VERSION "created by canmatrix"

NS_ :

BS_:

BU_: BDC_Body CHC DME1 EME FLA NiVi ZGW Kombi Kombi_Basis Diagnosetool_FA_CAN CDC_ZGW DME2 ELV Gliwa_T1_Host FA_CAN_Dummy

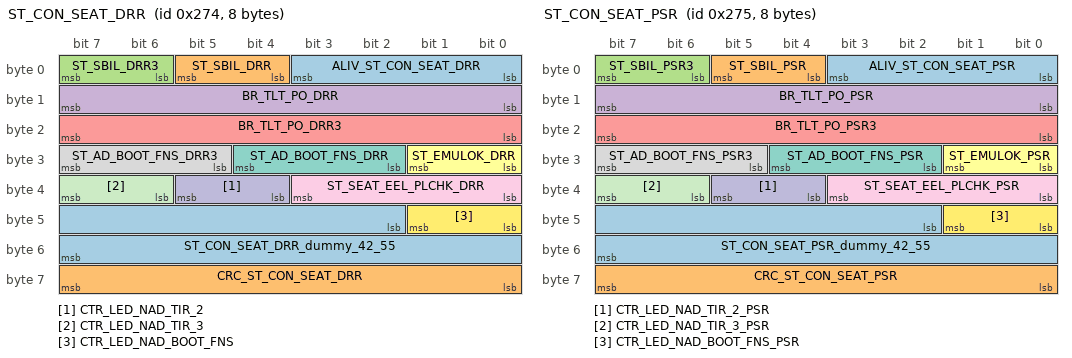
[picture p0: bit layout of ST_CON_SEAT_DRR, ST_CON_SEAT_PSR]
BO_ 628 ST_CON_SEAT_DRR: 8 ZGW
 SG_ ALIV_ST_CON_SEAT_DRR : 0|4@1+ (1,0) [0|14] "This unit fulfills the required AUTOSAR reference to a unit. No real unit is defined." Vector__XXX
 SG_ ST_SBIL_DRR : 4|2@1+ (1,0) [0|3] "" Vector__XXX
 SG_ ST_SBIL_DRR3 : 6|2@1+ (1,0) [0|3] "" Vector__XXX
 SG_ BR_TLT_PO_DRR : 8|8@1+ (1,0) [0|150] "%" Vector__XXX
 SG_ BR_TLT_PO_DRR3 : 16|8@1+ (1,0) [0|150] "%" Vector__XXX
 SG_ ST_EMULOK_DRR : 24|2@1+ (1,0) [0|3] "" Vector__XXX
 SG_ ST_AD_BOOT_FNS_DRR : 26|3@1+ (1,0) [0|7] "" Vector__XXX
 SG_ ST_AD_BOOT_FNS_DRR3 : 29|3@1+ (1,0) [0|7] "" Vector__XXX
 SG_ ST_SEAT_EEL_PLCHK_DRR : 32|4@1+ (1,0) [0|15] "" Vector__XXX
 SG_ CTR_LED_NAD_TIR_2 : 36|2@1+ (1,0) [0|3] "" Vector__XXX
 SG_ CTR_LED_NAD_TIR_3 : 38|2@1+ (1,0) [0|3] "" Vector__XXX
 SG_ CTR_LED_NAD_BOOT_FNS : 40|2@1+ (1,0) [0|3] "" Vector__XXX
 SG_ ST_CON_SEAT_DRR_dummy_42_55 : 42|14@1+ (1,0) [-8192|8191] "" Vector__XXX
 SG_ CRC_ST_CON_SEAT_DRR : 56|8@1+ (1,0) [0|255] "This unit fulfills the required AUTOSAR reference to a unit. No real unit is defined." Vector__XXX

BO_ 629 ST_CON_SEAT_PSR: 8 ZGW
 SG_ ALIV_ST_CON_SEAT_PSR : 0|4@1+ (1,0) [0|14] "This unit fulfills the required AUTOSAR reference to a unit. No real unit is defined." Vector__XXX
 SG_ ST_SBIL_PSR : 4|2@1+ (1,0) [0|3] "" Vector__XXX
 SG_ ST_SBIL_PSR3 : 6|2@1+ (1,0) [0|3] "" Vector__XXX
 SG_ BR_TLT_PO_PSR : 8|8@1+ (1,0) [0|150] "%" Vector__XXX
 SG_ BR_TLT_PO_PSR3 : 16|8@1+ (1,0) [0|150] "%" Vector__XXX
 SG_ ST_EMULOK_PSR : 24|2@1+ (1,0) [0|3] "" Vector__XXX
 SG_ ST_AD_BOOT_FNS_PSR : 26|3@1+ (1,0) [0|7] "" Vector__XXX
 SG_ ST_AD_BOOT_FNS_PSR3 : 29|3@1+ (1,0) [0|7] "" Vector__XXX
 SG_ ST_SEAT_EEL_PLCHK_PSR : 32|4@1+ (1,0) [0|15] "" Vector__XXX
 SG_ CTR_LED_NAD_TIR_2_PSR : 36|2@1+ (1,0) [0|3] "" Vector__XXX
 SG_ CTR_LED_NAD_TIR_3_PSR : 38|2@1+ (1,0) [0|3] "" Vector__XXX
 SG_ CTR_LED_NAD_BOOT_FNS_PSR : 40|2@1+ (1,0) [0|3] "" Vector__XXX
 SG_ ST_CON_SEAT_PSR_dummy_42_55 : 42|14@1+ (1,0) [-8192|8191] "" Vector__XXX
 SG_ CRC_ST_CON_SEAT_PSR : 56|8@1+ (1,0) [0|255] "This unit fulfills the required AUTOSAR reference to a unit. No real unit is defined." Vector__XXX

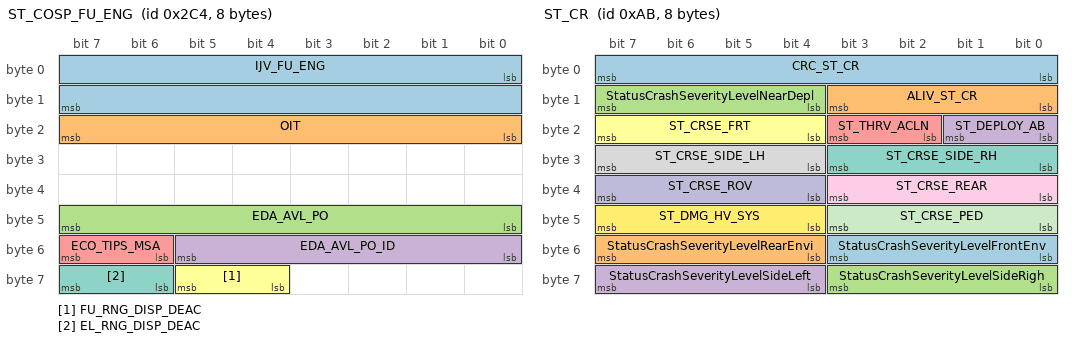
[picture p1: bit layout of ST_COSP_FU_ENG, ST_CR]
BO_ 708 ST_COSP_FU_ENG: 8 DME1
 SG_ IJV_FU_ENG : 0|16@1+ (1,0) [0|65534] "µl" CDC_ZGW,Kombi,Kombi_Basis,ZGW
 SG_ OIT : 16|8@1+ (0.5,0) [0|50] "%" ZGW,Kombi,Kombi_Basis
 SG_ EDA_AVL_PO : 40|8@1+ (1,-100) [-200|0] "%" Kombi,Kombi_Basis
 SG_ EDA_AVL_PO_ID : 48|6@1+ (1,0) [0|63] "" Kombi,Kombi_Basis
 SG_ ECO_TIPS_MSA : 54|2@1+ (1,0) [0|3] "" Kombi,Kombi_Basis
 SG_ FU_RNG_DISP_DEAC : 60|2@1+ (1,0) [0|3] "" Kombi
 SG_ EL_RNG_DISP_DEAC : 62|2@1+ (1,0) [0|3] "" Kombi

BO_ 171 ST_CR: 8 ZGW
 SG_ CRC_ST_CR : 0|8@1+ (1,0) [0|255] "This unit fulfills the required AUTOSAR reference to a unit. No real unit is defined." Vector__XXX
 SG_ ALIV_ST_CR : 8|4@1+ (1,0) [0|14] "This unit fulfills the required AUTOSAR reference to a unit. No real unit is defined." Vector__XXX
 SG_ StatusCrashSeverityLevelNearDepl : 12|4@1+ (1,0) [0|15] "" Vector__XXX
 SG_ ST_DEPLOY_AB : 16|2@1+ (1,0) [0|3] "" Vector__XXX
 SG_ ST_THRV_ACLN : 18|2@1+ (1,0) [0|3] "" Vector__XXX
 SG_ ST_CRSE_FRT : 20|4@1+ (1,0) [0|15] "" Vector__XXX
 SG_ ST_CRSE_SIDE_RH : 24|4@1+ (1,0) [0|15] "" Vector__XXX
 SG_ ST_CRSE_SIDE_LH : 28|4@1+ (1,0) [0|15] "" Vector__XXX
 SG_ ST_CRSE_REAR : 32|4@1+ (1,0) [0|15] "" Vector__XXX
 SG_ ST_CRSE_ROV : 36|4@1+ (1,0) [0|15] "" Vector__XXX
 SG_ ST_CRSE_PED : 40|4@1+ (1,0) [0|15] "" Vector__XXX
 SG_ ST_DMG_HV_SYS : 44|4@1+ (1,0) [0|15] "" Vector__XXX
 SG_ StatusCrashSeverityLevelFrontEnv : 48|4@1+ (1,0) [0|15] "" Vector__XXX
 SG_ StatusCrashSeverityLevelRearEnvi : 52|4@1+ (1,0) [0|15] "" Vector__XXX
 SG_ StatusCrashSeverityLevelSideRigh : 56|4@1+ (1,0) [0|15] "" Vector__XXX
 SG_ StatusCrashSeverityLevelSideLeft : 60|4@1+ (1,0) [0|15] "" Vector__XXX

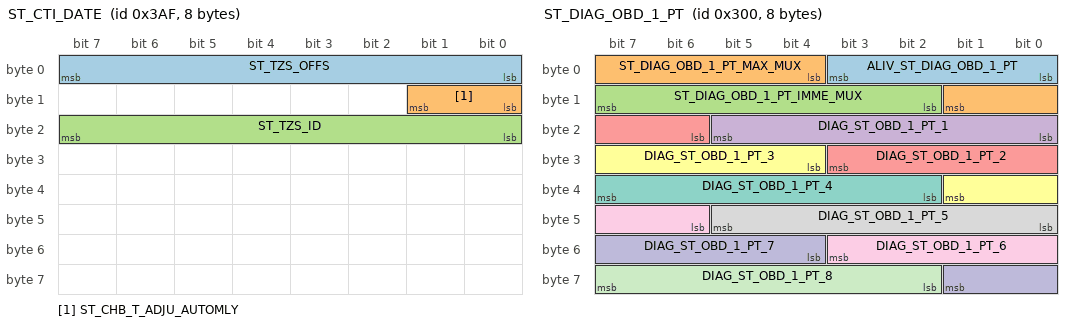
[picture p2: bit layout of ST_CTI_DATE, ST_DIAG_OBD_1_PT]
BO_ 943 ST_CTI_DATE: 8 Kombi
 SG_ ST_TZS_OFFS : 0|8@1+ (0.25,-20) [-25.00|-9.25] "h" ZGW
 SG_ ST_CHB_T_ADJU_AUTOMLY : 8|2@1+ (1,0) [0|3] "" ZGW
 SG_ ST_TZS_ID : 16|8@1+ (1,0) [0|251] "This unit fulfills the required AUTOSAR reference to a unit. No real unit is defined." ZGW

BO_ 768 ST_DIAG_OBD_1_PT: 8 ZGW
 SG_ ALIV_ST_DIAG_OBD_1_PT : 0|4@1+ (1,0) [0|14] "This unit fulfills the required AUTOSAR reference to a unit. No real unit is defined." Vector__XXX
 SG_ ST_DIAG_OBD_1_PT_MAX_MUX : 4|6@1+ (1,0) [4|60] "This unit fulfills the required AUTOSAR reference to a unit. No real unit is defined." Vector__XXX
 SG_ ST_DIAG_OBD_1_PT_IMME_MUX : 10|6@1+ (1,0) [0|60] "This unit fulfills the required AUTOSAR reference to a unit. No real unit is defined." Vector__XXX
 SG_ DIAG_ST_OBD_1_PT_1 : 16|6@1+ (1,0) [0|63] "This unit fulfills the required AUTOSAR reference to a unit. No real unit is defined." Vector__XXX
 SG_ DIAG_ST_OBD_1_PT_2 : 22|6@1+ (1,0) [0|63] "This unit fulfills the required AUTOSAR reference to a unit. No real unit is defined." Vector__XXX
 SG_ DIAG_ST_OBD_1_PT_3 : 28|6@1+ (1,0) [0|63] "This unit fulfills the required AUTOSAR reference to a unit. No real unit is defined." Vector__XXX
 SG_ DIAG_ST_OBD_1_PT_4 : 34|6@1+ (1,0) [0|63] "This unit fulfills the required AUTOSAR reference to a unit. No real unit is defined." Vector__XXX
 SG_ DIAG_ST_OBD_1_PT_5 : 40|6@1+ (1,0) [0|63] "This unit fulfills the required AUTOSAR reference to a unit. No real unit is defined." Vector__XXX
 SG_ DIAG_ST_OBD_1_PT_6 : 46|6@1+ (1,0) [0|63] "This unit fulfills the required AUTOSAR reference to a unit. No real unit is defined." Vector__XXX
 SG_ DIAG_ST_OBD_1_PT_7 : 52|6@1+ (1,0) [0|63] "This unit fulfills the required AUTOSAR reference to a unit. No real unit is defined." Vector__XXX
 SG_ DIAG_ST_OBD_1_PT_8 : 58|6@1+ (1,0) [0|63] "This unit fulfills the required AUTOSAR reference to a unit. No real unit is defined." Vector__XXX

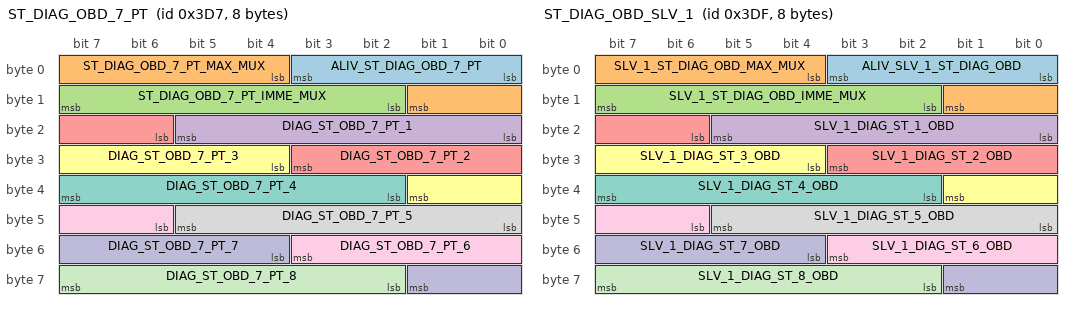
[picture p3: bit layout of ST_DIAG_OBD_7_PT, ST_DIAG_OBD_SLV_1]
BO_ 983 ST_DIAG_OBD_7_PT: 8 BDC_Body
 SG_ ALIV_ST_DIAG_OBD_7_PT : 0|4@1+ (1,0) [0|14] "This unit fulfills the required AUTOSAR reference to a unit. No real unit is defined." Vector__XXX
 SG_ ST_DIAG_OBD_7_PT_MAX_MUX : 4|6@1+ (1,0) [4|60] "This unit fulfills the required AUTOSAR reference to a unit. No real unit is defined." Vector__XXX
 SG_ ST_DIAG_OBD_7_PT_IMME_MUX : 10|6@1+ (1,0) [0|60] "This unit fulfills the required AUTOSAR reference to a unit. No real unit is defined." Vector__XXX
 SG_ DIAG_ST_OBD_7_PT_1 : 16|6@1+ (1,0) [0|63] "This unit fulfills the required AUTOSAR reference to a unit. No real unit is defined." Vector__XXX
 SG_ DIAG_ST_OBD_7_PT_2 : 22|6@1+ (1,0) [0|63] "This unit fulfills the required AUTOSAR reference to a unit. No real unit is defined." Vector__XXX
 SG_ DIAG_ST_OBD_7_PT_3 : 28|6@1+ (1,0) [0|63] "This unit fulfills the required AUTOSAR reference to a unit. No real unit is defined." Vector__XXX
 SG_ DIAG_ST_OBD_7_PT_4 : 34|6@1+ (1,0) [0|63] "This unit fulfills the required AUTOSAR reference to a unit. No real unit is defined." Vector__XXX
 SG_ DIAG_ST_OBD_7_PT_5 : 40|6@1+ (1,0) [0|63] "This unit fulfills the required AUTOSAR reference to a unit. No real unit is defined." Vector__XXX
 SG_ DIAG_ST_OBD_7_PT_6 : 46|6@1+ (1,0) [0|63] "This unit fulfills the required AUTOSAR reference to a unit. No real unit is defined." Vector__XXX
 SG_ DIAG_ST_OBD_7_PT_7 : 52|6@1+ (1,0) [0|63] "This unit fulfills the required AUTOSAR reference to a unit. No real unit is defined." Vector__XXX
 SG_ DIAG_ST_OBD_7_PT_8 : 58|6@1+ (1,0) [0|63] "This unit fulfills the required AUTOSAR reference to a unit. No real unit is defined." Vector__XXX

BO_ 991 ST_DIAG_OBD_SLV_1: 8 ZGW
 SG_ ALIV_SLV_1_ST_DIAG_OBD : 0|4@1+ (1,0) [0|14] "This unit fulfills the required AUTOSAR reference to a unit. No real unit is defined." Vector__XXX
 SG_ SLV_1_ST_DIAG_OBD_MAX_MUX : 4|6@1+ (1,0) [4|60] "This unit fulfills the required AUTOSAR reference to a unit. No real unit is defined." Vector__XXX
 SG_ SLV_1_ST_DIAG_OBD_IMME_MUX : 10|6@1+ (1,0) [4|60] "This unit fulfills the required AUTOSAR reference to a unit. No real unit is defined." Vector__XXX
 SG_ SLV_1_DIAG_ST_1_OBD : 16|6@1+ (1,0) [0|63] "This unit fulfills the required AUTOSAR reference to a unit. No real unit is defined." Vector__XXX
 SG_ SLV_1_DIAG_ST_2_OBD : 22|6@1+ (1,0) [0|63] "This unit fulfills the required AUTOSAR reference to a unit. No real unit is defined." Vector__XXX
 SG_ SLV_1_DIAG_ST_3_OBD : 28|6@1+ (1,0) [0|63] "This unit fulfills the required AUTOSAR reference to a unit. No real unit is defined." Vector__XXX
 SG_ SLV_1_DIAG_ST_4_OBD : 34|6@1+ (1,0) [0|63] "This unit fulfills the required AUTOSAR reference to a unit. No real unit is defined." Vector__XXX
 SG_ SLV_1_DIAG_ST_5_OBD : 40|6@1+ (1,0) [0|63] "This unit fulfills the required AUTOSAR reference to a unit. No real unit is defined." Vector__XXX
 SG_ SLV_1_DIAG_ST_6_OBD : 46|6@1+ (1,0) [0|63] "This unit fulfills the required AUTOSAR reference to a unit. No real unit is defined." Vector__XXX
 SG_ SLV_1_DIAG_ST_7_OBD : 52|6@1+ (1,0) [0|63] "This unit fulfills the required AUTOSAR reference to a unit. No real unit is defined." Vector__XXX
 SG_ SLV_1_DIAG_ST_8_OBD : 58|6@1+ (1,0) [0|63] "This unit fulfills the required AUTOSAR reference to a unit. No real unit is defined." Vector__XXX

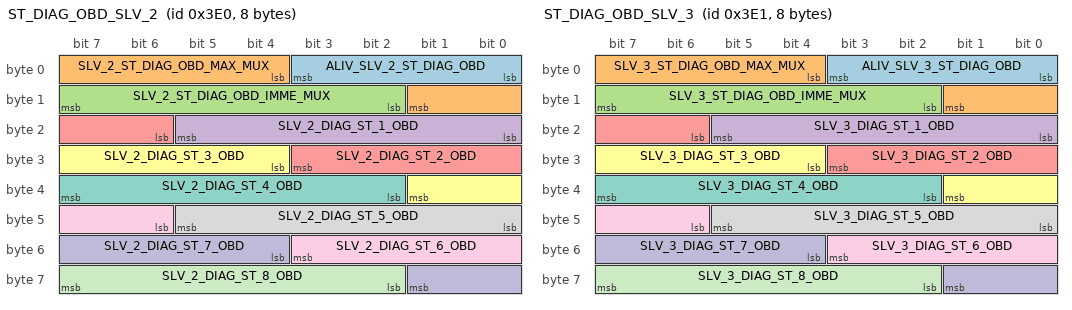
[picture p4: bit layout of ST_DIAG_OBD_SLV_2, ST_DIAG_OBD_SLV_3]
BO_ 992 ST_DIAG_OBD_SLV_2: 8 ZGW
 SG_ ALIV_SLV_2_ST_DIAG_OBD : 0|4@1+ (1,0) [0|14] "This unit fulfills the required AUTOSAR reference to a unit. No real unit is defined." Vector__XXX
 SG_ SLV_2_ST_DIAG_OBD_MAX_MUX : 4|6@1+ (1,0) [4|60] "This unit fulfills the required AUTOSAR reference to a unit. No real unit is defined." Vector__XXX
 SG_ SLV_2_ST_DIAG_OBD_IMME_MUX : 10|6@1+ (1,0) [4|60] "This unit fulfills the required AUTOSAR reference to a unit. No real unit is defined." Vector__XXX
 SG_ SLV_2_DIAG_ST_1_OBD : 16|6@1+ (1,0) [0|63] "This unit fulfills the required AUTOSAR reference to a unit. No real unit is defined." Vector__XXX
 SG_ SLV_2_DIAG_ST_2_OBD : 22|6@1+ (1,0) [0|63] "This unit fulfills the required AUTOSAR reference to a unit. No real unit is defined." Vector__XXX
 SG_ SLV_2_DIAG_ST_3_OBD : 28|6@1+ (1,0) [0|63] "This unit fulfills the required AUTOSAR reference to a unit. No real unit is defined." Vector__XXX
 SG_ SLV_2_DIAG_ST_4_OBD : 34|6@1+ (1,0) [0|63] "This unit fulfills the required AUTOSAR reference to a unit. No real unit is defined." Vector__XXX
 SG_ SLV_2_DIAG_ST_5_OBD : 40|6@1+ (1,0) [0|63] "This unit fulfills the required AUTOSAR reference to a unit. No real unit is defined." Vector__XXX
 SG_ SLV_2_DIAG_ST_6_OBD : 46|6@1+ (1,0) [0|63] "This unit fulfills the required AUTOSAR reference to a unit. No real unit is defined." Vector__XXX
 SG_ SLV_2_DIAG_ST_7_OBD : 52|6@1+ (1,0) [0|63] "This unit fulfills the required AUTOSAR reference to a unit. No real unit is defined." Vector__XXX
 SG_ SLV_2_DIAG_ST_8_OBD : 58|6@1+ (1,0) [0|63] "This unit fulfills the required AUTOSAR reference to a unit. No real unit is defined." Vector__XXX

BO_ 993 ST_DIAG_OBD_SLV_3: 8 ZGW
 SG_ ALIV_SLV_3_ST_DIAG_OBD : 0|4@1+ (1,0) [0|14] "This unit fulfills the required AUTOSAR reference to a unit. No real unit is defined." EME
 SG_ SLV_3_ST_DIAG_OBD_MAX_MUX : 4|6@1+ (1,0) [4|60] "This unit fulfills the required AUTOSAR reference to a unit. No real unit is defined." EME
 SG_ SLV_3_ST_DIAG_OBD_IMME_MUX : 10|6@1+ (1,0) [4|60] "This unit fulfills the required AUTOSAR reference to a unit. No real unit is defined." EME
 SG_ SLV_3_DIAG_ST_1_OBD : 16|6@1+ (1,0) [0|63] "This unit fulfills the required AUTOSAR reference to a unit. No real unit is defined." EME
 SG_ SLV_3_DIAG_ST_2_OBD : 22|6@1+ (1,0) [0|63] "This unit fulfills the required AUTOSAR reference to a unit. No real unit is defined." EME
 SG_ SLV_3_DIAG_ST_3_OBD : 28|6@1+ (1,0) [0|63] "This unit fulfills the required AUTOSAR reference to a unit. No real unit is defined." EME
 SG_ SLV_3_DIAG_ST_4_OBD : 34|6@1+ (1,0) [0|63] "This unit fulfills the required AUTOSAR reference to a unit. No real unit is defined." EME
 SG_ SLV_3_DIAG_ST_5_OBD : 40|6@1+ (1,0) [0|63] "This unit fulfills the required AUTOSAR reference to a unit. No real unit is defined." EME
 SG_ SLV_3_DIAG_ST_6_OBD : 46|6@1+ (1,0) [0|63] "This unit fulfills the required AUTOSAR reference to a unit. No real unit is defined." EME
 SG_ SLV_3_DIAG_ST_7_OBD : 52|6@1+ (1,0) [0|63] "This unit fulfills the required AUTOSAR reference to a unit. No real unit is defined." EME
 SG_ SLV_3_DIAG_ST_8_OBD : 58|6@1+ (1,0) [0|63] "This unit fulfills the required AUTOSAR reference to a unit. No real unit is defined." EME

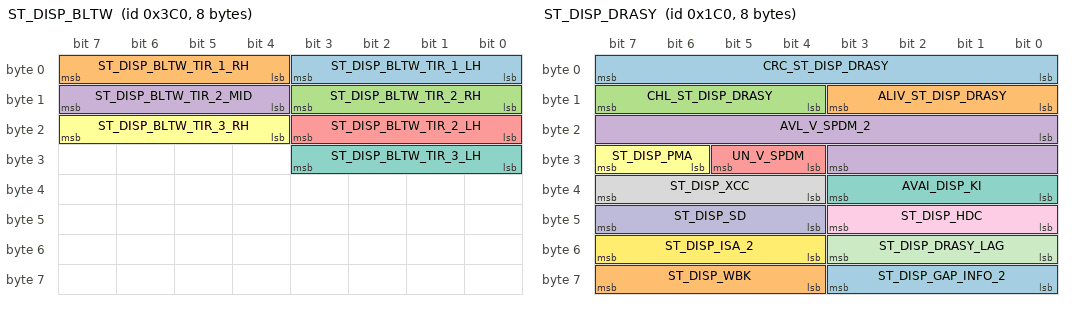
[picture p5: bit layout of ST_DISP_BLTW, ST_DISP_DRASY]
BO_ 960 ST_DISP_BLTW: 8 ZGW
 SG_ ST_DISP_BLTW_TIR_1_LH : 0|4@1+ (1,0) [0|15] "" Kombi
 SG_ ST_DISP_BLTW_TIR_1_RH : 4|4@1+ (1,0) [0|15] "" Kombi
 SG_ ST_DISP_BLTW_TIR_2_RH : 8|4@1+ (1,0) [0|15] "" Kombi
 SG_ ST_DISP_BLTW_TIR_2_MID : 12|4@1+ (1,0) [0|15] "" Kombi
 SG_ ST_DISP_BLTW_TIR_2_LH : 16|4@1+ (1,0) [0|15] "" Kombi
 SG_ ST_DISP_BLTW_TIR_3_RH : 20|4@1+ (1,0) [0|15] "" Kombi
 SG_ ST_DISP_BLTW_TIR_3_LH : 24|4@1+ (1,0) [0|15] "" Kombi

BO_ 448 ST_DISP_DRASY: 8 Kombi
 SG_ CRC_ST_DISP_DRASY : 0|8@1+ (1,0) [0|255] "This unit fulfills the required AUTOSAR reference to a unit. No real unit is defined." Vector__XXX
 SG_ ALIV_ST_DISP_DRASY : 8|4@1+ (1,0) [0|14] "This unit fulfills the required AUTOSAR reference to a unit. No real unit is defined." Vector__XXX
 SG_ CHL_ST_DISP_DRASY : 12|4@1+ (1,0) [0|14] "This unit fulfills the required AUTOSAR reference to a unit. No real unit is defined." Vector__XXX
 SG_ AVL_V_SPDM_2 : 16|12@1+ (0.1,0) [0|40.92] "km/h" Vector__XXX
 SG_ UN_V_SPDM : 28|2@1+ (1,0) [0|3] "" Vector__XXX
 SG_ ST_DISP_PMA : 30|2@1+ (1,0) [0|3] "" Vector__XXX
 SG_ AVAI_DISP_KI : 32|4@1+ (1,0) [0|15] "" Vector__XXX
 SG_ ST_DISP_XCC : 36|4@1+ (1,0) [0|15] "" Vector__XXX
 SG_ ST_DISP_HDC : 40|4@1+ (1,0) [0|15] "" Vector__XXX
 SG_ ST_DISP_SD : 44|4@1+ (1,0) [0|15] "" Vector__XXX
 SG_ ST_DISP_DRASY_LAG : 48|4@1+ (1,0) [0|15] "" Vector__XXX
 SG_ ST_DISP_ISA_2 : 52|4@1+ (1,0) [0|15] "" Vector__XXX
 SG_ ST_DISP_GAP_INFO_2 : 56|4@1+ (1,0) [0|15] "" Vector__XXX
 SG_ ST_DISP_WBK : 60|4@1+ (1,0) [0|15] "" Vector__XXX

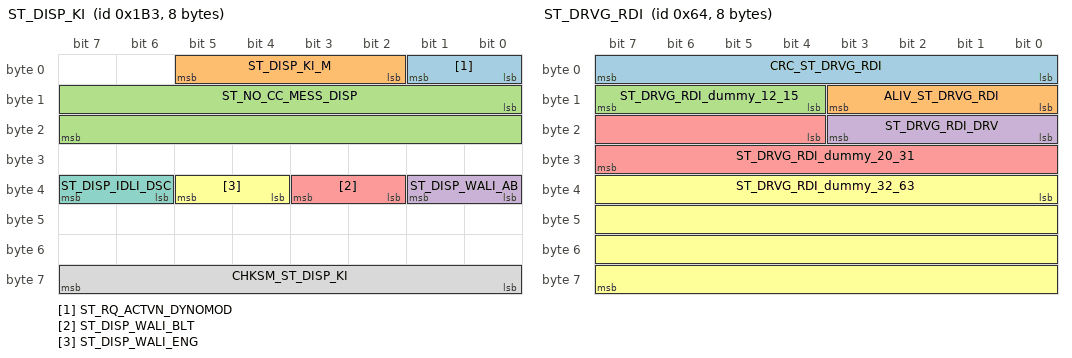
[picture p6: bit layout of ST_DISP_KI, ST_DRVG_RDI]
BO_ 435 ST_DISP_KI: 8 Kombi
 SG_ ST_RQ_ACTVN_DYNOMOD : 0|2@1+ (1,0) [0|3] "" Vector__XXX
 SG_ ST_DISP_KI_M : 2|4@1+ (1,0) [0|15] "" Vector__XXX
 SG_ ST_NO_CC_MESS_DISP : 8|16@1+ (1,0) [0|65534] "This unit fulfills the required AUTOSAR reference to a unit. No real unit is defined." Vector__XXX
 SG_ ST_DISP_WALI_AB : 32|2@1+ (1,0) [0|3] "" Vector__XXX
 SG_ ST_DISP_WALI_BLT : 34|2@1+ (1,0) [0|3] "" Vector__XXX
 SG_ ST_DISP_WALI_ENG : 36|2@1+ (1,0) [0|3] "" Vector__XXX
 SG_ ST_DISP_IDLI_DSC : 38|2@1+ (1,0) [0|3] "" Vector__XXX
 SG_ CHKSM_ST_DISP_KI : 56|8@1+ (1,0) [0|255] "" Vector__XXX

BO_ 100 ST_DRVG_RDI: 8 DME1
 SG_ CRC_ST_DRVG_RDI : 0|8@1+ (1,0) [0|255] "This unit fulfills the required AUTOSAR reference to a unit. No real unit is defined." Vector__XXX
 SG_ ALIV_ST_DRVG_RDI : 8|4@1+ (1,0) [0|14] "This unit fulfills the required AUTOSAR reference to a unit. No real unit is defined." Vector__XXX
 SG_ ST_DRVG_RDI_dummy_12_15 : 12|4@1+ (1,0) [-8|7] "" Vector__XXX
 SG_ ST_DRVG_RDI_DRV : 16|4@1+ (1,0) [0|15] "" Vector__XXX
 SG_ ST_DRVG_RDI_dummy_20_31 : 20|12@1+ (1,0) [-2048|2047] "" Vector__XXX
 SG_ ST_DRVG_RDI_dummy_32_63 : 32|32@1+ (1,0) [-2147483648|2147483647] "" Vector__XXX

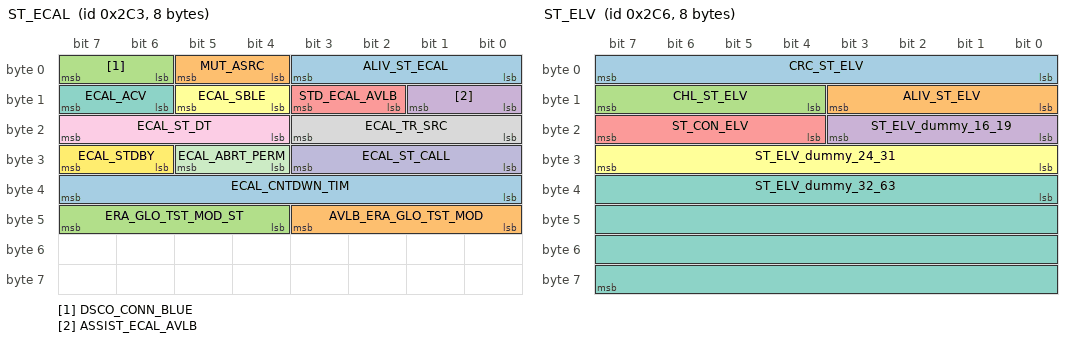
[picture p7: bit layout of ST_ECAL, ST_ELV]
BO_ 707 ST_ECAL: 8 ZGW
 SG_ ALIV_ST_ECAL : 0|4@1+ (1,0) [0|14] "This unit fulfills the required AUTOSAR reference to a unit. No real unit is defined." Kombi,Kombi_Basis
 SG_ MUT_ASRC : 4|2@1+ (1,0) [0|3] "" Kombi
 SG_ DSCO_CONN_BLUE : 6|2@1+ (1,0) [0|3] "" Kombi
 SG_ ASSIST_ECAL_AVLB : 8|2@1+ (1,0) [0|3] "" Kombi
 SG_ STD_ECAL_AVLB : 10|2@1+ (1,0) [0|3] "" Kombi
 SG_ ECAL_SBLE : 12|2@1+ (1,0) [0|3] "" Kombi
 SG_ ECAL_ACV : 14|2@1+ (1,0) [0|3] "" Kombi,BDC_Body
 SG_ ECAL_TR_SRC : 16|4@1+ (1,0) [0|15] "" Kombi
 SG_ ECAL_ST_DT : 20|4@1+ (1,0) [0|15] "" Kombi
 SG_ ECAL_ST_CALL : 24|4@1+ (1,0) [0|15] "" Kombi
 SG_ ECAL_ABRT_PERM : 28|2@1+ (1,0) [0|3] "" Kombi
 SG_ ECAL_STDBY : 30|2@1+ (1,0) [0|3] "" Kombi,BDC_Body
 SG_ ECAL_CNTDWN_TIM : 32|8@1+ (1,0) [0|254] "s" Kombi
 SG_ AVLB_ERA_GLO_TST_MOD : 40|4@1+ (1,0) [0|15] "" Kombi
 SG_ ERA_GLO_TST_MOD_ST : 44|4@1+ (1,0) [0|15] "" Kombi

BO_ 710 ST_ELV: 8 ELV
 SG_ CRC_ST_ELV : 0|8@1+ (1,0) [0|255] "This unit fulfills the required AUTOSAR reference to a unit. No real unit is defined." Vector__XXX
 SG_ ALIV_ST_ELV : 8|4@1+ (1,0) [0|14] "This unit fulfills the required AUTOSAR reference to a unit. No real unit is defined." Vector__XXX
 SG_ CHL_ST_ELV : 12|4@1+ (1,0) [0|14] "This unit fulfills the required AUTOSAR reference to a unit. No real unit is defined." Vector__XXX
 SG_ ST_ELV_dummy_16_19 : 16|4@1+ (1,0) [-8|7] "" Vector__XXX
 SG_ ST_CON_ELV : 20|4@1+ (1,0) [0|15] "" Vector__XXX
 SG_ ST_ELV_dummy_24_31 : 24|8@1+ (1,0) [-128|127] "" Vector__XXX
 SG_ ST_ELV_dummy_32_63 : 32|32@1+ (1,0) [-2147483648|2147483647] "" Vector__XXX

BO_ 442 ST_ENERG_GEN: 8 ZGW
 SG_ ST_LDREL_GEN : 56|4@1+ (1,0) [0|15] "" ELV

BO_ 912 ST_FN_HOSP: 4 Vector__XXX
 SG_ ST_HOSP_FN : 0|4@1+ (1,0) [0|15] "" Kombi

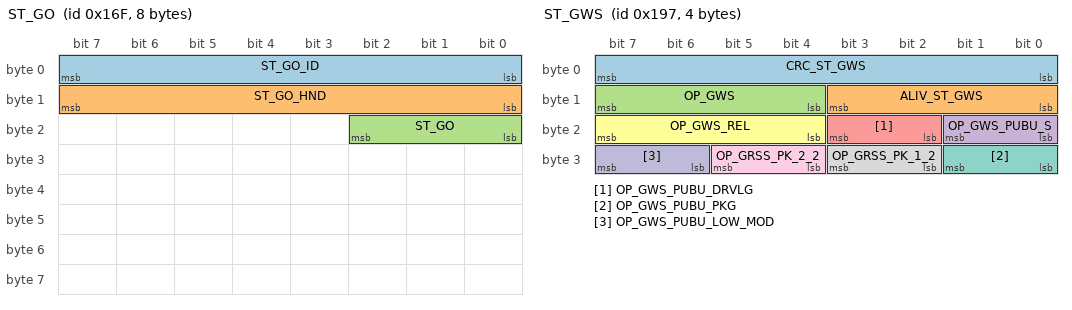
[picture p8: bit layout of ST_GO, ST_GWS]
BO_ 367 ST_GO: 8 ZGW
 SG_ ST_GO_ID : 0|8@1+ (1,0) [0|252] "This unit fulfills the required AUTOSAR reference to a unit. No real unit is defined." Kombi,Kombi_Basis
 SG_ ST_GO_HND : 8|8@1+ (1,0) [0|252] "This unit fulfills the required AUTOSAR reference to a unit. No real unit is defined." Kombi,Kombi_Basis
 SG_ ST_GO : 16|3@1+ (1,0) [0|7] "" Kombi,Kombi_Basis

BO_ 407 ST_GWS: 4 DME1
 SG_ CRC_ST_GWS : 0|8@1+ (1,0) [0|255] "This unit fulfills the required AUTOSAR reference to a unit. No real unit is defined." Vector__XXX
 SG_ ALIV_ST_GWS : 8|4@1+ (1,0) [0|14] "This unit fulfills the required AUTOSAR reference to a unit. No real unit is defined." Vector__XXX
 SG_ OP_GWS : 12|4@1+ (1,0) [0|15] "" Vector__XXX
 SG_ OP_GWS_PUBU_S : 16|2@1+ (1,0) [0|3] "" Vector__XXX
 SG_ OP_GWS_PUBU_DRVLG : 18|2@1+ (1,0) [0|3] "" Vector__XXX
 SG_ OP_GWS_REL : 20|4@1+ (1,0) [0|15] "" Vector__XXX
 SG_ OP_GWS_PUBU_PKG : 24|2@1+ (1,0) [0|3] "" Vector__XXX
 SG_ OP_GRSS_PK_1_2 : 26|2@1+ (1,0) [0|3] "" Vector__XXX
 SG_ OP_GRSS_PK_2_2 : 28|2@1+ (1,0) [0|3] "" Vector__XXX
 SG_ OP_GWS_PUBU_LOW_MOD : 30|2@1+ (1,0) [0|3] "" Vector__XXX

BO_ 446 ST_GZA_LH: 2 BDC_Body
 SG_ ALIV_ST_GZA_LH : 0|4@1+ (1,0) [0|15] "" NiVi
 SG_ ST_GZA_LH : 4|2@1+ (1,0) [0|3] "" NiVi

BO_ 471 ST_GZA_RH: 2 BDC_Body
 SG_ ALIV_ST_GZA_RH : 0|4@1+ (1,0) [0|15] "" NiVi
 SG_ ST_GZA_RH : 4|2@1+ (1,0) [0|3] "" NiVi

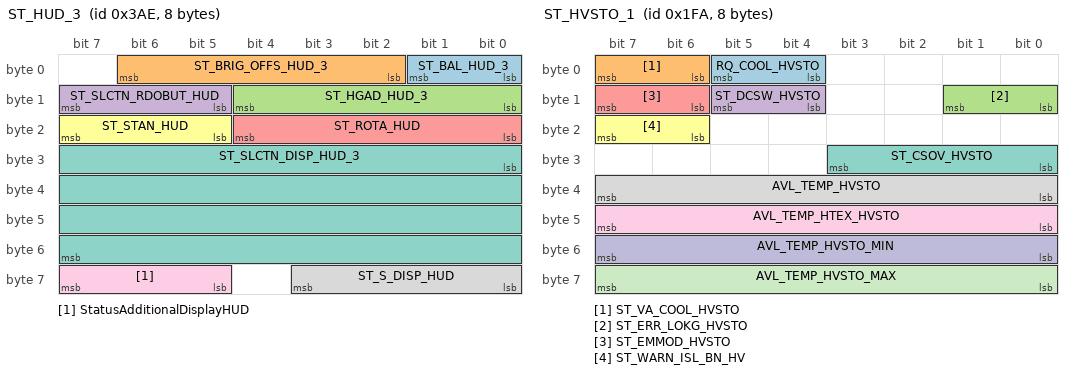
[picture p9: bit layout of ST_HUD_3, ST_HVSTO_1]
BO_ 942 ST_HUD_3: 8 Kombi
 SG_ ST_BAL_HUD_3 : 0|2@1+ (1,0) [0|3] "" ZGW
 SG_ ST_BRIG_OFFS_HUD_3 : 2|5@1+ (1,0) [0|31] "" ZGW
 SG_ ST_HGAD_HUD_3 : 8|5@1+ (1,0) [0|31] "" ZGW
 SG_ ST_SLCTN_RDOBUT_HUD : 13|3@1+ (1,0) [0|7] "" ZGW
 SG_ ST_ROTA_HUD : 16|5@1+ (1,0) [0|31] "" ZGW
 SG_ ST_STAN_HUD : 21|3@1+ (1,0) [0|7] "" ZGW
 SG_ ST_SLCTN_DISP_HUD_3 : 24|32@1+ (1,0) [0|4294967295] "" ZGW
 SG_ ST_S_DISP_HUD : 56|4@1+ (1,0) [0|15] "" ZGW
 SG_ StatusAdditionalDisplayHUD : 61|3@1+ (1,0) [0|7] "" ZGW

BO_ 832 ST_HVBT_WU: 2 EME
 SG_ ST_HVBT_PROTE_WU : 0|2@1+ (1,0) [0|3] "" ZGW
 SG_ StatusHVBatteryPassengerSafety : 2|2@1+ (1,0) [0|3] "" ZGW,BDC_Body

BO_ 506 ST_HVSTO_1: 8 EME
 SG_ RQ_COOL_HVSTO : 4|2@1+ (1,0) [0|3] "" ZGW
 SG_ ST_VA_COOL_HVSTO : 6|2@1+ (1,0) [0|3] "" ZGW
 SG_ ST_ERR_LOKG_HVSTO : 8|2@1+ (1,0) [0|3] "" CDC_ZGW
 SG_ ST_DCSW_HVSTO : 12|2@1+ (1,0) [0|3] "" CDC_ZGW
 SG_ ST_EMMOD_HVSTO : 14|2@1+ (1,0) [0|3] "" CDC_ZGW
 SG_ ST_WARN_ISL_BN_HV : 22|2@1+ (1,0) [0|3] "" CDC_ZGW
 SG_ ST_CSOV_HVSTO : 24|4@1+ (1,0) [0|15] "" ZGW
 SG_ AVL_TEMP_HVSTO : 32|8@1+ (1,-50) [-50|204] "°C" CDC_ZGW,ZGW
 SG_ AVL_TEMP_HTEX_HVSTO : 40|8@1+ (1,-50) [-50|204] "°C" ZGW
 SG_ AVL_TEMP_HVSTO_MIN : 48|8@1+ (1,-50) [-50|202] "°C" CDC_ZGW,ZGW
 SG_ AVL_TEMP_HVSTO_MAX : 56|8@1+ (1,-50) [-50|202] "°C" CDC_ZGW,ZGW

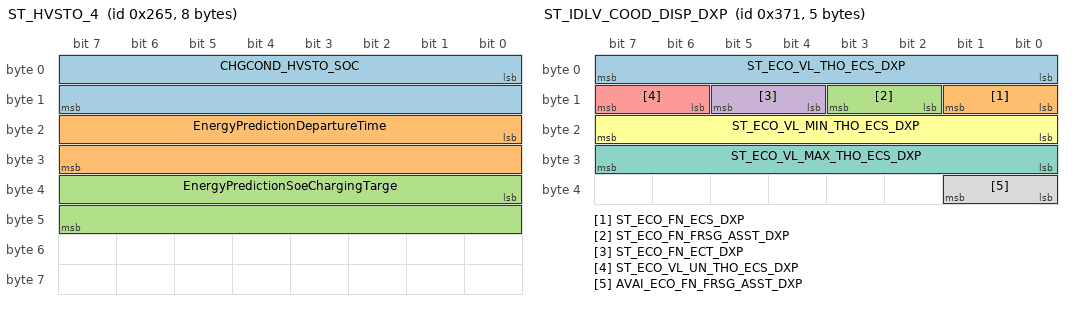
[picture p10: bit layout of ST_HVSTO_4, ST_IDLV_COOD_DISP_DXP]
BO_ 613 ST_HVSTO_4: 8 EME
 SG_ CHGCOND_HVSTO_SOC : 0|16@1+ (0.0016,0) [0.0000|0.1600] "%" CDC_ZGW,ZGW
 SG_ EnergyPredictionDepartureTime : 16|16@1+ (0.01,-50) [-50.50|-44.00] "kWh" Kombi
 SG_ EnergyPredictionSoeChargingTarge : 32|16@1+ (0.01,-50) [-50.50|-44.00] "kWh" Kombi

BO_ 795 ST_IDLV_COOD_DBE_DXP: 6 ZGW
 SG_ DISP_ST_DSC_2 : 16|4@1+ (1,0) [0|15] "" Kombi,Kombi_Basis

BO_ 444 ST_IDLV_COOD_DBE_DXP_B: 6 ZGW
 SG_ DISP_ST_DSC_2 : 16|4@1+ (1,0) [0|15] "" Kombi

BO_ 881 ST_IDLV_COOD_DISP_DXP: 5 Kombi
 SG_ ST_ECO_VL_THO_ECS_DXP : 0|8@1+ (1,0) [0|250] "This unit fulfills the required AUTOSAR reference to a unit. No real unit is defined." ZGW
 SG_ ST_ECO_FN_ECS_DXP : 8|2@1+ (1,0) [0|3] "" ZGW
 SG_ ST_ECO_FN_FRSG_ASST_DXP : 10|2@1+ (1,0) [0|3] "" ZGW
 SG_ ST_ECO_FN_ECT_DXP : 12|2@1+ (1,0) [0|3] "" ZGW
 SG_ ST_ECO_VL_UN_THO_ECS_DXP : 14|2@1+ (1,0) [0|3] "" ZGW
 SG_ ST_ECO_VL_MIN_THO_ECS_DXP : 16|8@1+ (1,0) [0|250] "This unit fulfills the required AUTOSAR reference to a unit. No real unit is defined." ZGW
 SG_ ST_ECO_VL_MAX_THO_ECS_DXP : 24|8@1+ (1,0) [0|250] "This unit fulfills the required AUTOSAR reference to a unit. No real unit is defined." ZGW
 SG_ AVAI_ECO_FN_FRSG_ASST_DXP : 32|2@1+ (1,0) [0|3] "" ZGW

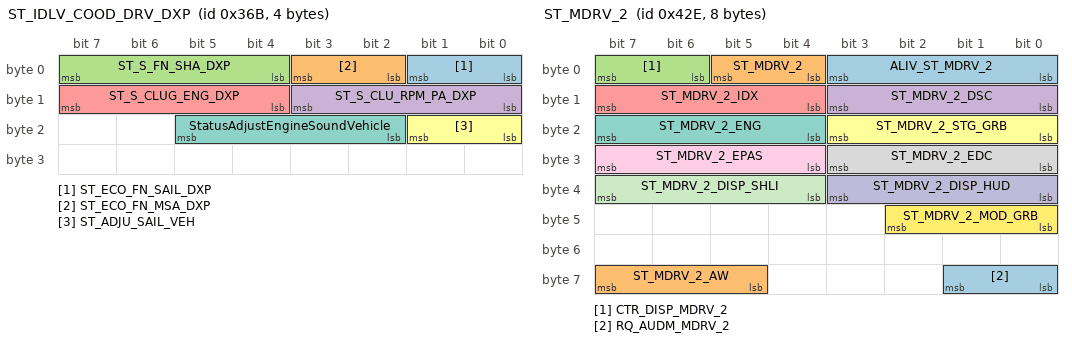
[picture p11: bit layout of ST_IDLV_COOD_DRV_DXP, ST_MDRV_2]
BO_ 875 ST_IDLV_COOD_DRV_DXP: 4 DME1
 SG_ ST_ECO_FN_SAIL_DXP : 0|2@1+ (1,0) [0|3] "" ZGW
 SG_ ST_ECO_FN_MSA_DXP : 2|2@1+ (1,0) [0|3] "" ZGW
 SG_ ST_S_FN_SHA_DXP : 4|4@1+ (1,0) [0|15] "" ZGW
 SG_ ST_S_CLU_RPM_PA_DXP : 8|4@1+ (1,0) [0|15] "" ZGW
 SG_ ST_S_CLUG_ENG_DXP : 12|4@1+ (1,0) [0|15] "" ZGW
 SG_ ST_ADJU_SAIL_VEH : 16|2@1+ (1,0) [0|3] "" ZGW
 SG_ StatusAdjustEngineSoundVehicle : 18|4@1+ (1,0) [0|15] "" ZGW

BO_ 572 ST_IDT_CHGNG_CA: 8 EME
 SG_ ST_SWO_IDT_CHGNG_CA : 0|4@1+ (1,0) [0|15] "" BDC_Body
 SG_ ST_POSI_IDT_CHGNG_CA : 4|4@1+ (1,0) [0|15] "" BDC_Body

BO_ 656 ST_KEY_SRCH: 8 ZGW
 SG_ ST_KEY_SRCH_INO : 0|4@1+ (1,0) [0|15] "" ELV
 SG_ ID_FN_RSLT_KEY_SRCH : 8|8@1+ (1,0) [0|255] "" ELV

BO_ 874 ST_MAB_ASST: 2 BDC_Body
 SG_ DISP_MAB_ASST : 0|2@1+ (1,0) [0|3] "" ZGW,Kombi,Kombi_Basis,FLA
 SG_ RQ_OP_MAB_ASST : 2|2@1+ (1,0) [0|3] "" ZGW,FLA

BO_ 1070 ST_MDRV_2: 8 DME1
 SG_ ALIV_ST_MDRV_2 : 0|4@1+ (1,0) [0|15] "" Kombi,Kombi_Basis
 SG_ ST_MDRV_2 : 4|2@1+ (1,0) [0|3] "" ZGW,Kombi,Kombi_Basis
 SG_ CTR_DISP_MDRV_2 : 6|2@1+ (1,0) [0|3] "" ZGW
 SG_ ST_MDRV_2_DSC : 8|4@1+ (1,0) [0|15] "" ZGW,Kombi,Kombi_Basis
 SG_ ST_MDRV_2_IDX : 12|4@1+ (1,0) [0|15] "" ZGW,Kombi,Kombi_Basis
 SG_ ST_MDRV_2_STG_GRB : 16|4@1+ (1,0) [0|15] "" ZGW,Kombi,Kombi_Basis
 SG_ ST_MDRV_2_ENG : 20|4@1+ (1,0) [0|15] "" ZGW
 SG_ ST_MDRV_2_EDC : 24|4@1+ (1,0) [0|15] "" ZGW
 SG_ ST_MDRV_2_EPAS : 28|4@1+ (1,0) [0|15] "" ZGW
 SG_ ST_MDRV_2_DISP_HUD : 32|4@1+ (1,0) [0|15] "" ZGW,Kombi,Kombi_Basis
 SG_ ST_MDRV_2_DISP_SHLI : 36|4@1+ (1,0) [0|15] "" ZGW,Kombi,Kombi_Basis
 SG_ ST_MDRV_2_MOD_GRB : 40|3@1+ (1,0) [0|7] "" ZGW,Kombi,Kombi_Basis
 SG_ RQ_AUDM_MDRV_2 : 56|2@1+ (1,0) [0|3] "" ZGW
 SG_ ST_MDRV_2_AW : 61|3@1+ (1,0) [0|7] "" ZGW

BO_ 1029 ST_MDRV_3: 8 DME1
 SG_ ST_MDRV_3_IDX : 0|4@1+ (1,0) [0|15] "" ZGW
 SG_ ST_MDRV_3_DRVGMOD : 4|4@1+ (1,0) [0|15] "" ZGW
 SG_ ST_MDRV_3 : 8|2@1+ (1,0) [0|3] "" ZGW,Kombi
 SG_ ST_MDRV_3_DISP_KI_HUD : 10|6@1+ (1,0) [0|63] "" ZGW,Kombi
 SG_ ST_MDRV_3_SOU : 16|2@1+ (1,0) [0|3] "" ZGW
 SG_ ST_MDRV_3_MSA : 18|2@1+ (1,0) [0|3] "" ZGW
 SG_ ST_MDRV_3_ASR : 20|2@1+ (1,0) [0|3] "" ZGW
 SG_ ST_MDRV_3_MUT : 22|2@1+ (1,0) [0|3] "" ZGW
 SG_ ST_MDRV_3_SAR : 24|4@1+ (1,0) [0|15] "" BDC_Body
 SG_ ST_MDRV_3_AMB : 28|4@1+ (1,0) [0|15] "" BDC_Body
 SG_ ST_MDRV_3_HAZW : 32|2@1+ (1,0) [0|3] "" BDC_Body
 SG_ ST_MDRV_3_RECW : 34|2@1+ (1,0) [0|3] "" ZGW
 SG_ ST_MDRV_3_CF_FAS : 36|4@1+ (1,0) [0|15] "" Vector__XXX
 SG_ ST_MDRV_3_BRPD : 40|4@1+ (1,0) [0|15] "" ZGW
 SG_ StatusMDrive3MControlPlusDrift : 44|4@1+ (1,0) [0|15] "" ZGW,Kombi
 SG_ StatusMDrive3DriftSupportLevel : 48|4@1+ (1,0) [0|15] "" ZGW
 SG_ StatusMDrive3MControlPlusTractio : 52|4@1+ (1,0) [0|15] "" ZGW
 SG_ StatusMDrive3MControlPlusBrakeBa : 56|4@1+ (1,0) [0|15] "" ZGW

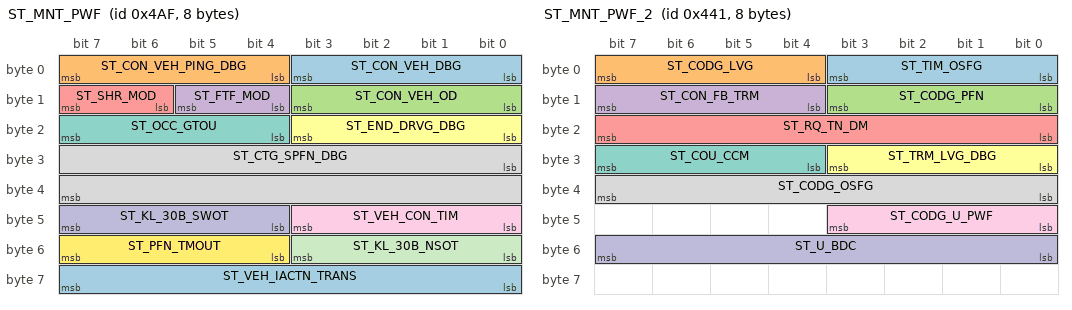
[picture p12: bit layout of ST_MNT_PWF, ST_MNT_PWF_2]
BO_ 1199 ST_MNT_PWF: 8 ZGW
 SG_ ST_CON_VEH_DBG : 0|4@1+ (1,0) [0|15] "" Diagnosetool_FA_CAN
 SG_ ST_CON_VEH_PING_DBG : 4|4@1+ (1,0) [0|15] "" Diagnosetool_FA_CAN
 SG_ ST_CON_VEH_OD : 8|4@1+ (1,0) [0|15] "" Diagnosetool_FA_CAN
 SG_ ST_FTF_MOD : 12|2@1+ (1,0) [0|3] "" Diagnosetool_FA_CAN
 SG_ ST_SHR_MOD : 14|2@1+ (1,0) [0|3] "" Diagnosetool_FA_CAN
 SG_ ST_END_DRVG_DBG : 16|4@1+ (1,0) [0|15] "" Diagnosetool_FA_CAN
 SG_ ST_OCC_GTOU : 20|4@1+ (1,0) [0|15] "" Diagnosetool_FA_CAN
 SG_ ST_CTG_SPFN_DBG : 24|16@1+ (1,0) [0|65535] "" Diagnosetool_FA_CAN
 SG_ ST_VEH_CON_TIM : 40|4@1+ (1,0) [0|15] "" Diagnosetool_FA_CAN
 SG_ ST_KL_30B_SWOT : 44|4@1+ (1,0) [0|15] "" Diagnosetool_FA_CAN
 SG_ ST_KL_30B_NSOT : 48|4@1+ (1,0) [0|15] "" Diagnosetool_FA_CAN
 SG_ ST_PFN_TMOUT : 52|4@1+ (1,0) [0|15] "" Diagnosetool_FA_CAN
 SG_ ST_VEH_IACTN_TRANS : 56|8@1+ (1,0) [0|255] "" Diagnosetool_FA_CAN

BO_ 1089 ST_MNT_PWF_2: 8 ZGW
 SG_ ST_TIM_OSFG : 0|4@1+ (1,0) [0|15] "" Diagnosetool_FA_CAN
 SG_ ST_CODG_LVG : 4|4@1+ (1,0) [0|15] "" Diagnosetool_FA_CAN
 SG_ ST_CODG_PFN : 8|4@1+ (1,0) [0|15] "" Diagnosetool_FA_CAN
 SG_ ST_CON_FB_TRM : 12|4@1+ (1,0) [0|15] "" Diagnosetool_FA_CAN
 SG_ ST_RQ_TN_DM : 16|8@1+ (1,0) [0|255] "" Diagnosetool_FA_CAN
 SG_ ST_TRM_LVG_DBG : 24|4@1+ (1,0) [0|15] "" Diagnosetool_FA_CAN
 SG_ ST_COU_CCM : 28|4@1+ (1,0) [0|15] "" Diagnosetool_FA_CAN
 SG_ ST_CODG_OSFG : 32|8@1+ (1,0) [0|252] "s" Diagnosetool_FA_CAN
 SG_ ST_CODG_U_PWF : 40|4@1+ (0.1,9.3) [10.25|10.36] "V" Diagnosetool_FA_CAN
 SG_ ST_U_BDC : 48|8@1+ (0.1,0) [0|2.52] "V" Diagnosetool_FA_CAN

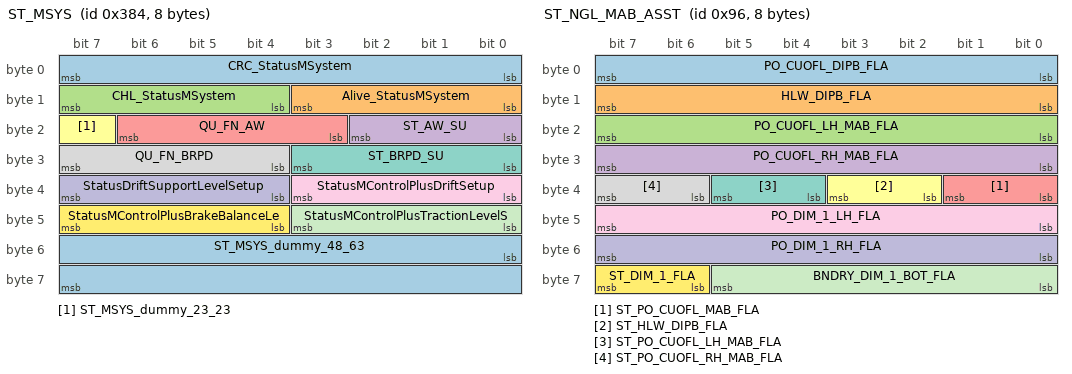
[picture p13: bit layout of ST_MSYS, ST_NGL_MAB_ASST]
BO_ 900 ST_MSYS: 8 ZGW
 SG_ CRC_StatusMSystem : 0|8@1+ (1,0) [0|255] "This unit fulfills the required AUTOSAR reference to a unit. No real unit is defined." Vector__XXX
 SG_ Alive_StatusMSystem : 8|4@1+ (1,0) [0|14] "This unit fulfills the required AUTOSAR reference to a unit. No real unit is defined." Vector__XXX
 SG_ CHL_StatusMSystem : 12|4@1+ (1,0) [0|14] "This unit fulfills the required AUTOSAR reference to a unit. No real unit is defined." Vector__XXX
 SG_ ST_AW_SU : 16|3@1+ (1,0) [0|7] "" Vector__XXX
 SG_ QU_FN_AW : 19|4@1+ (1,0) [0|15] "" Vector__XXX
 SG_ ST_MSYS_dummy_23_23 : 23|1@1+ (1,0) [-1|0] "" Vector__XXX
 SG_ ST_BRPD_SU : 24|4@1+ (1,0) [0|15] "" Vector__XXX
 SG_ QU_FN_BRPD : 28|4@1+ (1,0) [0|15] "" Vector__XXX
 SG_ StatusMControlPlusDriftSetup : 32|4@1+ (1,0) [0|15] "" Vector__XXX
 SG_ StatusDriftSupportLevelSetup : 36|4@1+ (1,0) [0|15] "" Vector__XXX
 SG_ StatusMControlPlusTractionLevelS : 40|4@1+ (1,0) [0|15] "" Vector__XXX
 SG_ StatusMControlPlusBrakeBalanceLe : 44|4@1+ (1,0) [0|15] "" Vector__XXX
 SG_ ST_MSYS_dummy_48_63 : 48|16@1+ (1,0) [-32768|32767] "" Vector__XXX

BO_ 150 ST_NGL_MAB_ASST: 8 BDC_Body
 SG_ PO_CUOFL_DIPB_FLA : 0|8@1+ (0.05,-5) [-5.25|-4.75] "°" ZGW,FLA
 SG_ HLW_DIPB_FLA : 8|8@1+ (1,0) [0|200] "m" ZGW,FLA
 SG_ PO_CUOFL_LH_MAB_FLA : 16|8@1+ (0.1,-10.4) [-11.44|-8.9] "°" ZGW,FLA
 SG_ PO_CUOFL_RH_MAB_FLA : 24|8@1+ (0.1,-15) [-16.5|-13.96] "°" ZGW,FLA
 SG_ ST_PO_CUOFL_MAB_FLA : 32|2@1+ (1,0) [0|3] "" ZGW,FLA
 SG_ ST_HLW_DIPB_FLA : 34|2@1+ (1,0) [0|3] "" ZGW,FLA
 SG_ ST_PO_CUOFL_LH_MAB_FLA : 36|2@1+ (1,0) [0|3] "" ZGW,FLA
 SG_ ST_PO_CUOFL_RH_MAB_FLA : 38|2@1+ (1,0) [0|3] "" ZGW,FLA
 SG_ PO_DIM_1_LH_FLA : 40|8@1+ (0.1,-10) [-11|-8.5] "°" ZGW
 SG_ PO_DIM_1_RH_FLA : 48|8@1+ (0.1,-15) [-16.5|-14] "°" ZGW
 SG_ BNDRY_DIM_1_BOT_FLA : 56|6@1+ (0.2,-6) [-7.2|-4.8] "°" ZGW
 SG_ ST_DIM_1_FLA : 62|2@1+ (1,0) [0|3] "" ZGW

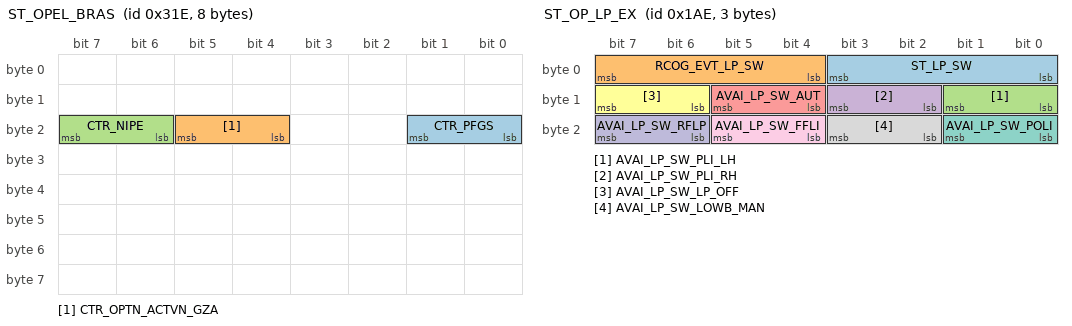
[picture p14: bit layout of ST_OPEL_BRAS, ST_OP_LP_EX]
BO_ 798 ST_OPEL_BRAS: 8 ZGW
 SG_ CTR_PFGS : 16|2@1+ (1,0) [0|3] "" NiVi
 SG_ CTR_OPTN_ACTVN_GZA : 20|2@1+ (1,0) [0|3] "" NiVi
 SG_ CTR_NIPE : 22|2@1+ (1,0) [0|3] "" NiVi

BO_ 430 ST_OP_LP_EX: 3 ZGW
 SG_ ST_LP_SW : 0|4@1+ (1,0) [0|15] "" Kombi,Kombi_Basis,NiVi
 SG_ RCOG_EVT_LP_SW : 4|4@1+ (1,0) [0|15] "" Kombi,Kombi_Basis
 SG_ AVAI_LP_SW_PLI_LH : 8|2@1+ (1,0) [0|3] "" Kombi,Kombi_Basis
 SG_ AVAI_LP_SW_PLI_RH : 10|2@1+ (1,0) [0|3] "" Kombi,Kombi_Basis
 SG_ AVAI_LP_SW_AUT : 12|2@1+ (1,0) [0|3] "" Kombi,Kombi_Basis
 SG_ AVAI_LP_SW_LP_OFF : 14|2@1+ (1,0) [0|3] "" Kombi,Kombi_Basis
 SG_ AVAI_LP_SW_POLI : 16|2@1+ (1,0) [0|3] "" Kombi,Kombi_Basis
 SG_ AVAI_LP_SW_LOWB_MAN : 18|2@1+ (1,0) [0|3] "" Kombi,Kombi_Basis
 SG_ AVAI_LP_SW_FFLI : 20|2@1+ (1,0) [0|3] "" Kombi,Kombi_Basis
 SG_ AVAI_LP_SW_RFLP : 22|2@1+ (1,0) [0|3] "" Kombi,Kombi_Basis

BO_TX_BU_ 943 : Kombi,Kombi_Basis;
BO_TX_BU_ 448 : Kombi,Kombi_Basis;
BO_TX_BU_ 435 : Kombi,Kombi_Basis;
BO_TX_BU_ 942 : Kombi,Kombi_Basis;
BO_TX_BU_ 881 : Kombi,Kombi_Basis;
CM_ BO_ 710  "Dieses Frame beinhaltet Status-Informationen vom ELV Zustand (ELV ent-/verriegelt), ELV-Betriebsparametern und Fehlerinformationen.
==========
This frame contains status information on the ELV state (ELV unlocked/locked), ELV operating parameters and error information.";

BA_DEF_ BO_ "FrameTriggeringName" STRING;
BA_DEF_ BO_ "GenMsgCycleTime" INT 0 65535;
BA_DEF_ BO_ "GenMsgDelayTime" INT 0 65535;
BA_DEF_ BO_ "GenMsgSendType" ENUM  "cyclicX","spontanX","cyclicIfActiveX","spontanWithDelay","cyclicAndSpontanX","cyclicAndSpontanWithDelay","spontanWithRepitition","cyclicIfActiveAndSpontanWD","cyclicIfActiveFast","cyclicWithRepeatOnDemand","none";
BA_DEF_ BO_ "GenMsgStartValue" STRING;
BA_DEF_ BO_ "PduName" STRING;
BA_DEF_ BO_ "SystemMessageLongSymbol" STRING;
BA_DEF_ SG_ "CompuMethodName" STRING;
BA_DEF_ SG_ "GenSigStartValue" FLOAT 0 100000000000;
BA_DEF_ SG_ "ISignalName" STRING;
BA_DEF_ SG_ "LongName" STRING;
BA_DEF_ SG_ "SysSignalName" STRING;
BA_DEF_ SG_ "SystemSignalLongSymbol" STRING;
BA_ "FrameTriggeringName" BO_ 628 "frTrig_CAN_963411935_628_963405169_963411732_963424759_FA_CAN";
BA_ "GenMsgCycleTime" BO_ 628 1000;
BA_ "GenMsgDelayTime" BO_ 628 100;
BA_ "GenMsgSendType" BO_ 628 4;
BA_ "GenMsgStartValue" BO_ 628 "0000000000008000";
BA_ "PduName" BO_ 628 "ST_CON_SEAT_DRR";
BA_ "FrameTriggeringName" BO_ 629 "frTrig_CAN_963412003_629_963391166_963411732_963424759_FA_CAN";
BA_ "GenMsgCycleTime" BO_ 629 1000;
BA_ "GenMsgDelayTime" BO_ 629 100;
BA_ "GenMsgSendType" BO_ 629 4;
BA_ "GenMsgStartValue" BO_ 629 "0000000000008000";
BA_ "PduName" BO_ 629 "ST_CON_SEAT_PSR";
BA_ "FrameTriggeringName" BO_ 708 "frTrig_CAN_963411796_708_963389289_963411732_963424759_FA_CAN";
BA_ "GenMsgCycleTime" BO_ 708 100;
BA_ "GenMsgSendType" BO_ 708 0;
BA_ "GenMsgStartValue" BO_ 708 "0000000000640000";
BA_ "PduName" BO_ 708 "ST_COSP_FU_ENG";
BA_ "FrameTriggeringName" BO_ 171 "frTrig_CAN_963411809_171_963400566_963411732_963424759_FA_CAN";
BA_ "GenMsgCycleTime" BO_ 171 200;
BA_ "GenMsgDelayTime" BO_ 171 5;
BA_ "GenMsgSendType" BO_ 171 4;
BA_ "GenMsgStartValue" BO_ 171 "0000000000000000";
BA_ "PduName" BO_ 171 "ST_CR";
BA_ "FrameTriggeringName" BO_ 943 "frTrig_CAN_963412086_943_963396697_963411732_963424759_FA_CAN";
BA_ "GenMsgCycleTime" BO_ 943 1000;
BA_ "GenMsgDelayTime" BO_ 943 200;
BA_ "GenMsgSendType" BO_ 943 4;
BA_ "GenMsgStartValue" BO_ 943 "ec00000000000000";
BA_ "PduName" BO_ 943 "ST_CTI_DATE";
BA_ "FrameTriggeringName" BO_ 768 "frTrig_CAN_963411921_768_963396555_963411732_963424759_FA_CAN";
BA_ "GenMsgCycleTime" BO_ 768 960;
BA_ "GenMsgDelayTime" BO_ 768 160;
BA_ "GenMsgSendType" BO_ 768 4;
BA_ "GenMsgStartValue" BO_ 768 "4000000000000000";
BA_ "PduName" BO_ 768 "ST_DIAG_OBD_1_PT";
BA_ "FrameTriggeringName" BO_ 983 "frTrig_CAN_963411983_983_963399072_963411732_963424759_FA_CAN";
BA_ "GenMsgCycleTime" BO_ 983 960;
BA_ "GenMsgDelayTime" BO_ 983 160;
BA_ "GenMsgSendType" BO_ 983 4;
BA_ "GenMsgStartValue" BO_ 983 "4000000000000000";
BA_ "PduName" BO_ 983 "ST_DIAG_OBD_7_PT";
BA_ "FrameTriggeringName" BO_ 991 "frTrig_CAN_963411976_991_963405628_963411732_963424759_FA_CAN";
BA_ "GenMsgCycleTime" BO_ 991 960;
BA_ "GenMsgDelayTime" BO_ 991 160;
BA_ "GenMsgSendType" BO_ 991 4;
BA_ "GenMsgStartValue" BO_ 991 "4010000000000000";
BA_ "PduName" BO_ 991 "ST_DIAG_OBD_SLV_1";
BA_ "FrameTriggeringName" BO_ 992 "frTrig_CAN_963412046_992_963403424_963411732_963424759_FA_CAN";
BA_ "GenMsgCycleTime" BO_ 992 960;
BA_ "GenMsgDelayTime" BO_ 992 160;
BA_ "GenMsgSendType" BO_ 992 4;
BA_ "GenMsgStartValue" BO_ 992 "4010000000000000";
BA_ "PduName" BO_ 992 "ST_DIAG_OBD_SLV_2";
BA_ "FrameTriggeringName" BO_ 993 "frTrig_CAN_963412096_993_963401217_963411732_963424759_FA_CAN";
BA_ "GenMsgCycleTime" BO_ 993 960;
BA_ "GenMsgDelayTime" BO_ 993 160;
BA_ "GenMsgSendType" BO_ 993 4;
BA_ "GenMsgStartValue" BO_ 993 "4010000000000000";
BA_ "PduName" BO_ 993 "ST_DIAG_OBD_SLV_3";
BA_ "FrameTriggeringName" BO_ 960 "frTrig_CAN_963412076_960_963405365_963411732_963424759_FA_CAN";
BA_ "GenMsgCycleTime" BO_ 960 1000;
BA_ "GenMsgDelayTime" BO_ 960 200;
BA_ "GenMsgSendType" BO_ 960 4;
BA_ "GenMsgStartValue" BO_ 960 "0000000000000000";
BA_ "PduName" BO_ 960 "ST_DISP_BLTW";
BA_ "FrameTriggeringName" BO_ 448 "frTrig_CAN_963412070_448_963400832_963411732_963424759_FA_CAN";
BA_ "GenMsgCycleTime" BO_ 448 200;
BA_ "GenMsgDelayTime" BO_ 448 40;
BA_ "GenMsgSendType" BO_ 448 4;
BA_ "GenMsgStartValue" BO_ 448 "0000000000000000";
BA_ "PduName" BO_ 448 "ST_DISP_DRASY";
BA_ "FrameTriggeringName" BO_ 435 "frTrig_CAN_963412104_435_963393932_963411732_963424759_FA_CAN";
BA_ "GenMsgCycleTime" BO_ 435 100;
BA_ "GenMsgSendType" BO_ 435 0;
BA_ "GenMsgStartValue" BO_ 435 "0000000000000000";
BA_ "PduName" BO_ 435 "ST_DISP_KI";
BA_ "FrameTriggeringName" BO_ 100 "frTrig_CAN_963412055_100_963405844_963411732_963424759_FA_CAN";
BA_ "GenMsgCycleTime" BO_ 100 1000;
BA_ "GenMsgDelayTime" BO_ 100 100;
BA_ "GenMsgSendType" BO_ 100 4;
BA_ "GenMsgStartValue" BO_ 100 "0080008000000080";
BA_ "PduName" BO_ 100 "ST_DRVG_RDI";
BA_ "FrameTriggeringName" BO_ 707 "frTrig_CAN_963411999_707_963389293_963411732_963424759_FA_CAN";
BA_ "GenMsgCycleTime" BO_ 707 5000;
BA_ "GenMsgDelayTime" BO_ 707 100;
BA_ "GenMsgSendType" BO_ 707 4;
BA_ "GenMsgStartValue" BO_ 707 "0000000000000000";
BA_ "PduName" BO_ 707 "ST_ECAL";
BA_ "FrameTriggeringName" BO_ 710 "frTrig_CAN_963411943_710_963405811_963411732_963424759_FA_CAN";
BA_ "GenMsgCycleTime" BO_ 710 100;
BA_ "GenMsgSendType" BO_ 710 0;
BA_ "GenMsgStartValue" BO_ 710 "0000088000000080";
BA_ "PduName" BO_ 710 "ST_ELV";
BA_ "FrameTriggeringName" BO_ 442 "frTrig_CAN_963411897_442_963388957_963411732_963424759_FA_CAN";
BA_ "GenMsgCycleTime" BO_ 442 1000;
BA_ "GenMsgDelayTime" BO_ 442 50;
BA_ "GenMsgSendType" BO_ 442 4;
BA_ "GenMsgStartValue" BO_ 442 "0000000000000000";
BA_ "PduName" BO_ 442 "ST_ENERG_GEN";
BA_ "FrameTriggeringName" BO_ 912 "frTrig_CAN_963411946_912_963389486_963411732_963424759_FA_CAN";
BA_ "GenMsgSendType" BO_ 912 1;
BA_ "GenMsgStartValue" BO_ 912 "00000000";
BA_ "PduName" BO_ 912 "ST_FN_HOSP";
BA_ "FrameTriggeringName" BO_ 367 "frTrig_CAN_963411790_367_963388822_963411732_963424759_FA_CAN";
BA_ "GenMsgDelayTime" BO_ 367 20;
BA_ "GenMsgSendType" BO_ 367 1;
BA_ "GenMsgStartValue" BO_ 367 "0000000000000000";
BA_ "PduName" BO_ 367 "ST_GO";
BA_ "FrameTriggeringName" BO_ 407 "frTrig_CAN_963412098_407_963405120_963411732_963424759_FA_CAN";
BA_ "GenMsgCycleTime" BO_ 407 30;
BA_ "GenMsgSendType" BO_ 407 0;
BA_ "GenMsgStartValue" BO_ 407 "00000000";
BA_ "PduName" BO_ 407 "ST_GWS";
BA_ "FrameTriggeringName" BO_ 446 "frTrig_CAN_963411794_446_963403196_963411732_963424759_FA_CAN";
BA_ "GenMsgCycleTime" BO_ 446 2000;
BA_ "GenMsgDelayTime" BO_ 446 10;
BA_ "GenMsgSendType" BO_ 446 4;
BA_ "GenMsgStartValue" BO_ 446 "0000";
BA_ "PduName" BO_ 446 "ST_GZA_LH";
BA_ "FrameTriggeringName" BO_ 471 "frTrig_CAN_963411950_471_963391942_963411732_963424759_FA_CAN";
BA_ "GenMsgCycleTime" BO_ 471 2000;
BA_ "GenMsgDelayTime" BO_ 471 10;
BA_ "GenMsgSendType" BO_ 471 4;
BA_ "GenMsgStartValue" BO_ 471 "0000";
BA_ "PduName" BO_ 471 "ST_GZA_RH";
BA_ "FrameTriggeringName" BO_ 942 "frTrig_CAN_963411859_942_963396510_963411732_963424759_FA_CAN";
BA_ "GenMsgCycleTime" BO_ 942 2000;
BA_ "GenMsgDelayTime" BO_ 942 200;
BA_ "GenMsgSendType" BO_ 942 4;
BA_ "GenMsgStartValue" BO_ 942 "0000000000000000";
BA_ "PduName" BO_ 942 "ST_HUD_3";
BA_ "FrameTriggeringName" BO_ 832 "frTrig_CAN_963411875_832_963400645_963411732_963424759_FA_CAN";
BA_ "GenMsgCycleTime" BO_ 832 5000;
BA_ "GenMsgDelayTime" BO_ 832 200;
BA_ "GenMsgSendType" BO_ 832 4;
BA_ "GenMsgStartValue" BO_ 832 "0000";
BA_ "PduName" BO_ 832 "ST_HVBT_WU";
BA_ "FrameTriggeringName" BO_ 506 "frTrig_CAN_963411747_506_963405595_963411732_963424759_FA_CAN";
BA_ "GenMsgCycleTime" BO_ 506 1000;
BA_ "GenMsgDelayTime" BO_ 506 50;
BA_ "GenMsgSendType" BO_ 506 4;
BA_ "GenMsgStartValue" BO_ 506 "0000000032323232";
BA_ "PduName" BO_ 506 "ST_HVSTO_1";
BA_ "FrameTriggeringName" BO_ 613 "frTrig_CAN_963411932_613_963396360_963411732_963424759_FA_CAN";
BA_ "GenMsgCycleTime" BO_ 613 100;
BA_ "GenMsgSendType" BO_ 613 0;
BA_ "GenMsgStartValue" BO_ 613 "0000ceffceff0000";
BA_ "PduName" BO_ 613 "ST_HVSTO_4";
BA_ "FrameTriggeringName" BO_ 795 "frTrig_CAN_963411911_795_963391776_963411732_963424759_FA_CAN";
BA_ "GenMsgCycleTime" BO_ 795 1000;
BA_ "GenMsgDelayTime" BO_ 795 40;
BA_ "GenMsgSendType" BO_ 795 4;
BA_ "GenMsgStartValue" BO_ 795 "000000000000";
BA_ "PduName" BO_ 795 "ST_IDLV_COOD_DBE_DXP";
BA_ "FrameTriggeringName" BO_ 444 "frTrig_CAN_963411839_444_963403218_963411732_963424759_FA_CAN";
BA_ "GenMsgCycleTime" BO_ 444 1000;
BA_ "GenMsgDelayTime" BO_ 444 40;
BA_ "GenMsgSendType" BO_ 444 4;
BA_ "GenMsgStartValue" BO_ 444 "000000000000";
BA_ "PduName" BO_ 444 "ST_IDLV_COOD_DBE_DXP";
BA_ "FrameTriggeringName" BO_ 881 "frTrig_CAN_963411814_881_963391627_963411732_963424759_FA_CAN";
BA_ "GenMsgCycleTime" BO_ 881 1000;
BA_ "GenMsgDelayTime" BO_ 881 200;
BA_ "GenMsgSendType" BO_ 881 4;
BA_ "GenMsgStartValue" BO_ 881 "0000000000";
BA_ "PduName" BO_ 881 "ST_IDLV_COOD_DISP_DXP";
BA_ "FrameTriggeringName" BO_ 875 "frTrig_CAN_963411752_875_963396473_963411732_963424759_FA_CAN";
BA_ "GenMsgCycleTime" BO_ 875 1000;
BA_ "GenMsgDelayTime" BO_ 875 200;
BA_ "GenMsgSendType" BO_ 875 4;
BA_ "GenMsgStartValue" BO_ 875 "00000000";
BA_ "PduName" BO_ 875 "ST_IDLV_COOD_DRV_DXP";
BA_ "FrameTriggeringName" BO_ 572 "frTrig_CAN_963411750_572_963394161_963411732_963424759_FA_CAN";
BA_ "GenMsgDelayTime" BO_ 572 50;
BA_ "GenMsgSendType" BO_ 572 1;
BA_ "GenMsgStartValue" BO_ 572 "0000000000000000";
BA_ "PduName" BO_ 572 "ST_IDT_CHGNG_CA";
BA_ "FrameTriggeringName" BO_ 656 "frTrig_CAN_963411947_656_963393623_963411732_963424759_FA_CAN";
BA_ "GenMsgDelayTime" BO_ 656 100;
BA_ "GenMsgSendType" BO_ 656 1;
BA_ "GenMsgStartValue" BO_ 656 "0000000000000000";
BA_ "PduName" BO_ 656 "ST_KEY_SRCH";
BA_ "FrameTriggeringName" BO_ 874 "frTrig_CAN_963411996_874_963393740_963411732_963424759_FA_CAN";
BA_ "GenMsgCycleTime" BO_ 874 5000;
BA_ "GenMsgDelayTime" BO_ 874 50;
BA_ "GenMsgSendType" BO_ 874 4;
BA_ "GenMsgStartValue" BO_ 874 "0000";
BA_ "PduName" BO_ 874 "ST_MAB_ASST";
BA_ "FrameTriggeringName" BO_ 1070 "frTrig_CAN_963412135_1070_963398526_963411732_963424759_FA_CAN";
BA_ "GenMsgCycleTime" BO_ 1070 10000;
BA_ "GenMsgDelayTime" BO_ 1070 200;
BA_ "GenMsgSendType" BO_ 1070 4;
BA_ "GenMsgStartValue" BO_ 1070 "0000000000000000";
BA_ "PduName" BO_ 1070 "ST_MDRV_2";
BA_ "FrameTriggeringName" BO_ 1029 "frTrig_CAN_963412160_1029_963393686_963411732_963424759_FA_CAN";
BA_ "GenMsgCycleTime" BO_ 1029 10000;
BA_ "GenMsgDelayTime" BO_ 1029 200;
BA_ "GenMsgSendType" BO_ 1029 4;
BA_ "GenMsgStartValue" BO_ 1029 "0000000000000000";
BA_ "PduName" BO_ 1029 "ST_MDRV_3";
BA_ "FrameTriggeringName" BO_ 1199 "frTrig_CAN_963412008_1199_963405140_963411732_963424759_FA_CAN";
BA_ "GenMsgCycleTime" BO_ 1199 10000;
BA_ "GenMsgDelayTime" BO_ 1199 100;
BA_ "GenMsgSendType" BO_ 1199 4;
BA_ "GenMsgStartValue" BO_ 1199 "0000000000000000";
BA_ "PduName" BO_ 1199 "ST_MNT_PWF";
BA_ "FrameTriggeringName" BO_ 1089 "frTrig_CAN_963412094_1089_963398226_963411732_963424759_FA_CAN";
BA_ "GenMsgCycleTime" BO_ 1089 10000;
BA_ "GenMsgDelayTime" BO_ 1089 100;
BA_ "GenMsgSendType" BO_ 1089 4;
BA_ "GenMsgStartValue" BO_ 1089 "00000000000a0000";
BA_ "PduName" BO_ 1089 "ST_MNT_PWF_2";
BA_ "FrameTriggeringName" BO_ 900 "frTrig_CAN_963411812_900_963393940_963411732_963424759_FA_CAN";
BA_ "GenMsgCycleTime" BO_ 900 2000;
BA_ "GenMsgDelayTime" BO_ 900 40;
BA_ "GenMsgSendType" BO_ 900 4;
BA_ "GenMsgStartValue" BO_ 900 "0000800000000080";
BA_ "PduName" BO_ 900 "ST_MSYS";
BA_ "FrameTriggeringName" BO_ 150 "frTrig_CAN_963411811_150_963389430_963411732_963424759_FA_CAN";
BA_ "GenMsgCycleTime" BO_ 150 30;
BA_ "GenMsgSendType" BO_ 150 0;
BA_ "GenMsgStartValue" BO_ 150 "fb00f6f100f6f13a";
BA_ "PduName" BO_ 150 "ST_NGL_MAB_ASST";
BA_ "FrameTriggeringName" BO_ 798 "frTrig_CAN_963411977_798_963396648_963411732_963424759_FA_CAN";
BA_ "GenMsgCycleTime" BO_ 798 1000;
BA_ "GenMsgDelayTime" BO_ 798 160;
BA_ "GenMsgSendType" BO_ 798 4;
BA_ "GenMsgStartValue" BO_ 798 "0000000000000000";
BA_ "PduName" BO_ 798 "ST_OPEL_BRAS";
BA_ "FrameTriggeringName" BO_ 430 "frTrig_CAN_963412171_430_963400768_963411732_963424759_FA_CAN";
BA_ "GenMsgCycleTime" BO_ 430 100;
BA_ "GenMsgDelayTime" BO_ 430 10;
BA_ "GenMsgSendType" BO_ 430 4;
BA_ "GenMsgStartValue" BO_ 430 "000000";
BA_ "PduName" BO_ 430 "ST_OP_LP_EX";
BA_ "CompuMethodName" SG_ 628 ALIV_ST_CON_SEAT_DRR "ALIV_4_BIT_Unsigned_Integer";
BA_ "ISignalName" SG_ 628 ALIV_ST_CON_SEAT_DRR "ALIV_ST_CON_SEAT_DRR";
BA_ "LongName" SG_ 628 ALIV_ST_CON_SEAT_DRR "Alive_Status_Zustand_Sitz_FAH";
BA_ "SysSignalName" SG_ 628 ALIV_ST_CON_SEAT_DRR "ALIV_ST_CON_SEAT_DRR";
BA_ "CompuMethodName" SG_ 628 ST_SBIL_DRR "ST_SBIL";
BA_ "ISignalName" SG_ 628 ST_SBIL_DRR "ST_SBIL_DRR";
BA_ "LongName" SG_ 628 ST_SBIL_DRR "Status_Sitzlehnenverriegelung_FAH";
BA_ "SysSignalName" SG_ 628 ST_SBIL_DRR "ST_SBIL_DRR";
BA_ "CompuMethodName" SG_ 628 ST_SBIL_DRR3 "ST_SBIL";
BA_ "ISignalName" SG_ 628 ST_SBIL_DRR3 "ST_SBIL_DRR3";
BA_ "LongName" SG_ 628 ST_SBIL_DRR3 "Status_Sitzlehnenverriegelung_FAH3";
BA_ "SysSignalName" SG_ 628 ST_SBIL_DRR3 "ST_SBIL_DRR3";
BA_ "CompuMethodName" SG_ 628 BR_TLT_PO_DRR "BR_TLT_POSI";
BA_ "ISignalName" SG_ 628 BR_TLT_PO_DRR "BR_TLT_PO_DRR";
BA_ "LongName" SG_ 628 BR_TLT_PO_DRR "Lehne_Neigung_Position_FAH";
BA_ "SysSignalName" SG_ 628 BR_TLT_PO_DRR "BR_TLT_PO_DRR";
BA_ "CompuMethodName" SG_ 628 BR_TLT_PO_DRR3 "BR_TLT_POSI";
BA_ "ISignalName" SG_ 628 BR_TLT_PO_DRR3 "BR_TLT_PO_DRR3";
BA_ "LongName" SG_ 628 BR_TLT_PO_DRR3 "Lehne_Neigung_Position_FAH3";
BA_ "SysSignalName" SG_ 628 BR_TLT_PO_DRR3 "BR_TLT_PO_DRR3";
BA_ "CompuMethodName" SG_ 628 ST_EMULOK_DRR "ST_EMULOK";
BA_ "ISignalName" SG_ 628 ST_EMULOK_DRR "ST_EMULOK_DRR";
BA_ "LongName" SG_ 628 ST_EMULOK_DRR "Status_Notentriegelung_FAH";
BA_ "SysSignalName" SG_ 628 ST_EMULOK_DRR "ST_EMULOK_DRR";
BA_ "CompuMethodName" SG_ 628 ST_AD_BOOT_FNS_DRR "ST_AD_BOOT_FNS";
BA_ "ISignalName" SG_ 628 ST_AD_BOOT_FNS_DRR "ST_AD_BOOT_FNS_DRR";
BA_ "LongName" SG_ 628 ST_AD_BOOT_FNS_DRR "Status_Verstellung_Gepäckraum_Funktionen_FAH";
BA_ "SysSignalName" SG_ 628 ST_AD_BOOT_FNS_DRR "ST_AD_BOOT_FNS_DRR";
BA_ "CompuMethodName" SG_ 628 ST_AD_BOOT_FNS_DRR3 "ST_AD_BOOT_FNS";
BA_ "ISignalName" SG_ 628 ST_AD_BOOT_FNS_DRR3 "ST_AD_BOOT_FNS_DRR3";
BA_ "LongName" SG_ 628 ST_AD_BOOT_FNS_DRR3 "Status_Verstellung_Gepäckraum_Funktionen_FAH3";
BA_ "SysSignalName" SG_ 628 ST_AD_BOOT_FNS_DRR3 "ST_AD_BOOT_FNS_DRR3";
BA_ "CompuMethodName" SG_ 628 ST_SEAT_EEL_PLCHK_DRR "ST_SEAT_EEL_PLCHK_PSR";
BA_ "ISignalName" SG_ 628 ST_SEAT_EEL_PLCHK_DRR "ST_SEAT_EEL_PLCHK_DRR";
BA_ "LongName" SG_ 628 ST_SEAT_EEL_PLCHK_DRR "Status_Sitz_EasyEntry-Verriegelung_Plausibilitätsprüfung_FAH";
BA_ "SysSignalName" SG_ 628 ST_SEAT_EEL_PLCHK_DRR "ST_SEAT_EEL_PLCHK_DRR";
BA_ "CompuMethodName" SG_ 628 CTR_LED_NAD_TIR_2 "CTR_LED_NAD_TIR_2";
BA_ "ISignalName" SG_ 628 CTR_LED_NAD_TIR_2 "CTR_LED_NAD_TIR_2";
BA_ "LongName" SG_ 628 CTR_LED_NAD_TIR_2 "Control_LED_Nonavailibility_Adjustment_Tier_2";
BA_ "SysSignalName" SG_ 628 CTR_LED_NAD_TIR_2 "CTR_LED_NAD_TIR_2";
BA_ "CompuMethodName" SG_ 628 CTR_LED_NAD_TIR_3 "CTR_LED_NAD_TIR_2";
BA_ "ISignalName" SG_ 628 CTR_LED_NAD_TIR_3 "CTR_LED_NAD_TIR_3";
BA_ "LongName" SG_ 628 CTR_LED_NAD_TIR_3 "Steuerung_LED_Nichtverfuegbarkeit_Verstellung_SR_3";
BA_ "SysSignalName" SG_ 628 CTR_LED_NAD_TIR_3 "CTR_LED_NAD_TIR_3";
BA_ "CompuMethodName" SG_ 628 CTR_LED_NAD_BOOT_FNS "CTR_LED_NAD_TIR_2";
BA_ "ISignalName" SG_ 628 CTR_LED_NAD_BOOT_FNS "CTR_LED_NAD_BOOT_FNS";
BA_ "LongName" SG_ 628 CTR_LED_NAD_BOOT_FNS "Steuerung_LED_Nichtverfuegbarkeit_Gepaeckraum_Funktionen";
BA_ "SysSignalName" SG_ 628 CTR_LED_NAD_BOOT_FNS "CTR_LED_NAD_BOOT_FNS";
BA_ "ISignalName" SG_ 628 ST_CON_SEAT_DRR_dummy_42_55 "ST_CON_SEAT_DRR_dummy_42_55";
BA_ "LongName" SG_ 628 ST_CON_SEAT_DRR_dummy_42_55 "ST_CON_SEAT_DRR_dummy_42_55";
BA_ "SysSignalName" SG_ 628 ST_CON_SEAT_DRR_dummy_42_55 "ST_CON_SEAT_DRR_dummy_42_55";
BA_ "CompuMethodName" SG_ 628 CRC_ST_CON_SEAT_DRR "CRC8";
BA_ "ISignalName" SG_ 628 CRC_ST_CON_SEAT_DRR "CRC_ST_CON_SEAT_DRR";
BA_ "LongName" SG_ 628 CRC_ST_CON_SEAT_DRR "CRC_Status_Zustand_Sitz_FAH";
BA_ "SysSignalName" SG_ 628 CRC_ST_CON_SEAT_DRR "CRC_ST_CON_SEAT_DRR";
BA_ "CompuMethodName" SG_ 629 ALIV_ST_CON_SEAT_PSR "ALIV_4_BIT_Unsigned_Integer";
BA_ "ISignalName" SG_ 629 ALIV_ST_CON_SEAT_PSR "ALIV_ST_CON_SEAT_PSR";
BA_ "LongName" SG_ 629 ALIV_ST_CON_SEAT_PSR "Alive_Status_Zustand_Sitz_BFH";
BA_ "SysSignalName" SG_ 629 ALIV_ST_CON_SEAT_PSR "ALIV_ST_CON_SEAT_PSR";
BA_ "CompuMethodName" SG_ 629 ST_SBIL_PSR "ST_SBIL";
BA_ "ISignalName" SG_ 629 ST_SBIL_PSR "ST_SBIL_PSR";
BA_ "LongName" SG_ 629 ST_SBIL_PSR "Status_Sitzlehnenverriegelung_BFH";
BA_ "SysSignalName" SG_ 629 ST_SBIL_PSR "ST_SBIL_PSR";
BA_ "CompuMethodName" SG_ 629 ST_SBIL_PSR3 "ST_SBIL";
BA_ "ISignalName" SG_ 629 ST_SBIL_PSR3 "ST_SBIL_PSR3";
BA_ "LongName" SG_ 629 ST_SBIL_PSR3 "Status_Sitzlehnenverriegelung_BFH3";
BA_ "SysSignalName" SG_ 629 ST_SBIL_PSR3 "ST_SBIL_PSR3";
BA_ "CompuMethodName" SG_ 629 BR_TLT_PO_PSR "BR_TLT_POSI";
BA_ "ISignalName" SG_ 629 BR_TLT_PO_PSR "BR_TLT_PO_PSR";
BA_ "LongName" SG_ 629 BR_TLT_PO_PSR "Lehne_Neigung_Position_BFH";
BA_ "SysSignalName" SG_ 629 BR_TLT_PO_PSR "BR_TLT_PO_PSR";
BA_ "CompuMethodName" SG_ 629 BR_TLT_PO_PSR3 "BR_TLT_POSI";
BA_ "ISignalName" SG_ 629 BR_TLT_PO_PSR3 "BR_TLT_PO_PSR3";
BA_ "LongName" SG_ 629 BR_TLT_PO_PSR3 "Lehne_Neigung_Position_BFH3";
BA_ "SysSignalName" SG_ 629 BR_TLT_PO_PSR3 "BR_TLT_PO_PSR3";
BA_ "CompuMethodName" SG_ 629 ST_EMULOK_PSR "ST_EMULOK";
BA_ "ISignalName" SG_ 629 ST_EMULOK_PSR "ST_EMULOK_PSR";
BA_ "LongName" SG_ 629 ST_EMULOK_PSR "Status_Notentriegelung_BFH";
BA_ "SysSignalName" SG_ 629 ST_EMULOK_PSR "ST_EMULOK_PSR";
BA_ "CompuMethodName" SG_ 629 ST_AD_BOOT_FNS_PSR "ST_AD_BOOT_FNS";
BA_ "ISignalName" SG_ 629 ST_AD_BOOT_FNS_PSR "ST_AD_BOOT_FNS_PSR";
BA_ "LongName" SG_ 629 ST_AD_BOOT_FNS_PSR "Status_Verstellung_Gepäckraum_Funktionen_BFH";
BA_ "SysSignalName" SG_ 629 ST_AD_BOOT_FNS_PSR "ST_AD_BOOT_FNS_PSR";
BA_ "CompuMethodName" SG_ 629 ST_AD_BOOT_FNS_PSR3 "ST_AD_BOOT_FNS";
BA_ "ISignalName" SG_ 629 ST_AD_BOOT_FNS_PSR3 "ST_AD_BOOT_FNS_PSR3";
BA_ "LongName" SG_ 629 ST_AD_BOOT_FNS_PSR3 "Status_Verstellung_Gepäckraum_Funktionen_BFH3";
BA_ "SysSignalName" SG_ 629 ST_AD_BOOT_FNS_PSR3 "ST_AD_BOOT_FNS_PSR3";
BA_ "CompuMethodName" SG_ 629 ST_SEAT_EEL_PLCHK_PSR "ST_SEAT_EEL_PLCHK_PSR";
BA_ "ISignalName" SG_ 629 ST_SEAT_EEL_PLCHK_PSR "ST_SEAT_EEL_PLCHK_PSR";
BA_ "LongName" SG_ 629 ST_SEAT_EEL_PLCHK_PSR "Status_Sitz_EasyEntry-Verriegelung_Plausibilitätsprüfung_BFH";
BA_ "SysSignalName" SG_ 629 ST_SEAT_EEL_PLCHK_PSR "ST_SEAT_EEL_PLCHK_PSR";
BA_ "CompuMethodName" SG_ 629 CTR_LED_NAD_TIR_2_PSR "CTR_LED_NAD_TIR_2_PSR";
BA_ "ISignalName" SG_ 629 CTR_LED_NAD_TIR_2_PSR "CTR_LED_NAD_TIR_2_PSR";
BA_ "LongName" SG_ 629 CTR_LED_NAD_TIR_2_PSR "Steuerung_LED_Nichtverfuegbarkeit_Verstellung_SR_2_BFH";
BA_ "SysSignalName" SG_ 629 CTR_LED_NAD_TIR_2_PSR "CTR_LED_NAD_TIR_2_PSR";
BA_ "CompuMethodName" SG_ 629 CTR_LED_NAD_TIR_3_PSR "CTR_LED_NAD_TIR_3_PSR";
BA_ "ISignalName" SG_ 629 CTR_LED_NAD_TIR_3_PSR "CTR_LED_NAD_TIR_3_PSR";
BA_ "LongName" SG_ 629 CTR_LED_NAD_TIR_3_PSR "Steuerung_LED_Nichtverfuegbarkeit_Verstellung_SR_3_BFH";
BA_ "SysSignalName" SG_ 629 CTR_LED_NAD_TIR_3_PSR "CTR_LED_NAD_TIR_3_PSR";
BA_ "CompuMethodName" SG_ 629 CTR_LED_NAD_BOOT_FNS_PSR "CTR_LED_NAD_BOOT_FNS_PSR";
BA_ "ISignalName" SG_ 629 CTR_LED_NAD_BOOT_FNS_PSR "CTR_LED_NAD_BOOT_FNS_PSR";
BA_ "LongName" SG_ 629 CTR_LED_NAD_BOOT_FNS_PSR "Steuerung_LED_Nichtverfuegbarkeit_Gepaeckraum_Funktionen_BFH";
BA_ "SysSignalName" SG_ 629 CTR_LED_NAD_BOOT_FNS_PSR "CTR_LED_NAD_BOOT_FNS_PSR";
BA_ "ISignalName" SG_ 629 ST_CON_SEAT_PSR_dummy_42_55 "ST_CON_SEAT_PSR_dummy_42_55";
BA_ "LongName" SG_ 629 ST_CON_SEAT_PSR_dummy_42_55 "ST_CON_SEAT_PSR_dummy_42_55";
BA_ "SysSignalName" SG_ 629 ST_CON_SEAT_PSR_dummy_42_55 "ST_CON_SEAT_PSR_dummy_42_55";
BA_ "CompuMethodName" SG_ 629 CRC_ST_CON_SEAT_PSR "CRC8";
BA_ "ISignalName" SG_ 629 CRC_ST_CON_SEAT_PSR "CRC_ST_CON_SEAT_PSR";
BA_ "LongName" SG_ 629 CRC_ST_CON_SEAT_PSR "CRC_Status_Zustand_Sitz_BFH";
BA_ "SysSignalName" SG_ 629 CRC_ST_CON_SEAT_PSR "CRC_ST_CON_SEAT_PSR";
BA_ "CompuMethodName" SG_ 708 IJV_FU_ENG "IJV_FU_ENG";
BA_ "ISignalName" SG_ 708 IJV_FU_ENG "IJV_FU_ENG";
BA_ "LongName" SG_ 708 IJV_FU_ENG "Einspritzmenge_Kraftstoff_Motor";
BA_ "SysSignalName" SG_ 708 IJV_FU_ENG "IJV_FU_ENG";
BA_ "CompuMethodName" SG_ 708 OIT "OIT";
BA_ "ISignalName" SG_ 708 OIT "OIT";
BA_ "LongName" SG_ 708 OIT "Öltemperatur";
BA_ "SysSignalName" SG_ 708 OIT "OIT";
BA_ "CompuMethodName" SG_ 708 EDA_AVL_PO "EDA_PO";
BA_ "GenSigStartValue" SG_ 708 EDA_AVL_PO 100;
BA_ "ISignalName" SG_ 708 EDA_AVL_PO "EDA_AVL_PO";
BA_ "LongName" SG_ 708 EDA_AVL_PO "EDA_Ist_Position";
BA_ "SysSignalName" SG_ 708 EDA_AVL_PO "EDA_AVL_PO";
BA_ "CompuMethodName" SG_ 708 EDA_AVL_PO_ID "EDA_AVL_PO_ID";
BA_ "ISignalName" SG_ 708 EDA_AVL_PO_ID "EDA_AVL_PO_ID";
BA_ "LongName" SG_ 708 EDA_AVL_PO_ID "EDA_Ist_Position_ID";
BA_ "SysSignalName" SG_ 708 EDA_AVL_PO_ID "EDA_AVL_PO_ID";
BA_ "CompuMethodName" SG_ 708 ECO_TIPS_MSA "ECO_TIPS_MSA";
BA_ "ISignalName" SG_ 708 ECO_TIPS_MSA "ECO_TIPS_MSA";
BA_ "LongName" SG_ 708 ECO_TIPS_MSA "ECO_Tipps_MSA";
BA_ "SysSignalName" SG_ 708 ECO_TIPS_MSA "ECO_TIPS_MSA";
BA_ "CompuMethodName" SG_ 708 FU_RNG_DISP_DEAC "FU_RNG_DISP_DEAC";
BA_ "ISignalName" SG_ 708 FU_RNG_DISP_DEAC "FU_RNG_DISP_DEAC";
BA_ "LongName" SG_ 708 FU_RNG_DISP_DEAC "Kraftstoff_Reichweite_Anzeige_Deaktivierung";
BA_ "SysSignalName" SG_ 708 FU_RNG_DISP_DEAC "FU_RNG_DISP_DEAC";
BA_ "CompuMethodName" SG_ 708 EL_RNG_DISP_DEAC "EL_RNG_DISP_DEAC";
BA_ "ISignalName" SG_ 708 EL_RNG_DISP_DEAC "EL_RNG_DISP_DEAC";
BA_ "LongName" SG_ 708 EL_RNG_DISP_DEAC "Elektrisch_Reichweite_Anzeige_Deaktivierung";
BA_ "SysSignalName" SG_ 708 EL_RNG_DISP_DEAC "EL_RNG_DISP_DEAC";
BA_ "CompuMethodName" SG_ 171 CRC_ST_CR "CRC8";
BA_ "ISignalName" SG_ 171 CRC_ST_CR "CRC_ST_CR";
BA_ "LongName" SG_ 171 CRC_ST_CR "CRC_Status_Crash";
BA_ "SysSignalName" SG_ 171 CRC_ST_CR "CRC_ST_CR";
BA_ "CompuMethodName" SG_ 171 ALIV_ST_CR "ALIV_4_BIT_UInt";
BA_ "ISignalName" SG_ 171 ALIV_ST_CR "ALIV_ST_CR";
BA_ "LongName" SG_ 171 ALIV_ST_CR "Alive_Status_Crash";
BA_ "SysSignalName" SG_ 171 ALIV_ST_CR "ALIV_ST_CR";
BA_ "CompuMethodName" SG_ 171 StatusCrashSeverityLevelNearDepl "StatusCrashSeverityLevelNearDeploy";
BA_ "ISignalName" SG_ 171 StatusCrashSeverityLevelNearDepl "StatusCrashSeverityLevelNearDeploy";
BA_ "LongName" SG_ 171 StatusCrashSeverityLevelNearDepl "StatusCrashSeverityLevelNearDeploy";
BA_ "SysSignalName" SG_ 171 StatusCrashSeverityLevelNearDepl "StatusCrashSeverityLevelNearDeploy";
BA_ "SystemSignalLongSymbol" SG_ 171 StatusCrashSeverityLevelNearDepl "StatusCrashSeverityLevelNearDeploy";
BA_ "CompuMethodName" SG_ 171 ST_DEPLOY_AB "ST_DEPLOY_AB";
BA_ "ISignalName" SG_ 171 ST_DEPLOY_AB "ST_DEPLOY_AB";
BA_ "LongName" SG_ 171 ST_DEPLOY_AB "Status_Auslösen_Airbag";
BA_ "SysSignalName" SG_ 171 ST_DEPLOY_AB "ST_DEPLOY_AB";
BA_ "CompuMethodName" SG_ 171 ST_THRV_ACLN "ST_THRV_ACLN";
BA_ "ISignalName" SG_ 171 ST_THRV_ACLN "ST_THRV_ACLN";
BA_ "LongName" SG_ 171 ST_THRV_ACLN "Status_Schwellwert_Beschleunigung";
BA_ "SysSignalName" SG_ 171 ST_THRV_ACLN "ST_THRV_ACLN";
BA_ "CompuMethodName" SG_ 171 ST_CRSE_FRT "ST_CRSE_1";
BA_ "ISignalName" SG_ 171 ST_CRSE_FRT "ST_CRSE_FRT";
BA_ "LongName" SG_ 171 ST_CRSE_FRT "Status_Crashschwere_Front";
BA_ "SysSignalName" SG_ 171 ST_CRSE_FRT "ST_CRSE_FRT";
BA_ "CompuMethodName" SG_ 171 ST_CRSE_SIDE_RH "ST_CRSE_1";
BA_ "ISignalName" SG_ 171 ST_CRSE_SIDE_RH "ST_CRSE_SIDE_RH";
BA_ "LongName" SG_ 171 ST_CRSE_SIDE_RH "Status_Crashschwere_Seite_Rechts";
BA_ "SysSignalName" SG_ 171 ST_CRSE_SIDE_RH "ST_CRSE_SIDE_RH";
BA_ "CompuMethodName" SG_ 171 ST_CRSE_SIDE_LH "ST_CRSE_1";
BA_ "ISignalName" SG_ 171 ST_CRSE_SIDE_LH "ST_CRSE_SIDE_LH";
BA_ "LongName" SG_ 171 ST_CRSE_SIDE_LH "Status_Crashschwere_Seite_Links";
BA_ "SysSignalName" SG_ 171 ST_CRSE_SIDE_LH "ST_CRSE_SIDE_LH";
BA_ "CompuMethodName" SG_ 171 ST_CRSE_REAR "ST_CRSE_1";
BA_ "ISignalName" SG_ 171 ST_CRSE_REAR "ST_CRSE_REAR";
BA_ "LongName" SG_ 171 ST_CRSE_REAR "Status_Crashschwere_Heck";
BA_ "SysSignalName" SG_ 171 ST_CRSE_REAR "ST_CRSE_REAR";
BA_ "CompuMethodName" SG_ 171 ST_CRSE_ROV "ST_CRSE_1";
BA_ "ISignalName" SG_ 171 ST_CRSE_ROV "ST_CRSE_ROV";
BA_ "LongName" SG_ 171 ST_CRSE_ROV "Status_Crashschwere_Roll-Over";
BA_ "SysSignalName" SG_ 171 ST_CRSE_ROV "ST_CRSE_ROV";
BA_ "CompuMethodName" SG_ 171 ST_CRSE_PED "ST_CRSE_1";
BA_ "ISignalName" SG_ 171 ST_CRSE_PED "ST_CRSE_PED";
BA_ "LongName" SG_ 171 ST_CRSE_PED "Status_Crashschwere_Fußgänger";
BA_ "SysSignalName" SG_ 171 ST_CRSE_PED "ST_CRSE_PED";
BA_ "CompuMethodName" SG_ 171 ST_DMG_HV_SYS "ST_DMG_HV_SYS";
BA_ "ISignalName" SG_ 171 ST_DMG_HV_SYS "ST_DMG_HV_SYS";
BA_ "LongName" SG_ 171 ST_DMG_HV_SYS "Status_Schaden_Hochspannung_System";
BA_ "SysSignalName" SG_ 171 ST_DMG_HV_SYS "ST_DMG_HV_SYS";
BA_ "CompuMethodName" SG_ 171 StatusCrashSeverityLevelFrontEnv "StatusCrashSeverityLevelFrontEnvironmentallnformation";
BA_ "ISignalName" SG_ 171 StatusCrashSeverityLevelFrontEnv "StatusCrashSeverityLevelFrontEnvironmentallnformation";
BA_ "LongName" SG_ 171 StatusCrashSeverityLevelFrontEnv "StatusCrashSeverityLevelFrontEnvironmentallnformation";
BA_ "SysSignalName" SG_ 171 StatusCrashSeverityLevelFrontEnv "StatusCrashSeverityLevelFrontEnvironmentallnformation";
BA_ "SystemSignalLongSymbol" SG_ 171 StatusCrashSeverityLevelFrontEnv "StatusCrashSeverityLevelFrontEnvironmentallnformation";
BA_ "CompuMethodName" SG_ 171 StatusCrashSeverityLevelRearEnvi "StatusCrashSeverityLevelRearEnvironmentallnformation";
BA_ "ISignalName" SG_ 171 StatusCrashSeverityLevelRearEnvi "StatusCrashSeverityLevelRearEnvironmentallnformation";
BA_ "LongName" SG_ 171 StatusCrashSeverityLevelRearEnvi "StatusCrashSeverityLevelRearEnvironmentallnformation";
BA_ "SysSignalName" SG_ 171 StatusCrashSeverityLevelRearEnvi "StatusCrashSeverityLevelRearEnvironmentallnformation";
BA_ "SystemSignalLongSymbol" SG_ 171 StatusCrashSeverityLevelRearEnvi "StatusCrashSeverityLevelRearEnvironmentallnformation";
BA_ "CompuMethodName" SG_ 171 StatusCrashSeverityLevelSideRigh "StatusCrashSeverityLevelSideRightHandEnvironmentalInformation";
BA_ "ISignalName" SG_ 171 StatusCrashSeverityLevelSideRigh "StatusCrashSeverityLevelSideRightHandEnvironmentalInformation";
BA_ "LongName" SG_ 171 StatusCrashSeverityLevelSideRigh "StatusCrashSeverityLevelSideRightHandEnvironmentalInformation";
BA_ "SysSignalName" SG_ 171 StatusCrashSeverityLevelSideRigh "StatusCrashSeverityLevelSideRightHandEnvironmentalInformation";
BA_ "SystemSignalLongSymbol" SG_ 171 StatusCrashSeverityLevelSideRigh "StatusCrashSeverityLevelSideRightHandEnvironmentalInformation";
BA_ "CompuMethodName" SG_ 171 StatusCrashSeverityLevelSideLeft "StatusCrashSeverityLevelSideLeftHandEnvironmentallnformation";
BA_ "ISignalName" SG_ 171 StatusCrashSeverityLevelSideLeft "StatusCrashSeverityLevelSideLeftHandEnvironmentallnformation";
BA_ "LongName" SG_ 171 StatusCrashSeverityLevelSideLeft "StatusCrashSeverityLevelSideLeftHandEnvironmentallnformation";
BA_ "SysSignalName" SG_ 171 StatusCrashSeverityLevelSideLeft "StatusCrashSeverityLevelSideLeftHandEnvironmentallnformation";
BA_ "SystemSignalLongSymbol" SG_ 171 StatusCrashSeverityLevelSideLeft "StatusCrashSeverityLevelSideLeftHandEnvironmentallnformation";
BA_ "CompuMethodName" SG_ 943 ST_TZS_OFFS "TZS_OFFS";
BA_ "GenSigStartValue" SG_ 943 ST_TZS_OFFS -20;
BA_ "ISignalName" SG_ 943 ST_TZS_OFFS "ST_TZS_OFFS";
BA_ "LongName" SG_ 943 ST_TZS_OFFS "Status_Zeitzonen_Offset";
BA_ "SysSignalName" SG_ 943 ST_TZS_OFFS "ST_TZS_OFFS";
BA_ "CompuMethodName" SG_ 943 ST_CHB_T_ADJU_AUTOMLY "CHB_T_ADJU_AUTOMLY";
BA_ "ISignalName" SG_ 943 ST_CHB_T_ADJU_AUTOMLY "ST_CHB_T_ADJU_AUTOMLY";
BA_ "LongName" SG_ 943 ST_CHB_T_ADJU_AUTOMLY "Status_Checkbox_Zeit_Einstellung_Automatisch";
BA_ "SysSignalName" SG_ 943 ST_CHB_T_ADJU_AUTOMLY "ST_CHB_T_ADJU_AUTOMLY";
BA_ "CompuMethodName" SG_ 943 ST_TZS_ID "CTI_TZS_ID";
BA_ "ISignalName" SG_ 943 ST_TZS_ID "ST_TZS_ID";
BA_ "LongName" SG_ 943 ST_TZS_ID "Status_Zeitzonen_ID";
BA_ "SysSignalName" SG_ 943 ST_TZS_ID "ST_TZS_ID";
BA_ "CompuMethodName" SG_ 768 ALIV_ST_DIAG_OBD_1_PT "ALIV_4_BIT_Unsigned_Integer";
BA_ "ISignalName" SG_ 768 ALIV_ST_DIAG_OBD_1_PT "ALIV_ST_DIAG_OBD_1_PT";
BA_ "LongName" SG_ 768 ALIV_ST_DIAG_OBD_1_PT "Alive_Status_Diagnose_OBD_1_Antriebsstrang";
BA_ "SysSignalName" SG_ 768 ALIV_ST_DIAG_OBD_1_PT "ALIV_ST_DIAG_OBD_1_PT";
BA_ "CompuMethodName" SG_ 768 ST_DIAG_OBD_1_PT_MAX_MUX "ST_DIAG_OBD_MUX_MAX";
BA_ "GenSigStartValue" SG_ 768 ST_DIAG_OBD_1_PT_MAX_MUX 4;
BA_ "ISignalName" SG_ 768 ST_DIAG_OBD_1_PT_MAX_MUX "ST_DIAG_OBD_1_PT_MAX_MUX";
BA_ "LongName" SG_ 768 ST_DIAG_OBD_1_PT_MAX_MUX "Status_Diagnose_OBD_1_Antriebsstrang_Maximal_Multiplexer";
BA_ "SysSignalName" SG_ 768 ST_DIAG_OBD_1_PT_MAX_MUX "ST_DIAG_OBD_1_PT_MAX_MUX";
BA_ "CompuMethodName" SG_ 768 ST_DIAG_OBD_1_PT_IMME_MUX "ST_DIAG_OBD_X_PT_IMME_MUX";
BA_ "ISignalName" SG_ 768 ST_DIAG_OBD_1_PT_IMME_MUX "ST_DIAG_OBD_1_PT_IMME_MUX";
BA_ "LongName" SG_ 768 ST_DIAG_OBD_1_PT_IMME_MUX "Status_Diagnose_OBD_1_Antriebsstrang_Aktuell_Multiplexer";
BA_ "SysSignalName" SG_ 768 ST_DIAG_OBD_1_PT_IMME_MUX "ST_DIAG_OBD_1_PT_IMME_MUX";
BA_ "CompuMethodName" SG_ 768 DIAG_ST_OBD_1_PT_1 "DIAG_ST_OBD";
BA_ "ISignalName" SG_ 768 DIAG_ST_OBD_1_PT_1 "DIAG_ST_OBD_1_PT_1";
BA_ "LongName" SG_ 768 DIAG_ST_OBD_1_PT_1 "Diagnose_Status_OBD_1_Antriebsstrang_1";
BA_ "SysSignalName" SG_ 768 DIAG_ST_OBD_1_PT_1 "DIAG_ST_OBD_1_PT_1";
BA_ "CompuMethodName" SG_ 768 DIAG_ST_OBD_1_PT_2 "DIAG_ST_OBD";
BA_ "ISignalName" SG_ 768 DIAG_ST_OBD_1_PT_2 "DIAG_ST_OBD_1_PT_2";
BA_ "LongName" SG_ 768 DIAG_ST_OBD_1_PT_2 "Diagnose_Status_OBD_1_Antriebsstrang_2";
BA_ "SysSignalName" SG_ 768 DIAG_ST_OBD_1_PT_2 "DIAG_ST_OBD_1_PT_2";
BA_ "CompuMethodName" SG_ 768 DIAG_ST_OBD_1_PT_3 "DIAG_ST_OBD";
BA_ "ISignalName" SG_ 768 DIAG_ST_OBD_1_PT_3 "DIAG_ST_OBD_1_PT_3";
BA_ "LongName" SG_ 768 DIAG_ST_OBD_1_PT_3 "Diagnose_Status_OBD_1_Antriebsstrang_3";
BA_ "SysSignalName" SG_ 768 DIAG_ST_OBD_1_PT_3 "DIAG_ST_OBD_1_PT_3";
BA_ "CompuMethodName" SG_ 768 DIAG_ST_OBD_1_PT_4 "DIAG_ST_OBD";
BA_ "ISignalName" SG_ 768 DIAG_ST_OBD_1_PT_4 "DIAG_ST_OBD_1_PT_4";
BA_ "LongName" SG_ 768 DIAG_ST_OBD_1_PT_4 "Diagnose_Status_OBD_1_Antriebsstrang_4";
BA_ "SysSignalName" SG_ 768 DIAG_ST_OBD_1_PT_4 "DIAG_ST_OBD_1_PT_4";
BA_ "CompuMethodName" SG_ 768 DIAG_ST_OBD_1_PT_5 "DIAG_ST_OBD";
BA_ "ISignalName" SG_ 768 DIAG_ST_OBD_1_PT_5 "DIAG_ST_OBD_1_PT_5";
BA_ "LongName" SG_ 768 DIAG_ST_OBD_1_PT_5 "Diagnose_Status_OBD_1_Antriebsstrang_5";
BA_ "SysSignalName" SG_ 768 DIAG_ST_OBD_1_PT_5 "DIAG_ST_OBD_1_PT_5";
BA_ "CompuMethodName" SG_ 768 DIAG_ST_OBD_1_PT_6 "DIAG_ST_OBD";
BA_ "ISignalName" SG_ 768 DIAG_ST_OBD_1_PT_6 "DIAG_ST_OBD_1_PT_6";
BA_ "LongName" SG_ 768 DIAG_ST_OBD_1_PT_6 "Diagnose_Status_OBD_1_Antriebsstrang_6";
BA_ "SysSignalName" SG_ 768 DIAG_ST_OBD_1_PT_6 "DIAG_ST_OBD_1_PT_6";
BA_ "CompuMethodName" SG_ 768 DIAG_ST_OBD_1_PT_7 "DIAG_ST_OBD";
BA_ "ISignalName" SG_ 768 DIAG_ST_OBD_1_PT_7 "DIAG_ST_OBD_1_PT_7";
BA_ "LongName" SG_ 768 DIAG_ST_OBD_1_PT_7 "Diagnose_Status_OBD_1_Antriebsstrang_7";
BA_ "SysSignalName" SG_ 768 DIAG_ST_OBD_1_PT_7 "DIAG_ST_OBD_1_PT_7";
BA_ "CompuMethodName" SG_ 768 DIAG_ST_OBD_1_PT_8 "DIAG_ST_OBD";
BA_ "ISignalName" SG_ 768 DIAG_ST_OBD_1_PT_8 "DIAG_ST_OBD_1_PT_8";
BA_ "LongName" SG_ 768 DIAG_ST_OBD_1_PT_8 "Diagnose_Status_OBD_1_Antriebsstrang_8";
BA_ "SysSignalName" SG_ 768 DIAG_ST_OBD_1_PT_8 "DIAG_ST_OBD_1_PT_8";
BA_ "CompuMethodName" SG_ 983 ALIV_ST_DIAG_OBD_7_PT "ALIV_4_BIT_Unsigned_Integer";
BA_ "ISignalName" SG_ 983 ALIV_ST_DIAG_OBD_7_PT "ALIV_ST_DIAG_OBD_7_PT";
BA_ "LongName" SG_ 983 ALIV_ST_DIAG_OBD_7_PT "Alive_Status_Diagnose_OBD_7_Antriebsstrang";
BA_ "SysSignalName" SG_ 983 ALIV_ST_DIAG_OBD_7_PT "ALIV_ST_DIAG_OBD_7_PT";
BA_ "CompuMethodName" SG_ 983 ST_DIAG_OBD_7_PT_MAX_MUX "ST_DIAG_OBD_MUX_MAX";
BA_ "GenSigStartValue" SG_ 983 ST_DIAG_OBD_7_PT_MAX_MUX 4;
BA_ "ISignalName" SG_ 983 ST_DIAG_OBD_7_PT_MAX_MUX "ST_DIAG_OBD_7_PT_MAX_MUX";
BA_ "LongName" SG_ 983 ST_DIAG_OBD_7_PT_MAX_MUX "Status_Diagnose_OBD_7_Antriebsstrang_Maximal_Multiplexer";
BA_ "SysSignalName" SG_ 983 ST_DIAG_OBD_7_PT_MAX_MUX "ST_DIAG_OBD_7_PT_MAX_MUX";
BA_ "CompuMethodName" SG_ 983 ST_DIAG_OBD_7_PT_IMME_MUX "ST_DIAG_OBD_X_PT_IMME_MUX";
BA_ "ISignalName" SG_ 983 ST_DIAG_OBD_7_PT_IMME_MUX "ST_DIAG_OBD_7_PT_IMME_MUX";
BA_ "LongName" SG_ 983 ST_DIAG_OBD_7_PT_IMME_MUX "Status_Diagnose_OBD_7_Antriebsstrang_Aktuell_Multiplexer";
BA_ "SysSignalName" SG_ 983 ST_DIAG_OBD_7_PT_IMME_MUX "ST_DIAG_OBD_7_PT_IMME_MUX";
BA_ "CompuMethodName" SG_ 983 DIAG_ST_OBD_7_PT_1 "DIAG_ST_OBD";
BA_ "ISignalName" SG_ 983 DIAG_ST_OBD_7_PT_1 "DIAG_ST_OBD_7_PT_1";
BA_ "LongName" SG_ 983 DIAG_ST_OBD_7_PT_1 "Diagnose_Status_OBD_7_Antriebsstrang_1";
BA_ "SysSignalName" SG_ 983 DIAG_ST_OBD_7_PT_1 "DIAG_ST_OBD_7_PT_1";
BA_ "CompuMethodName" SG_ 983 DIAG_ST_OBD_7_PT_2 "DIAG_ST_OBD";
BA_ "ISignalName" SG_ 983 DIAG_ST_OBD_7_PT_2 "DIAG_ST_OBD_7_PT_2";
BA_ "LongName" SG_ 983 DIAG_ST_OBD_7_PT_2 "Diagnose_Status_OBD_7_Antriebsstrang_2";
BA_ "SysSignalName" SG_ 983 DIAG_ST_OBD_7_PT_2 "DIAG_ST_OBD_7_PT_2";
BA_ "CompuMethodName" SG_ 983 DIAG_ST_OBD_7_PT_3 "DIAG_ST_OBD";
BA_ "ISignalName" SG_ 983 DIAG_ST_OBD_7_PT_3 "DIAG_ST_OBD_7_PT_3";
BA_ "LongName" SG_ 983 DIAG_ST_OBD_7_PT_3 "Diagnose_Status_OBD_7_Antriebsstrang_3";
BA_ "SysSignalName" SG_ 983 DIAG_ST_OBD_7_PT_3 "DIAG_ST_OBD_7_PT_3";
BA_ "CompuMethodName" SG_ 983 DIAG_ST_OBD_7_PT_4 "DIAG_ST_OBD";
BA_ "ISignalName" SG_ 983 DIAG_ST_OBD_7_PT_4 "DIAG_ST_OBD_7_PT_4";
BA_ "LongName" SG_ 983 DIAG_ST_OBD_7_PT_4 "Diagnose_Status_OBD_7_Antriebsstrang_4";
BA_ "SysSignalName" SG_ 983 DIAG_ST_OBD_7_PT_4 "DIAG_ST_OBD_7_PT_4";
BA_ "CompuMethodName" SG_ 983 DIAG_ST_OBD_7_PT_5 "DIAG_ST_OBD";
BA_ "ISignalName" SG_ 983 DIAG_ST_OBD_7_PT_5 "DIAG_ST_OBD_7_PT_5";
BA_ "LongName" SG_ 983 DIAG_ST_OBD_7_PT_5 "Diagnose_Status_OBD_7_Antriebsstrang_5";
BA_ "SysSignalName" SG_ 983 DIAG_ST_OBD_7_PT_5 "DIAG_ST_OBD_7_PT_5";
BA_ "CompuMethodName" SG_ 983 DIAG_ST_OBD_7_PT_6 "DIAG_ST_OBD";
BA_ "ISignalName" SG_ 983 DIAG_ST_OBD_7_PT_6 "DIAG_ST_OBD_7_PT_6";
BA_ "LongName" SG_ 983 DIAG_ST_OBD_7_PT_6 "Diagnose_Status_OBD_7_Antriebsstrang_6";
BA_ "SysSignalName" SG_ 983 DIAG_ST_OBD_7_PT_6 "DIAG_ST_OBD_7_PT_6";
BA_ "CompuMethodName" SG_ 983 DIAG_ST_OBD_7_PT_7 "DIAG_ST_OBD";
BA_ "ISignalName" SG_ 983 DIAG_ST_OBD_7_PT_7 "DIAG_ST_OBD_7_PT_7";
BA_ "LongName" SG_ 983 DIAG_ST_OBD_7_PT_7 "Diagnose_Status_OBD_7_Antriebsstrang_7";
BA_ "SysSignalName" SG_ 983 DIAG_ST_OBD_7_PT_7 "DIAG_ST_OBD_7_PT_7";
BA_ "CompuMethodName" SG_ 983 DIAG_ST_OBD_7_PT_8 "DIAG_ST_OBD";
BA_ "ISignalName" SG_ 983 DIAG_ST_OBD_7_PT_8 "DIAG_ST_OBD_7_PT_8";
BA_ "LongName" SG_ 983 DIAG_ST_OBD_7_PT_8 "Diagnose_Status_OBD_7_Antriebsstrang_8";
BA_ "SysSignalName" SG_ 983 DIAG_ST_OBD_7_PT_8 "DIAG_ST_OBD_7_PT_8";
BA_ "CompuMethodName" SG_ 991 ALIV_SLV_1_ST_DIAG_OBD "ALIV_4_BIT_Unsigned_Integer";
BA_ "ISignalName" SG_ 991 ALIV_SLV_1_ST_DIAG_OBD "ALIV_SLV_1_ST_DIAG_OBD";
BA_ "LongName" SG_ 991 ALIV_SLV_1_ST_DIAG_OBD "Alive_Slave_1_Status_Diagnose_OBD";
BA_ "SysSignalName" SG_ 991 ALIV_SLV_1_ST_DIAG_OBD "ALIV_SLV_1_ST_DIAG_OBD";
BA_ "CompuMethodName" SG_ 991 SLV_1_ST_DIAG_OBD_MAX_MUX "ST_DIAG_OBD_MUX_MAX";
BA_ "GenSigStartValue" SG_ 991 SLV_1_ST_DIAG_OBD_MAX_MUX 4;
BA_ "ISignalName" SG_ 991 SLV_1_ST_DIAG_OBD_MAX_MUX "SLV_1_ST_DIAG_OBD_MAX_MUX";
BA_ "LongName" SG_ 991 SLV_1_ST_DIAG_OBD_MAX_MUX "Slave_1_Status_Diagnose_OBD_Maximal_Multiplexer";
BA_ "SysSignalName" SG_ 991 SLV_1_ST_DIAG_OBD_MAX_MUX "SLV_1_ST_DIAG_OBD_MAX_MUX";
BA_ "CompuMethodName" SG_ 991 SLV_1_ST_DIAG_OBD_IMME_MUX "ST_DIAG_OBD_MUX_IMME";
BA_ "GenSigStartValue" SG_ 991 SLV_1_ST_DIAG_OBD_IMME_MUX 4;
BA_ "ISignalName" SG_ 991 SLV_1_ST_DIAG_OBD_IMME_MUX "SLV_1_ST_DIAG_OBD_IMME_MUX";
BA_ "LongName" SG_ 991 SLV_1_ST_DIAG_OBD_IMME_MUX "Slave_1_Status_Diagnose_OBD_Aktuell_Multiplexer";
BA_ "SysSignalName" SG_ 991 SLV_1_ST_DIAG_OBD_IMME_MUX "SLV_1_ST_DIAG_OBD_IMME_MUX";
BA_ "CompuMethodName" SG_ 991 SLV_1_DIAG_ST_1_OBD "DIAG_ST_OBD";
BA_ "ISignalName" SG_ 991 SLV_1_DIAG_ST_1_OBD "SLV_1_DIAG_ST_1_OBD";
BA_ "LongName" SG_ 991 SLV_1_DIAG_ST_1_OBD "Slave_1_Diagnose_Status_1_OBD";
BA_ "SysSignalName" SG_ 991 SLV_1_DIAG_ST_1_OBD "SLV_1_DIAG_ST_1_OBD";
BA_ "CompuMethodName" SG_ 991 SLV_1_DIAG_ST_2_OBD "DIAG_ST_OBD";
BA_ "ISignalName" SG_ 991 SLV_1_DIAG_ST_2_OBD "SLV_1_DIAG_ST_2_OBD";
BA_ "LongName" SG_ 991 SLV_1_DIAG_ST_2_OBD "Slave_1_Diagnose_Status_2_OBD";
BA_ "SysSignalName" SG_ 991 SLV_1_DIAG_ST_2_OBD "SLV_1_DIAG_ST_2_OBD";
BA_ "CompuMethodName" SG_ 991 SLV_1_DIAG_ST_3_OBD "DIAG_ST_OBD";
BA_ "ISignalName" SG_ 991 SLV_1_DIAG_ST_3_OBD "SLV_1_DIAG_ST_3_OBD";
BA_ "LongName" SG_ 991 SLV_1_DIAG_ST_3_OBD "Slave_1_Diagnose_Status_3_OBD";
BA_ "SysSignalName" SG_ 991 SLV_1_DIAG_ST_3_OBD "SLV_1_DIAG_ST_3_OBD";
BA_ "CompuMethodName" SG_ 991 SLV_1_DIAG_ST_4_OBD "DIAG_ST_OBD";
BA_ "ISignalName" SG_ 991 SLV_1_DIAG_ST_4_OBD "SLV_1_DIAG_ST_4_OBD";
BA_ "LongName" SG_ 991 SLV_1_DIAG_ST_4_OBD "Slave_1_Diagnose_Status_4_OBD";
BA_ "SysSignalName" SG_ 991 SLV_1_DIAG_ST_4_OBD "SLV_1_DIAG_ST_4_OBD";
BA_ "CompuMethodName" SG_ 991 SLV_1_DIAG_ST_5_OBD "DIAG_ST_OBD";
BA_ "ISignalName" SG_ 991 SLV_1_DIAG_ST_5_OBD "SLV_1_DIAG_ST_5_OBD";
BA_ "LongName" SG_ 991 SLV_1_DIAG_ST_5_OBD "Slave_1_Diagnose_Status_5_OBD";
BA_ "SysSignalName" SG_ 991 SLV_1_DIAG_ST_5_OBD "SLV_1_DIAG_ST_5_OBD";
BA_ "CompuMethodName" SG_ 991 SLV_1_DIAG_ST_6_OBD "DIAG_ST_OBD";
BA_ "ISignalName" SG_ 991 SLV_1_DIAG_ST_6_OBD "SLV_1_DIAG_ST_6_OBD";
BA_ "LongName" SG_ 991 SLV_1_DIAG_ST_6_OBD "Slave_1_Diagnose_Status_6_OBD";
BA_ "SysSignalName" SG_ 991 SLV_1_DIAG_ST_6_OBD "SLV_1_DIAG_ST_6_OBD";
BA_ "CompuMethodName" SG_ 991 SLV_1_DIAG_ST_7_OBD "DIAG_ST_OBD";
BA_ "ISignalName" SG_ 991 SLV_1_DIAG_ST_7_OBD "SLV_1_DIAG_ST_7_OBD";
BA_ "LongName" SG_ 991 SLV_1_DIAG_ST_7_OBD "Slave_1_Diagnose_Status_7_OBD";
BA_ "SysSignalName" SG_ 991 SLV_1_DIAG_ST_7_OBD "SLV_1_DIAG_ST_7_OBD";
BA_ "CompuMethodName" SG_ 991 SLV_1_DIAG_ST_8_OBD "DIAG_ST_OBD";
BA_ "ISignalName" SG_ 991 SLV_1_DIAG_ST_8_OBD "SLV_1_DIAG_ST_8_OBD";
BA_ "LongName" SG_ 991 SLV_1_DIAG_ST_8_OBD "Slave_1_Diagnose_Status_8_OBD";
BA_ "SysSignalName" SG_ 991 SLV_1_DIAG_ST_8_OBD "SLV_1_DIAG_ST_8_OBD";
BA_ "CompuMethodName" SG_ 992 ALIV_SLV_2_ST_DIAG_OBD "ALIV_4_BIT_Unsigned_Integer";
BA_ "ISignalName" SG_ 992 ALIV_SLV_2_ST_DIAG_OBD "ALIV_SLV_2_ST_DIAG_OBD";
BA_ "LongName" SG_ 992 ALIV_SLV_2_ST_DIAG_OBD "Alive_Slave_2_Status_Diagnose_OBD";
BA_ "SysSignalName" SG_ 992 ALIV_SLV_2_ST_DIAG_OBD "ALIV_SLV_2_ST_DIAG_OBD";
BA_ "CompuMethodName" SG_ 992 SLV_2_ST_DIAG_OBD_MAX_MUX "ST_DIAG_OBD_MUX_MAX";
BA_ "GenSigStartValue" SG_ 992 SLV_2_ST_DIAG_OBD_MAX_MUX 4;
BA_ "ISignalName" SG_ 992 SLV_2_ST_DIAG_OBD_MAX_MUX "SLV_2_ST_DIAG_OBD_MAX_MUX";
BA_ "LongName" SG_ 992 SLV_2_ST_DIAG_OBD_MAX_MUX "Slave_2_Status_Diagnose_OBD_Maximal_Multiplexer";
BA_ "SysSignalName" SG_ 992 SLV_2_ST_DIAG_OBD_MAX_MUX "SLV_2_ST_DIAG_OBD_MAX_MUX";
BA_ "CompuMethodName" SG_ 992 SLV_2_ST_DIAG_OBD_IMME_MUX "ST_DIAG_OBD_MUX_IMME";
BA_ "GenSigStartValue" SG_ 992 SLV_2_ST_DIAG_OBD_IMME_MUX 4;
BA_ "ISignalName" SG_ 992 SLV_2_ST_DIAG_OBD_IMME_MUX "SLV_2_ST_DIAG_OBD_IMME_MUX";
BA_ "LongName" SG_ 992 SLV_2_ST_DIAG_OBD_IMME_MUX "Slave_2_Status_Diagnose_OBD_Aktuell_Multiplexer";
BA_ "SysSignalName" SG_ 992 SLV_2_ST_DIAG_OBD_IMME_MUX "SLV_2_ST_DIAG_OBD_IMME_MUX";
BA_ "CompuMethodName" SG_ 992 SLV_2_DIAG_ST_1_OBD "DIAG_ST_OBD";
BA_ "ISignalName" SG_ 992 SLV_2_DIAG_ST_1_OBD "SLV_2_DIAG_ST_1_OBD";
BA_ "LongName" SG_ 992 SLV_2_DIAG_ST_1_OBD "Slave_2_Diagnose_Status_1_OBD";
BA_ "SysSignalName" SG_ 992 SLV_2_DIAG_ST_1_OBD "SLV_2_DIAG_ST_1_OBD";
BA_ "CompuMethodName" SG_ 992 SLV_2_DIAG_ST_2_OBD "DIAG_ST_OBD";
BA_ "ISignalName" SG_ 992 SLV_2_DIAG_ST_2_OBD "SLV_2_DIAG_ST_2_OBD";
BA_ "LongName" SG_ 992 SLV_2_DIAG_ST_2_OBD "Slave_2_Diagnose_Status_2_OBD";
BA_ "SysSignalName" SG_ 992 SLV_2_DIAG_ST_2_OBD "SLV_2_DIAG_ST_2_OBD";
BA_ "CompuMethodName" SG_ 992 SLV_2_DIAG_ST_3_OBD "DIAG_ST_OBD";
BA_ "ISignalName" SG_ 992 SLV_2_DIAG_ST_3_OBD "SLV_2_DIAG_ST_3_OBD";
BA_ "LongName" SG_ 992 SLV_2_DIAG_ST_3_OBD "Slave_2_Diagnose_Status_3_OBD";
BA_ "SysSignalName" SG_ 992 SLV_2_DIAG_ST_3_OBD "SLV_2_DIAG_ST_3_OBD";
BA_ "CompuMethodName" SG_ 992 SLV_2_DIAG_ST_4_OBD "DIAG_ST_OBD";
BA_ "ISignalName" SG_ 992 SLV_2_DIAG_ST_4_OBD "SLV_2_DIAG_ST_4_OBD";
BA_ "LongName" SG_ 992 SLV_2_DIAG_ST_4_OBD "Slave_2_Diagnose_Status_4_OBD";
BA_ "SysSignalName" SG_ 992 SLV_2_DIAG_ST_4_OBD "SLV_2_DIAG_ST_4_OBD";
BA_ "CompuMethodName" SG_ 992 SLV_2_DIAG_ST_5_OBD "DIAG_ST_OBD";
BA_ "ISignalName" SG_ 992 SLV_2_DIAG_ST_5_OBD "SLV_2_DIAG_ST_5_OBD";
BA_ "LongName" SG_ 992 SLV_2_DIAG_ST_5_OBD "Slave_2_Diagnose_Status_5_OBD";
BA_ "SysSignalName" SG_ 992 SLV_2_DIAG_ST_5_OBD "SLV_2_DIAG_ST_5_OBD";
BA_ "CompuMethodName" SG_ 992 SLV_2_DIAG_ST_6_OBD "DIAG_ST_OBD";
BA_ "ISignalName" SG_ 992 SLV_2_DIAG_ST_6_OBD "SLV_2_DIAG_ST_6_OBD";
BA_ "LongName" SG_ 992 SLV_2_DIAG_ST_6_OBD "Slave_2_Diagnose_Status_6_OBD";
BA_ "SysSignalName" SG_ 992 SLV_2_DIAG_ST_6_OBD "SLV_2_DIAG_ST_6_OBD";
BA_ "CompuMethodName" SG_ 992 SLV_2_DIAG_ST_7_OBD "DIAG_ST_OBD";
BA_ "ISignalName" SG_ 992 SLV_2_DIAG_ST_7_OBD "SLV_2_DIAG_ST_7_OBD";
BA_ "LongName" SG_ 992 SLV_2_DIAG_ST_7_OBD "Slave_2_Diagnose_Status_7_OBD";
BA_ "SysSignalName" SG_ 992 SLV_2_DIAG_ST_7_OBD "SLV_2_DIAG_ST_7_OBD";
BA_ "CompuMethodName" SG_ 992 SLV_2_DIAG_ST_8_OBD "DIAG_ST_OBD";
BA_ "ISignalName" SG_ 992 SLV_2_DIAG_ST_8_OBD "SLV_2_DIAG_ST_8_OBD";
BA_ "LongName" SG_ 992 SLV_2_DIAG_ST_8_OBD "Slave_2_Diagnose_Status_8_OBD";
BA_ "SysSignalName" SG_ 992 SLV_2_DIAG_ST_8_OBD "SLV_2_DIAG_ST_8_OBD";
BA_ "CompuMethodName" SG_ 993 ALIV_SLV_3_ST_DIAG_OBD "ALIV_4_BIT_Unsigned_Integer";
BA_ "ISignalName" SG_ 993 ALIV_SLV_3_ST_DIAG_OBD "ALIV_SLV_3_ST_DIAG_OBD";
BA_ "LongName" SG_ 993 ALIV_SLV_3_ST_DIAG_OBD "Alive_Slave_3_Status_Diagnose_OBD";
BA_ "SysSignalName" SG_ 993 ALIV_SLV_3_ST_DIAG_OBD "ALIV_SLV_3_ST_DIAG_OBD";
BA_ "CompuMethodName" SG_ 993 SLV_3_ST_DIAG_OBD_MAX_MUX "ST_DIAG_OBD_MUX_MAX";
BA_ "GenSigStartValue" SG_ 993 SLV_3_ST_DIAG_OBD_MAX_MUX 4;
BA_ "ISignalName" SG_ 993 SLV_3_ST_DIAG_OBD_MAX_MUX "SLV_3_ST_DIAG_OBD_MAX_MUX";
BA_ "LongName" SG_ 993 SLV_3_ST_DIAG_OBD_MAX_MUX "Slave_3_Status_Diagnose_OBD_Maximal_Multiplexer";
BA_ "SysSignalName" SG_ 993 SLV_3_ST_DIAG_OBD_MAX_MUX "SLV_3_ST_DIAG_OBD_MAX_MUX";
BA_ "CompuMethodName" SG_ 993 SLV_3_ST_DIAG_OBD_IMME_MUX "ST_DIAG_OBD_MUX_IMME";
BA_ "GenSigStartValue" SG_ 993 SLV_3_ST_DIAG_OBD_IMME_MUX 4;
BA_ "ISignalName" SG_ 993 SLV_3_ST_DIAG_OBD_IMME_MUX "SLV_3_ST_DIAG_OBD_IMME_MUX";
BA_ "LongName" SG_ 993 SLV_3_ST_DIAG_OBD_IMME_MUX "Slave_3_Status_Diagnose_OBD_Aktuell_Multiplexer";
BA_ "SysSignalName" SG_ 993 SLV_3_ST_DIAG_OBD_IMME_MUX "SLV_3_ST_DIAG_OBD_IMME_MUX";
BA_ "CompuMethodName" SG_ 993 SLV_3_DIAG_ST_1_OBD "DIAG_ST_OBD";
BA_ "ISignalName" SG_ 993 SLV_3_DIAG_ST_1_OBD "SLV_3_DIAG_ST_1_OBD";
BA_ "LongName" SG_ 993 SLV_3_DIAG_ST_1_OBD "Slave_3_Diagnose_Status_1_OBD";
BA_ "SysSignalName" SG_ 993 SLV_3_DIAG_ST_1_OBD "SLV_3_DIAG_ST_1_OBD";
BA_ "CompuMethodName" SG_ 993 SLV_3_DIAG_ST_2_OBD "DIAG_ST_OBD";
BA_ "ISignalName" SG_ 993 SLV_3_DIAG_ST_2_OBD "SLV_3_DIAG_ST_2_OBD";
BA_ "LongName" SG_ 993 SLV_3_DIAG_ST_2_OBD "Slave_3_Diagnose_Status_2_OBD";
BA_ "SysSignalName" SG_ 993 SLV_3_DIAG_ST_2_OBD "SLV_3_DIAG_ST_2_OBD";
BA_ "CompuMethodName" SG_ 993 SLV_3_DIAG_ST_3_OBD "DIAG_ST_OBD";
BA_ "ISignalName" SG_ 993 SLV_3_DIAG_ST_3_OBD "SLV_3_DIAG_ST_3_OBD";
BA_ "LongName" SG_ 993 SLV_3_DIAG_ST_3_OBD "Slave_3_Diagnose_Status_3_OBD";
BA_ "SysSignalName" SG_ 993 SLV_3_DIAG_ST_3_OBD "SLV_3_DIAG_ST_3_OBD";
BA_ "CompuMethodName" SG_ 993 SLV_3_DIAG_ST_4_OBD "DIAG_ST_OBD";
BA_ "ISignalName" SG_ 993 SLV_3_DIAG_ST_4_OBD "SLV_3_DIAG_ST_4_OBD";
BA_ "LongName" SG_ 993 SLV_3_DIAG_ST_4_OBD "Slave_3_Diagnose_Status_4_OBD";
BA_ "SysSignalName" SG_ 993 SLV_3_DIAG_ST_4_OBD "SLV_3_DIAG_ST_4_OBD";
BA_ "CompuMethodName" SG_ 993 SLV_3_DIAG_ST_5_OBD "DIAG_ST_OBD";
BA_ "ISignalName" SG_ 993 SLV_3_DIAG_ST_5_OBD "SLV_3_DIAG_ST_5_OBD";
BA_ "LongName" SG_ 993 SLV_3_DIAG_ST_5_OBD "Slave_3_Diagnose_Status_5_OBD";
BA_ "SysSignalName" SG_ 993 SLV_3_DIAG_ST_5_OBD "SLV_3_DIAG_ST_5_OBD";
BA_ "CompuMethodName" SG_ 993 SLV_3_DIAG_ST_6_OBD "DIAG_ST_OBD";
BA_ "ISignalName" SG_ 993 SLV_3_DIAG_ST_6_OBD "SLV_3_DIAG_ST_6_OBD";
BA_ "LongName" SG_ 993 SLV_3_DIAG_ST_6_OBD "Slave_3_Diagnose_Status_6_OBD";
BA_ "SysSignalName" SG_ 993 SLV_3_DIAG_ST_6_OBD "SLV_3_DIAG_ST_6_OBD";
BA_ "CompuMethodName" SG_ 993 SLV_3_DIAG_ST_7_OBD "DIAG_ST_OBD";
BA_ "ISignalName" SG_ 993 SLV_3_DIAG_ST_7_OBD "SLV_3_DIAG_ST_7_OBD";
BA_ "LongName" SG_ 993 SLV_3_DIAG_ST_7_OBD "Slave_3_Diagnose_Status_7_OBD";
BA_ "SysSignalName" SG_ 993 SLV_3_DIAG_ST_7_OBD "SLV_3_DIAG_ST_7_OBD";
BA_ "CompuMethodName" SG_ 993 SLV_3_DIAG_ST_8_OBD "DIAG_ST_OBD";
BA_ "ISignalName" SG_ 993 SLV_3_DIAG_ST_8_OBD "SLV_3_DIAG_ST_8_OBD";
BA_ "LongName" SG_ 993 SLV_3_DIAG_ST_8_OBD "Slave_3_Diagnose_Status_8_OBD";
BA_ "SysSignalName" SG_ 993 SLV_3_DIAG_ST_8_OBD "SLV_3_DIAG_ST_8_OBD";
BA_ "CompuMethodName" SG_ 960 ST_DISP_BLTW_TIR_1_LH "ST_DISP_BLTW_TIR";
BA_ "ISignalName" SG_ 960 ST_DISP_BLTW_TIR_1_LH "ST_DISP_BLTW_TIR_1_LH";
BA_ "LongName" SG_ 960 ST_DISP_BLTW_TIR_1_LH "Status_Anzeige_Gurtwarnung_Sitzreihe_1_Links";
BA_ "SysSignalName" SG_ 960 ST_DISP_BLTW_TIR_1_LH "ST_DISP_BLTW_TIR_1_LH";
BA_ "CompuMethodName" SG_ 960 ST_DISP_BLTW_TIR_1_RH "ST_DISP_BLTW_TIR";
BA_ "ISignalName" SG_ 960 ST_DISP_BLTW_TIR_1_RH "ST_DISP_BLTW_TIR_1_RH";
BA_ "LongName" SG_ 960 ST_DISP_BLTW_TIR_1_RH "Status_Anzeige_Gurtwarnung_Sitzreihe_1_Rechts";
BA_ "SysSignalName" SG_ 960 ST_DISP_BLTW_TIR_1_RH "ST_DISP_BLTW_TIR_1_RH";
BA_ "CompuMethodName" SG_ 960 ST_DISP_BLTW_TIR_2_RH "ST_DISP_BLTW_TIR";
BA_ "ISignalName" SG_ 960 ST_DISP_BLTW_TIR_2_RH "ST_DISP_BLTW_TIR_2_RH";
BA_ "LongName" SG_ 960 ST_DISP_BLTW_TIR_2_RH "Status_Anzeige_Gurtwarnung_Sitzreihe_2_Rechts";
BA_ "SysSignalName" SG_ 960 ST_DISP_BLTW_TIR_2_RH "ST_DISP_BLTW_TIR_2_RH";
BA_ "CompuMethodName" SG_ 960 ST_DISP_BLTW_TIR_2_MID "ST_DISP_BLTW_TIR";
BA_ "ISignalName" SG_ 960 ST_DISP_BLTW_TIR_2_MID "ST_DISP_BLTW_TIR_2_MID";
BA_ "LongName" SG_ 960 ST_DISP_BLTW_TIR_2_MID "Status_Anzeige_Gurtwarnung_Sitzreihe_2_Mitte";
BA_ "SysSignalName" SG_ 960 ST_DISP_BLTW_TIR_2_MID "ST_DISP_BLTW_TIR_2_MID";
BA_ "CompuMethodName" SG_ 960 ST_DISP_BLTW_TIR_2_LH "ST_DISP_BLTW_TIR";
BA_ "ISignalName" SG_ 960 ST_DISP_BLTW_TIR_2_LH "ST_DISP_BLTW_TIR_2_LH";
BA_ "LongName" SG_ 960 ST_DISP_BLTW_TIR_2_LH "Status_Anzeige_Gurtwarnung_Sitzreihe_2_Links";
BA_ "SysSignalName" SG_ 960 ST_DISP_BLTW_TIR_2_LH "ST_DISP_BLTW_TIR_2_LH";
BA_ "CompuMethodName" SG_ 960 ST_DISP_BLTW_TIR_3_RH "ST_DISP_BLTW_TIR";
BA_ "ISignalName" SG_ 960 ST_DISP_BLTW_TIR_3_RH "ST_DISP_BLTW_TIR_3_RH";
BA_ "LongName" SG_ 960 ST_DISP_BLTW_TIR_3_RH "Status_Anzeige_Gurtwarnung_Sitzreihe_3_Rechts";
BA_ "SysSignalName" SG_ 960 ST_DISP_BLTW_TIR_3_RH "ST_DISP_BLTW_TIR_3_RH";
BA_ "CompuMethodName" SG_ 960 ST_DISP_BLTW_TIR_3_LH "ST_DISP_BLTW_TIR";
BA_ "ISignalName" SG_ 960 ST_DISP_BLTW_TIR_3_LH "ST_DISP_BLTW_TIR_3_LH";
BA_ "LongName" SG_ 960 ST_DISP_BLTW_TIR_3_LH "Status_Anzeige_Gurtwarnung_Sitzreihe_3_Links";
BA_ "SysSignalName" SG_ 960 ST_DISP_BLTW_TIR_3_LH "ST_DISP_BLTW_TIR_3_LH";
BA_ "CompuMethodName" SG_ 448 CRC_ST_DISP_DRASY "CRC8";
BA_ "ISignalName" SG_ 448 CRC_ST_DISP_DRASY "CRC_ST_DISP_DRASY";
BA_ "LongName" SG_ 448 CRC_ST_DISP_DRASY "CRC_Status_Anzeige_Fahrerassistenzsystem";
BA_ "SysSignalName" SG_ 448 CRC_ST_DISP_DRASY "CRC_ST_DISP_DRASY";
BA_ "CompuMethodName" SG_ 448 ALIV_ST_DISP_DRASY "ALIV_4_BIT_Unsigned_Integer";
BA_ "ISignalName" SG_ 448 ALIV_ST_DISP_DRASY "ALIV_ST_DISP_DRASY";
BA_ "LongName" SG_ 448 ALIV_ST_DISP_DRASY "Alive_Status_Anzeige_Fahrerassistenzsystem";
BA_ "SysSignalName" SG_ 448 ALIV_ST_DISP_DRASY "ALIV_ST_DISP_DRASY";
BA_ "CompuMethodName" SG_ 448 CHL_ST_DISP_DRASY "CHL_4_UInt";
BA_ "ISignalName" SG_ 448 CHL_ST_DISP_DRASY "CHL_ST_DISP_DRASY";
BA_ "LongName" SG_ 448 CHL_ST_DISP_DRASY "CHL_Status_Anzeige_Fahrerassistenzsystem";
BA_ "SysSignalName" SG_ 448 CHL_ST_DISP_DRASY "CHL_ST_DISP_DRASY";
BA_ "CompuMethodName" SG_ 448 AVL_V_SPDM_2 "AVL_V_SPDM_2";
BA_ "ISignalName" SG_ 448 AVL_V_SPDM_2 "AVL_V_SPDM_2";
BA_ "LongName" SG_ 448 AVL_V_SPDM_2 "Ist_Geschwindigkeit_Tacho_2";
BA_ "SysSignalName" SG_ 448 AVL_V_SPDM_2 "AVL_V_SPDM_2";
BA_ "CompuMethodName" SG_ 448 UN_V_SPDM "UN_V_SPDM";
BA_ "ISignalName" SG_ 448 UN_V_SPDM "UN_V_SPDM";
BA_ "LongName" SG_ 448 UN_V_SPDM "Einheit_Geschwindigkeit_Tacho";
BA_ "SysSignalName" SG_ 448 UN_V_SPDM "UN_V_SPDM";
BA_ "CompuMethodName" SG_ 448 ST_DISP_PMA "ST_DISP_PMA";
BA_ "ISignalName" SG_ 448 ST_DISP_PMA "ST_DISP_PMA";
BA_ "LongName" SG_ 448 ST_DISP_PMA "Status_Anzeige_Parkassistent";
BA_ "SysSignalName" SG_ 448 ST_DISP_PMA "ST_DISP_PMA";
BA_ "CompuMethodName" SG_ 448 AVAI_DISP_KI "AVAI_DISP_KI";
BA_ "ISignalName" SG_ 448 AVAI_DISP_KI "AVAI_DISP_KI";
BA_ "LongName" SG_ 448 AVAI_DISP_KI "Verfügbarkeit_Anzeige_Kombi";
BA_ "SysSignalName" SG_ 448 AVAI_DISP_KI "AVAI_DISP_KI";
BA_ "CompuMethodName" SG_ 448 ST_DISP_XCC "ST_DISP_XCC";
BA_ "ISignalName" SG_ 448 ST_DISP_XCC "ST_DISP_XCC";
BA_ "LongName" SG_ 448 ST_DISP_XCC "Status_Anzeige_XCC";
BA_ "SysSignalName" SG_ 448 ST_DISP_XCC "ST_DISP_XCC";
BA_ "CompuMethodName" SG_ 448 ST_DISP_HDC "ST_DISP_HDC";
BA_ "ISignalName" SG_ 448 ST_DISP_HDC "ST_DISP_HDC";
BA_ "LongName" SG_ 448 ST_DISP_HDC "Status_Anzeige_HDC";
BA_ "SysSignalName" SG_ 448 ST_DISP_HDC "ST_DISP_HDC";
BA_ "CompuMethodName" SG_ 448 ST_DISP_SD "ST_DISP_SD";
BA_ "ISignalName" SG_ 448 ST_DISP_SD "ST_DISP_SD";
BA_ "LongName" SG_ 448 ST_DISP_SD "Status_Anzeige_SLD";
BA_ "SysSignalName" SG_ 448 ST_DISP_SD "ST_DISP_SD";
BA_ "CompuMethodName" SG_ 448 ST_DISP_DRASY_LAG "ST_DISP_DRASY_LAG";
BA_ "ISignalName" SG_ 448 ST_DISP_DRASY_LAG "ST_DISP_DRASY_LAG";
BA_ "LongName" SG_ 448 ST_DISP_DRASY_LAG "Status_Anzeige_Fahrerassistenzsystem_Querführung";
BA_ "SysSignalName" SG_ 448 ST_DISP_DRASY_LAG "ST_DISP_DRASY_LAG";
BA_ "CompuMethodName" SG_ 448 ST_DISP_ISA_2 "ST_DISP_ISA_2";
BA_ "ISignalName" SG_ 448 ST_DISP_ISA_2 "ST_DISP_ISA_2";
BA_ "LongName" SG_ 448 ST_DISP_ISA_2 "Status_Anzeige_ISA_2";
BA_ "SysSignalName" SG_ 448 ST_DISP_ISA_2 "ST_DISP_ISA_2";
BA_ "CompuMethodName" SG_ 448 ST_DISP_GAP_INFO_2 "ST_DISP_GAP_INFO_2";
BA_ "ISignalName" SG_ 448 ST_DISP_GAP_INFO_2 "ST_DISP_GAP_INFO_2";
BA_ "LongName" SG_ 448 ST_DISP_GAP_INFO_2 "Status_Anzeige_Abstand_Information_2";
BA_ "SysSignalName" SG_ 448 ST_DISP_GAP_INFO_2 "ST_DISP_GAP_INFO_2";
BA_ "CompuMethodName" SG_ 448 ST_DISP_WBK "ST_DISP_WBK";
BA_ "ISignalName" SG_ 448 ST_DISP_WBK "ST_DISP_WBK";
BA_ "LongName" SG_ 448 ST_DISP_WBK "Status_Anzeige_Warnbremskoordinator";
BA_ "SysSignalName" SG_ 448 ST_DISP_WBK "ST_DISP_WBK";
BA_ "CompuMethodName" SG_ 435 ST_RQ_ACTVN_DYNOMOD "ST_ACTVN_DYNOMOD";
BA_ "ISignalName" SG_ 435 ST_RQ_ACTVN_DYNOMOD "ST_RQ_ACTVN_DYNOMOD";
BA_ "LongName" SG_ 435 ST_RQ_ACTVN_DYNOMOD "Status_Anforderung_Aktivierung_Rollenmodus";
BA_ "SysSignalName" SG_ 435 ST_RQ_ACTVN_DYNOMOD "ST_RQ_ACTVN_DYNOMOD";
BA_ "CompuMethodName" SG_ 435 ST_DISP_KI_M "ST_DISP_KI_M";
BA_ "ISignalName" SG_ 435 ST_DISP_KI_M "ST_DISP_KI_M";
BA_ "LongName" SG_ 435 ST_DISP_KI_M "Status_Anzeige_Kombi_M";
BA_ "SysSignalName" SG_ 435 ST_DISP_KI_M "ST_DISP_KI_M";
BA_ "CompuMethodName" SG_ 435 ST_NO_CC_MESS_DISP "ST_NO_CC_MESS_DISP";
BA_ "ISignalName" SG_ 435 ST_NO_CC_MESS_DISP "ST_NO_CC_MESS_DISP";
BA_ "LongName" SG_ 435 ST_NO_CC_MESS_DISP "Status_Nummer_Checkcontrol_Meldung_Anzeige";
BA_ "SysSignalName" SG_ 435 ST_NO_CC_MESS_DISP "ST_NO_CC_MESS_DISP";
BA_ "CompuMethodName" SG_ 435 ST_DISP_WALI_AB "ST_ABWL";
BA_ "ISignalName" SG_ 435 ST_DISP_WALI_AB "ST_DISP_WALI_AB";
BA_ "LongName" SG_ 435 ST_DISP_WALI_AB "Status_Anzeige_Warnleuchte_Airbag";
BA_ "SysSignalName" SG_ 435 ST_DISP_WALI_AB "ST_DISP_WALI_AB";
BA_ "CompuMethodName" SG_ 435 ST_DISP_WALI_BLT "ST_WALI_BLT";
BA_ "ISignalName" SG_ 435 ST_DISP_WALI_BLT "ST_DISP_WALI_BLT";
BA_ "LongName" SG_ 435 ST_DISP_WALI_BLT "Status_Anzeige_Warnleuchte_Gurt";
BA_ "SysSignalName" SG_ 435 ST_DISP_WALI_BLT "ST_DISP_WALI_BLT";
BA_ "CompuMethodName" SG_ 435 ST_DISP_WALI_ENG "ENUM_2_noIniVal_noDflVal_3_noQuant_noOffs_typeBitField_noRng_131";
BA_ "ISignalName" SG_ 435 ST_DISP_WALI_ENG "ST_DISP_WALI_ENG";
BA_ "LongName" SG_ 435 ST_DISP_WALI_ENG "Status_Anzeige_Warnleuchte_Motor";
BA_ "SysSignalName" SG_ 435 ST_DISP_WALI_ENG "ST_DISP_WALI_ENG";
BA_ "CompuMethodName" SG_ 435 ST_DISP_IDLI_DSC "ENUM_2_noIniVal_noDflVal_3_noQuant_noOffs_typeBitField_noRng_131";
BA_ "ISignalName" SG_ 435 ST_DISP_IDLI_DSC "ST_DISP_IDLI_DSC";
BA_ "LongName" SG_ 435 ST_DISP_IDLI_DSC "status_display_indicator-light_DSC";
BA_ "SysSignalName" SG_ 435 ST_DISP_IDLI_DSC "ST_DISP_IDLI_DSC";
BA_ "CompuMethodName" SG_ 435 CHKSM_ST_DISP_KI "ENUM_8_noIniVal_noDflVal_noErrVal_noQuant_noOffs_typeDomain_noRng_4";
BA_ "ISignalName" SG_ 435 CHKSM_ST_DISP_KI "CHKSM_ST_DISP_KI";
BA_ "LongName" SG_ 435 CHKSM_ST_DISP_KI "Checksumme_Status_Anzeige_Kombi";
BA_ "SysSignalName" SG_ 435 CHKSM_ST_DISP_KI "CHKSM_ST_DISP_KI";
BA_ "CompuMethodName" SG_ 100 CRC_ST_DRVG_RDI "CRC8";
BA_ "ISignalName" SG_ 100 CRC_ST_DRVG_RDI "CRC_ST_DRVG_RDI";
BA_ "LongName" SG_ 100 CRC_ST_DRVG_RDI "CRC_Status_Fahren_Bereitschaft";
BA_ "SysSignalName" SG_ 100 CRC_ST_DRVG_RDI "CRC_ST_DRVG_RDI";
BA_ "CompuMethodName" SG_ 100 ALIV_ST_DRVG_RDI "ALIV_4_BIT_UInt";
BA_ "ISignalName" SG_ 100 ALIV_ST_DRVG_RDI "ALIV_ST_DRVG_RDI";
BA_ "LongName" SG_ 100 ALIV_ST_DRVG_RDI "Alive_Status_Fahren_Bereitschaft";
BA_ "SysSignalName" SG_ 100 ALIV_ST_DRVG_RDI "ALIV_ST_DRVG_RDI";
BA_ "ISignalName" SG_ 100 ST_DRVG_RDI_dummy_12_15 "ST_DRVG_RDI_dummy_12_15";
BA_ "LongName" SG_ 100 ST_DRVG_RDI_dummy_12_15 "ST_DRVG_RDI_dummy_12_15";
BA_ "SysSignalName" SG_ 100 ST_DRVG_RDI_dummy_12_15 "ST_DRVG_RDI_dummy_12_15";
BA_ "CompuMethodName" SG_ 100 ST_DRVG_RDI_DRV "ST_DRVG_RDI_DRV";
BA_ "ISignalName" SG_ 100 ST_DRVG_RDI_DRV "ST_DRVG_RDI_DRV";
BA_ "LongName" SG_ 100 ST_DRVG_RDI_DRV "Status_Fahren_Bereitschaft_Antrieb";
BA_ "SysSignalName" SG_ 100 ST_DRVG_RDI_DRV "ST_DRVG_RDI_DRV";
BA_ "ISignalName" SG_ 100 ST_DRVG_RDI_dummy_20_31 "ST_DRVG_RDI_dummy_20_31";
BA_ "LongName" SG_ 100 ST_DRVG_RDI_dummy_20_31 "ST_DRVG_RDI_dummy_20_31";
BA_ "SysSignalName" SG_ 100 ST_DRVG_RDI_dummy_20_31 "ST_DRVG_RDI_dummy_20_31";
BA_ "ISignalName" SG_ 100 ST_DRVG_RDI_dummy_32_63 "ST_DRVG_RDI_dummy_32_63";
BA_ "LongName" SG_ 100 ST_DRVG_RDI_dummy_32_63 "ST_DRVG_RDI_dummy_32_63";
BA_ "SysSignalName" SG_ 100 ST_DRVG_RDI_dummy_32_63 "ST_DRVG_RDI_dummy_32_63";
BA_ "CompuMethodName" SG_ 707 ALIV_ST_ECAL "Aliv_4";
BA_ "ISignalName" SG_ 707 ALIV_ST_ECAL "ALIV_ST_ECAL";
BA_ "LongName" SG_ 707 ALIV_ST_ECAL "Alive_Status_Notruf";
BA_ "SysSignalName" SG_ 707 ALIV_ST_ECAL "ALIV_ST_ECAL";
BA_ "CompuMethodName" SG_ 707 MUT_ASRC "MUT_ASRC";
BA_ "ISignalName" SG_ 707 MUT_ASRC "MUT_ASRC";
BA_ "LongName" SG_ 707 MUT_ASRC "mute_audio-sources";
BA_ "SysSignalName" SG_ 707 MUT_ASRC "MUT_ASRC";
BA_ "CompuMethodName" SG_ 707 DSCO_CONN_BLUE "DSCO_CONN_BLUE";
BA_ "ISignalName" SG_ 707 DSCO_CONN_BLUE "DSCO_CONN_BLUE";
BA_ "LongName" SG_ 707 DSCO_CONN_BLUE "Trennung_Verbindung_Bluetooth";
BA_ "SysSignalName" SG_ 707 DSCO_CONN_BLUE "DSCO_CONN_BLUE";
BA_ "CompuMethodName" SG_ 707 ASSIST_ECAL_AVLB "ASSIST_ECAL_AVLB";
BA_ "ISignalName" SG_ 707 ASSIST_ECAL_AVLB "ASSIST_ECAL_AVLB";
BA_ "LongName" SG_ 707 ASSIST_ECAL_AVLB "ASSIST_Notruf_Verfügbar";
BA_ "SysSignalName" SG_ 707 ASSIST_ECAL_AVLB "ASSIST_ECAL_AVLB";
BA_ "CompuMethodName" SG_ 707 STD_ECAL_AVLB "STD_ECAL_AVLB";
BA_ "ISignalName" SG_ 707 STD_ECAL_AVLB "STD_ECAL_AVLB";
BA_ "LongName" SG_ 707 STD_ECAL_AVLB "Standard_Notruf_Verfügbar";
BA_ "SysSignalName" SG_ 707 STD_ECAL_AVLB "STD_ECAL_AVLB";
BA_ "CompuMethodName" SG_ 707 ECAL_SBLE "ECAL_SBLE";
BA_ "ISignalName" SG_ 707 ECAL_SBLE "ECAL_SBLE";
BA_ "LongName" SG_ 707 ECAL_SBLE "Notruf_Auswählbar";
BA_ "SysSignalName" SG_ 707 ECAL_SBLE "ECAL_SBLE";
BA_ "CompuMethodName" SG_ 707 ECAL_ACV "ECAL_ACV";
BA_ "ISignalName" SG_ 707 ECAL_ACV "ECAL_ACV";
BA_ "LongName" SG_ 707 ECAL_ACV "Notruf_Aktiv";
BA_ "SysSignalName" SG_ 707 ECAL_ACV "ECAL_ACV";
BA_ "CompuMethodName" SG_ 707 ECAL_TR_SRC "ECAL_TR_SRC";
BA_ "ISignalName" SG_ 707 ECAL_TR_SRC "ECAL_TR_SRC";
BA_ "LongName" SG_ 707 ECAL_TR_SRC "Notruf_Trigger_Quelle";
BA_ "SysSignalName" SG_ 707 ECAL_TR_SRC "ECAL_TR_SRC";
BA_ "CompuMethodName" SG_ 707 ECAL_ST_DT "ECAL_ST_DT";
BA_ "ISignalName" SG_ 707 ECAL_ST_DT "ECAL_ST_DT";
BA_ "LongName" SG_ 707 ECAL_ST_DT "Notruf_Status_Daten";
BA_ "SysSignalName" SG_ 707 ECAL_ST_DT "ECAL_ST_DT";
BA_ "CompuMethodName" SG_ 707 ECAL_ST_CALL "ECAL_ST_CALL";
BA_ "ISignalName" SG_ 707 ECAL_ST_CALL "ECAL_ST_CALL";
BA_ "LongName" SG_ 707 ECAL_ST_CALL "Notruf_Status_Call";
BA_ "SysSignalName" SG_ 707 ECAL_ST_CALL "ECAL_ST_CALL";
BA_ "CompuMethodName" SG_ 707 ECAL_ABRT_PERM "ECAL_ABRT_PERM";
BA_ "ISignalName" SG_ 707 ECAL_ABRT_PERM "ECAL_ABRT_PERM";
BA_ "LongName" SG_ 707 ECAL_ABRT_PERM "Notruf_Abbruch_Erlaubnis";
BA_ "SysSignalName" SG_ 707 ECAL_ABRT_PERM "ECAL_ABRT_PERM";
BA_ "CompuMethodName" SG_ 707 ECAL_STDBY "ECAL_STDBY";
BA_ "ISignalName" SG_ 707 ECAL_STDBY "ECAL_STDBY";
BA_ "LongName" SG_ 707 ECAL_STDBY "Notruf_Standby";
BA_ "SysSignalName" SG_ 707 ECAL_STDBY "ECAL_STDBY";
BA_ "CompuMethodName" SG_ 707 ECAL_CNTDWN_TIM "ECAL_CNTDWN_TIM";
BA_ "ISignalName" SG_ 707 ECAL_CNTDWN_TIM "ECAL_CNTDWN_TIM";
BA_ "LongName" SG_ 707 ECAL_CNTDWN_TIM "Notruf_Countdown_Timer";
BA_ "SysSignalName" SG_ 707 ECAL_CNTDWN_TIM "ECAL_CNTDWN_TIM";
BA_ "CompuMethodName" SG_ 707 AVLB_ERA_GLO_TST_MOD "AVLB_ERA_GLO_TST_MOD";
BA_ "ISignalName" SG_ 707 AVLB_ERA_GLO_TST_MOD "AVLB_ERA_GLO_TST_MOD";
BA_ "LongName" SG_ 707 AVLB_ERA_GLO_TST_MOD "Verfügbar_ERA_GLONASS_Test_Modus";
BA_ "SysSignalName" SG_ 707 AVLB_ERA_GLO_TST_MOD "AVLB_ERA_GLO_TST_MOD";
BA_ "CompuMethodName" SG_ 707 ERA_GLO_TST_MOD_ST "ERA_GLO_TST_MOD_ST";
BA_ "ISignalName" SG_ 707 ERA_GLO_TST_MOD_ST "ERA_GLO_TST_MOD_ST";
BA_ "LongName" SG_ 707 ERA_GLO_TST_MOD_ST "ERA_GLONASS_Test_Modus_Status";
BA_ "SysSignalName" SG_ 707 ERA_GLO_TST_MOD_ST "ERA_GLO_TST_MOD_ST";
BA_ "CompuMethodName" SG_ 710 CRC_ST_ELV "CRC8";
BA_ "ISignalName" SG_ 710 CRC_ST_ELV "CRC_ST_ELV";
BA_ "LongName" SG_ 710 CRC_ST_ELV "CRC_Status_ELV";
BA_ "SysSignalName" SG_ 710 CRC_ST_ELV "CRC_ST_ELV";
BA_ "CompuMethodName" SG_ 710 ALIV_ST_ELV "ALIV_4_BIT_Unsigned_Integer";
BA_ "ISignalName" SG_ 710 ALIV_ST_ELV "ALIV_ST_ELV";
BA_ "LongName" SG_ 710 ALIV_ST_ELV "Alive_Status_ELV";
BA_ "SysSignalName" SG_ 710 ALIV_ST_ELV "ALIV_ST_ELV";
BA_ "CompuMethodName" SG_ 710 CHL_ST_ELV "CHL_4_UInt";
BA_ "ISignalName" SG_ 710 CHL_ST_ELV "CHL_ST_ELV";
BA_ "LongName" SG_ 710 CHL_ST_ELV "CHL_Status_ELV";
BA_ "SysSignalName" SG_ 710 CHL_ST_ELV "CHL_ST_ELV";
BA_ "ISignalName" SG_ 710 ST_ELV_dummy_16_19 "ST_ELV_dummy_16_19";
BA_ "LongName" SG_ 710 ST_ELV_dummy_16_19 "ST_ELV_dummy_16_19";
BA_ "SysSignalName" SG_ 710 ST_ELV_dummy_16_19 "ST_ELV_dummy_16_19";
BA_ "CompuMethodName" SG_ 710 ST_CON_ELV "ST_CON_ELV";
BA_ "ISignalName" SG_ 710 ST_CON_ELV "ST_CON_ELV";
BA_ "LongName" SG_ 710 ST_CON_ELV "Status_Zustand_ELV";
BA_ "SysSignalName" SG_ 710 ST_CON_ELV "ST_CON_ELV";
BA_ "ISignalName" SG_ 710 ST_ELV_dummy_24_31 "ST_ELV_dummy_24_31";
BA_ "LongName" SG_ 710 ST_ELV_dummy_24_31 "ST_ELV_dummy_24_31";
BA_ "SysSignalName" SG_ 710 ST_ELV_dummy_24_31 "ST_ELV_dummy_24_31";
BA_ "ISignalName" SG_ 710 ST_ELV_dummy_32_63 "ST_ELV_dummy_32_63";
BA_ "LongName" SG_ 710 ST_ELV_dummy_32_63 "ST_ELV_dummy_32_63";
BA_ "SysSignalName" SG_ 710 ST_ELV_dummy_32_63 "ST_ELV_dummy_32_63";
BA_ "CompuMethodName" SG_ 442 ST_LDREL_GEN "ST_LDREL_GEN";
BA_ "ISignalName" SG_ 442 ST_LDREL_GEN "ST_LDREL_GEN";
BA_ "LongName" SG_ 442 ST_LDREL_GEN "Status_Entlastung_Generator";
BA_ "SysSignalName" SG_ 442 ST_LDREL_GEN "ST_LDREL_GEN";
BA_ "CompuMethodName" SG_ 912 ST_HOSP_FN "CTR_HOSP_FN";
BA_ "ISignalName" SG_ 912 ST_HOSP_FN "ST_HOSP_FN";
BA_ "LongName" SG_ 912 ST_HOSP_FN "Status_Hospitality_Funktion";
BA_ "SysSignalName" SG_ 912 ST_HOSP_FN "ST_HOSP_FN";
BA_ "CompuMethodName" SG_ 367 ST_GO_ID "ST_GO_ID";
BA_ "ISignalName" SG_ 367 ST_GO_ID "ST_GO_ID";
BA_ "LongName" SG_ 367 ST_GO_ID "Status_Gong_ID";
BA_ "SysSignalName" SG_ 367 ST_GO_ID "ST_GO_ID";
BA_ "CompuMethodName" SG_ 367 ST_GO_HND "ST_GO_ID";
BA_ "ISignalName" SG_ 367 ST_GO_HND "ST_GO_HND";
BA_ "LongName" SG_ 367 ST_GO_HND "Status_Gong_Handle";
BA_ "SysSignalName" SG_ 367 ST_GO_HND "ST_GO_HND";
BA_ "CompuMethodName" SG_ 367 ST_GO "ST_GO";
BA_ "ISignalName" SG_ 367 ST_GO "ST_GO";
BA_ "LongName" SG_ 367 ST_GO "Status_Gong";
BA_ "SysSignalName" SG_ 367 ST_GO "ST_GO";
BA_ "CompuMethodName" SG_ 407 CRC_ST_GWS "CRC8";
BA_ "ISignalName" SG_ 407 CRC_ST_GWS "CRC_ST_GWS";
BA_ "LongName" SG_ 407 CRC_ST_GWS "CRC_Status_Gangwahlschalter";
BA_ "SysSignalName" SG_ 407 CRC_ST_GWS "CRC_ST_GWS";
BA_ "CompuMethodName" SG_ 407 ALIV_ST_GWS "Aliv_4";
BA_ "ISignalName" SG_ 407 ALIV_ST_GWS "ALIV_ST_GWS";
BA_ "LongName" SG_ 407 ALIV_ST_GWS "Alive_Status_Gangwahlschalter";
BA_ "SysSignalName" SG_ 407 ALIV_ST_GWS "ALIV_ST_GWS";
BA_ "CompuMethodName" SG_ 407 OP_GWS "OP_GWS";
BA_ "ISignalName" SG_ 407 OP_GWS "OP_GWS";
BA_ "LongName" SG_ 407 OP_GWS "Bedienung_Gangwahlschalter";
BA_ "SysSignalName" SG_ 407 OP_GWS "OP_GWS";
BA_ "CompuMethodName" SG_ 407 OP_GWS_PUBU_S "OP_GWS_PUBU_S";
BA_ "ISignalName" SG_ 407 OP_GWS_PUBU_S "OP_GWS_PUBU_S";
BA_ "LongName" SG_ 407 OP_GWS_PUBU_S "Bedienung_Gangwahlschalter_Taster_Sport";
BA_ "SysSignalName" SG_ 407 OP_GWS_PUBU_S "OP_GWS_PUBU_S";
BA_ "CompuMethodName" SG_ 407 OP_GWS_PUBU_DRVLG "OP_PUBU_DRVLG";
BA_ "ISignalName" SG_ 407 OP_GWS_PUBU_DRVLG "OP_GWS_PUBU_DRVLG";
BA_ "LongName" SG_ 407 OP_GWS_PUBU_DRVLG "Bedienung_Gangwahlschalter_Taster_Drive-Logic";
BA_ "SysSignalName" SG_ 407 OP_GWS_PUBU_DRVLG "OP_GWS_PUBU_DRVLG";
BA_ "CompuMethodName" SG_ 407 OP_GWS_REL "OP_GWS_REL";
BA_ "ISignalName" SG_ 407 OP_GWS_REL "OP_GWS_REL";
BA_ "LongName" SG_ 407 OP_GWS_REL "Bedienung_Gangwahlschalter_Relativ";
BA_ "SysSignalName" SG_ 407 OP_GWS_REL "OP_GWS_REL";
BA_ "CompuMethodName" SG_ 407 OP_GWS_PUBU_PKG "PUBU_PKG";
BA_ "ISignalName" SG_ 407 OP_GWS_PUBU_PKG "OP_GWS_PUBU_PKG";
BA_ "LongName" SG_ 407 OP_GWS_PUBU_PKG "Bedienung_Gangwahlschalter_Taster_Parken";
BA_ "SysSignalName" SG_ 407 OP_GWS_PUBU_PKG "OP_GWS_PUBU_PKG";
BA_ "CompuMethodName" SG_ 407 OP_GRSS_PK_1_2 "OP_GRSS_1";
BA_ "ISignalName" SG_ 407 OP_GRSS_PK_1_2 "OP_GRSS_PK_1_2";
BA_ "LongName" SG_ 407 OP_GRSS_PK_1_2 "Bedienung_Getriebewahltaster_P_1_2";
BA_ "SysSignalName" SG_ 407 OP_GRSS_PK_1_2 "OP_GRSS_PK_1_2";
BA_ "CompuMethodName" SG_ 407 OP_GRSS_PK_2_2 "OP_GRSS_2";
BA_ "ISignalName" SG_ 407 OP_GRSS_PK_2_2 "OP_GRSS_PK_2_2";
BA_ "LongName" SG_ 407 OP_GRSS_PK_2_2 "Bedienung_Getriebewahltaster_P_2_2";
BA_ "SysSignalName" SG_ 407 OP_GRSS_PK_2_2 "OP_GRSS_PK_2_2";
BA_ "CompuMethodName" SG_ 407 OP_GWS_PUBU_LOW_MOD "OP_GWS_PUBU_LOW_MOD";
BA_ "ISignalName" SG_ 407 OP_GWS_PUBU_LOW_MOD "OP_GWS_PUBU_LOW_MOD";
BA_ "LongName" SG_ 407 OP_GWS_PUBU_LOW_MOD "Bedienung_Gangwahlschalter_Taster_Low_Modus";
BA_ "SysSignalName" SG_ 407 OP_GWS_PUBU_LOW_MOD "OP_GWS_PUBU_LOW_MOD";
BA_ "CompuMethodName" SG_ 446 ALIV_ST_GZA_LH "Alive_4_Bit_SigEncod";
BA_ "ISignalName" SG_ 446 ALIV_ST_GZA_LH "ALIV_ST_GZA_LH";
BA_ "LongName" SG_ 446 ALIV_ST_GZA_LH "Alive_Status_GZA_Links";
BA_ "SysSignalName" SG_ 446 ALIV_ST_GZA_LH "ALIV_ST_GZA_LH";
BA_ "CompuMethodName" SG_ 446 ST_GZA_LH "ST_GZA";
BA_ "ISignalName" SG_ 446 ST_GZA_LH "ST_GZA_LH";
BA_ "LongName" SG_ 446 ST_GZA_LH "Status_GZA_Links";
BA_ "SysSignalName" SG_ 446 ST_GZA_LH "ST_GZA_LH";
BA_ "CompuMethodName" SG_ 471 ALIV_ST_GZA_RH "Alive_4_Bit_SigEncod";
BA_ "ISignalName" SG_ 471 ALIV_ST_GZA_RH "ALIV_ST_GZA_RH";
BA_ "LongName" SG_ 471 ALIV_ST_GZA_RH "Alive_Status_GZA_Rechts";
BA_ "SysSignalName" SG_ 471 ALIV_ST_GZA_RH "ALIV_ST_GZA_RH";
BA_ "CompuMethodName" SG_ 471 ST_GZA_RH "ST_GZA";
BA_ "ISignalName" SG_ 471 ST_GZA_RH "ST_GZA_RH";
BA_ "LongName" SG_ 471 ST_GZA_RH "Status_GZA_Rechts";
BA_ "SysSignalName" SG_ 471 ST_GZA_RH "ST_GZA_RH";
BA_ "CompuMethodName" SG_ 942 ST_BAL_HUD_3 "ST_BAL_HUD_3";
BA_ "ISignalName" SG_ 942 ST_BAL_HUD_3 "ST_BAL_HUD_3";
BA_ "LongName" SG_ 942 ST_BAL_HUD_3 "Status_Hinterleuchtung_HUD_3";
BA_ "SysSignalName" SG_ 942 ST_BAL_HUD_3 "ST_BAL_HUD_3";
BA_ "CompuMethodName" SG_ 942 ST_BRIG_OFFS_HUD_3 "ST_BRIG_OFFS_HUD_3";
BA_ "ISignalName" SG_ 942 ST_BRIG_OFFS_HUD_3 "ST_BRIG_OFFS_HUD_3";
BA_ "LongName" SG_ 942 ST_BRIG_OFFS_HUD_3 "Status_Helligkeit_Offset_HUD_3";
BA_ "SysSignalName" SG_ 942 ST_BRIG_OFFS_HUD_3 "ST_BRIG_OFFS_HUD_3";
BA_ "CompuMethodName" SG_ 942 ST_HGAD_HUD_3 "HGAD_HUD_3";
BA_ "ISignalName" SG_ 942 ST_HGAD_HUD_3 "ST_HGAD_HUD_3";
BA_ "LongName" SG_ 942 ST_HGAD_HUD_3 "Status_Höhenverstellung_HUD_3";
BA_ "SysSignalName" SG_ 942 ST_HGAD_HUD_3 "ST_HGAD_HUD_3";
BA_ "CompuMethodName" SG_ 942 ST_SLCTN_RDOBUT_HUD "OP_SLCTN_RDOBUT_HUD";
BA_ "ISignalName" SG_ 942 ST_SLCTN_RDOBUT_HUD "ST_SLCTN_RDOBUT_HUD";
BA_ "LongName" SG_ 942 ST_SLCTN_RDOBUT_HUD "Status_Auswahl_Radiotaste_HUD";
BA_ "SysSignalName" SG_ 942 ST_SLCTN_RDOBUT_HUD "ST_SLCTN_RDOBUT_HUD";
BA_ "CompuMethodName" SG_ 942 ST_ROTA_HUD "ST_ROTA_HUD";
BA_ "ISignalName" SG_ 942 ST_ROTA_HUD "ST_ROTA_HUD";
BA_ "LongName" SG_ 942 ST_ROTA_HUD "Status_Rotationsverstellung_HUD";
BA_ "SysSignalName" SG_ 942 ST_ROTA_HUD "ST_ROTA_HUD";
BA_ "CompuMethodName" SG_ 942 ST_STAN_HUD "STAN_HUD";
BA_ "ISignalName" SG_ 942 ST_STAN_HUD "ST_STAN_HUD";
BA_ "LongName" SG_ 942 ST_STAN_HUD "Status_Standanzeige_HUD";
BA_ "SysSignalName" SG_ 942 ST_STAN_HUD "ST_STAN_HUD";
BA_ "CompuMethodName" SG_ 942 ST_SLCTN_DISP_HUD_3 "OP_SLCTN_DISP_HUD_3";
BA_ "ISignalName" SG_ 942 ST_SLCTN_DISP_HUD_3 "ST_SLCTN_DISP_HUD_3";
BA_ "LongName" SG_ 942 ST_SLCTN_DISP_HUD_3 "Status_Auswahl_Anzeige_HUD_3";
BA_ "SysSignalName" SG_ 942 ST_SLCTN_DISP_HUD_3 "ST_SLCTN_DISP_HUD_3";
BA_ "CompuMethodName" SG_ 942 ST_S_DISP_HUD "OP_S_DISP_HUD";
BA_ "ISignalName" SG_ 942 ST_S_DISP_HUD "ST_S_DISP_HUD";
BA_ "LongName" SG_ 942 ST_S_DISP_HUD "Status_Sport_Anzeige_HUD";
BA_ "SysSignalName" SG_ 942 ST_S_DISP_HUD "ST_S_DISP_HUD";
BA_ "CompuMethodName" SG_ 942 StatusAdditionalDisplayHUD "AdditionalDisplayHUD";
BA_ "ISignalName" SG_ 942 StatusAdditionalDisplayHUD "StatusAdditionalDisplayHUD";
BA_ "LongName" SG_ 942 StatusAdditionalDisplayHUD "StatusAdditionalDisplayHUD";
BA_ "SysSignalName" SG_ 942 StatusAdditionalDisplayHUD "StatusAdditionalDisplayHUD";
BA_ "CompuMethodName" SG_ 832 ST_HVBT_PROTE_WU "ST_HVBT_PROTE_WU";
BA_ "ISignalName" SG_ 832 ST_HVBT_PROTE_WU "ST_HVBT_PROTE_WU";
BA_ "LongName" SG_ 832 ST_HVBT_PROTE_WU "Status_Hochvoltbatterie_Schutz_WakeUp";
BA_ "SysSignalName" SG_ 832 ST_HVBT_PROTE_WU "ST_HVBT_PROTE_WU";
BA_ "CompuMethodName" SG_ 832 StatusHVBatteryPassengerSafety "StatusHVBatteryPassengerSafety";
BA_ "ISignalName" SG_ 832 StatusHVBatteryPassengerSafety "StatusHVBatteryPassengerSafety";
BA_ "LongName" SG_ 832 StatusHVBatteryPassengerSafety "StatusHVBatteryPassengerSafety";
BA_ "SysSignalName" SG_ 832 StatusHVBatteryPassengerSafety "StatusHVBatteryPassengerSafety";
BA_ "CompuMethodName" SG_ 506 RQ_COOL_HVSTO "RQ_COOL_HVSTO";
BA_ "ISignalName" SG_ 506 RQ_COOL_HVSTO "RQ_COOL_HVSTO";
BA_ "LongName" SG_ 506 RQ_COOL_HVSTO "Anforderung_Kühlung_Hochvoltspeicher";
BA_ "SysSignalName" SG_ 506 RQ_COOL_HVSTO "RQ_COOL_HVSTO";
BA_ "CompuMethodName" SG_ 506 ST_VA_COOL_HVSTO "ST_VA_COOL_HVSTO";
BA_ "ISignalName" SG_ 506 ST_VA_COOL_HVSTO "ST_VA_COOL_HVSTO";
BA_ "LongName" SG_ 506 ST_VA_COOL_HVSTO "Status_Ventil_Kühlung_Hochvoltspeicher";
BA_ "SysSignalName" SG_ 506 ST_VA_COOL_HVSTO "ST_VA_COOL_HVSTO";
BA_ "CompuMethodName" SG_ 506 ST_ERR_LOKG_HVSTO "ST_ERR_LOKG_HVSTO";
BA_ "ISignalName" SG_ 506 ST_ERR_LOKG_HVSTO "ST_ERR_LOKG_HVSTO";
BA_ "LongName" SG_ 506 ST_ERR_LOKG_HVSTO "Status_Fehler_Verriegelung_Hochvoltspeicher";
BA_ "SysSignalName" SG_ 506 ST_ERR_LOKG_HVSTO "ST_ERR_LOKG_HVSTO";
BA_ "CompuMethodName" SG_ 506 ST_DCSW_HVSTO "ST_DCSW_HVSTO";
BA_ "ISignalName" SG_ 506 ST_DCSW_HVSTO "ST_DCSW_HVSTO";
BA_ "LongName" SG_ 506 ST_DCSW_HVSTO "Status_Trennschalter_Hochvoltspeicher";
BA_ "SysSignalName" SG_ 506 ST_DCSW_HVSTO "ST_DCSW_HVSTO";
BA_ "CompuMethodName" SG_ 506 ST_EMMOD_HVSTO "ST_Universal2_2Bit";
BA_ "ISignalName" SG_ 506 ST_EMMOD_HVSTO "ST_EMMOD_HVSTO";
BA_ "LongName" SG_ 506 ST_EMMOD_HVSTO "Status_Notlauf_Hochvoltspeicher";
BA_ "SysSignalName" SG_ 506 ST_EMMOD_HVSTO "ST_EMMOD_HVSTO";
BA_ "CompuMethodName" SG_ 506 ST_WARN_ISL_BN_HV "ST_WARN_ISL_BN_HV";
BA_ "ISignalName" SG_ 506 ST_WARN_ISL_BN_HV "ST_WARN_ISL_BN_HV";
BA_ "LongName" SG_ 506 ST_WARN_ISL_BN_HV "Status_Warnung_Isolation_Bordnetz_Hochspannung";
BA_ "SysSignalName" SG_ 506 ST_WARN_ISL_BN_HV "ST_WARN_ISL_BN_HV";
BA_ "CompuMethodName" SG_ 506 ST_CSOV_HVSTO "ST_CSOV_HVSTO";
BA_ "ISignalName" SG_ 506 ST_CSOV_HVSTO "ST_CSOV_HVSTO";
BA_ "LongName" SG_ 506 ST_CSOV_HVSTO "Status_Kälteabsperrventil_Hochvoltspeicher";
BA_ "SysSignalName" SG_ 506 ST_CSOV_HVSTO "ST_CSOV_HVSTO";
BA_ "CompuMethodName" SG_ 506 AVL_TEMP_HVSTO "TEMP_HVSTO";
BA_ "GenSigStartValue" SG_ 506 AVL_TEMP_HVSTO 50;
BA_ "ISignalName" SG_ 506 AVL_TEMP_HVSTO "AVL_TEMP_HVSTO";
BA_ "LongName" SG_ 506 AVL_TEMP_HVSTO "Ist_Temperatur_Hochvoltspeicher";
BA_ "SysSignalName" SG_ 506 AVL_TEMP_HVSTO "AVL_TEMP_HVSTO";
BA_ "CompuMethodName" SG_ 506 AVL_TEMP_HTEX_HVSTO "TEMP_HVSTO";
BA_ "GenSigStartValue" SG_ 506 AVL_TEMP_HTEX_HVSTO 50;
BA_ "ISignalName" SG_ 506 AVL_TEMP_HTEX_HVSTO "AVL_TEMP_HTEX_HVSTO";
BA_ "LongName" SG_ 506 AVL_TEMP_HTEX_HVSTO "Ist_Temperatur_Wärmetauscher_Hochvoltspeicher";
BA_ "SysSignalName" SG_ 506 AVL_TEMP_HTEX_HVSTO "AVL_TEMP_HTEX_HVSTO";
BA_ "CompuMethodName" SG_ 506 AVL_TEMP_HVSTO_MIN "AVL_TEMP_HVSTO";
BA_ "GenSigStartValue" SG_ 506 AVL_TEMP_HVSTO_MIN 50;
BA_ "ISignalName" SG_ 506 AVL_TEMP_HVSTO_MIN "AVL_TEMP_HVSTO_MIN";
BA_ "LongName" SG_ 506 AVL_TEMP_HVSTO_MIN "Ist_Temperatur_Hochvoltspeicher_Minimal";
BA_ "SysSignalName" SG_ 506 AVL_TEMP_HVSTO_MIN "AVL_TEMP_HVSTO_MIN";
BA_ "CompuMethodName" SG_ 506 AVL_TEMP_HVSTO_MAX "AVL_TEMP_HVSTO";
BA_ "GenSigStartValue" SG_ 506 AVL_TEMP_HVSTO_MAX 50;
BA_ "ISignalName" SG_ 506 AVL_TEMP_HVSTO_MAX "AVL_TEMP_HVSTO_MAX";
BA_ "LongName" SG_ 506 AVL_TEMP_HVSTO_MAX "actual-value_temperature_high-voltage-storage_maximum";
BA_ "SysSignalName" SG_ 506 AVL_TEMP_HVSTO_MAX "AVL_TEMP_HVSTO_MAX";
BA_ "CompuMethodName" SG_ 613 CHGCOND_HVSTO_SOC "CHGCOND_HVSTO_SOC";
BA_ "ISignalName" SG_ 613 CHGCOND_HVSTO_SOC "CHGCOND_HVSTO_SOC";
BA_ "LongName" SG_ 613 CHGCOND_HVSTO_SOC "Ladezustand_Hochvoltspeicher_SOC";
BA_ "SysSignalName" SG_ 613 CHGCOND_HVSTO_SOC "CHGCOND_HVSTO_SOC";
BA_ "CompuMethodName" SG_ 613 EnergyPredictionDepartureTime "EnergyPrediction";
BA_ "GenSigStartValue" SG_ 613 EnergyPredictionDepartureTime -50;
BA_ "ISignalName" SG_ 613 EnergyPredictionDepartureTime "EnergyPredictionDepartureTime";
BA_ "LongName" SG_ 613 EnergyPredictionDepartureTime "EnergyPredictionDepartureTime";
BA_ "SysSignalName" SG_ 613 EnergyPredictionDepartureTime "EnergyPredictionDepartureTime";
BA_ "CompuMethodName" SG_ 613 EnergyPredictionSoeChargingTarge "EnergyPrediction";
BA_ "GenSigStartValue" SG_ 613 EnergyPredictionSoeChargingTarge -50;
BA_ "ISignalName" SG_ 613 EnergyPredictionSoeChargingTarge "EnergyPredictionSoeChargingTarget";
BA_ "LongName" SG_ 613 EnergyPredictionSoeChargingTarge "EnergyPredictionSoeChargingTarget";
BA_ "SysSignalName" SG_ 613 EnergyPredictionSoeChargingTarge "EnergyPredictionSoeChargingTarget";
BA_ "SystemSignalLongSymbol" SG_ 613 EnergyPredictionSoeChargingTarge "EnergyPredictionSoeChargingTarget";
BA_ "CompuMethodName" SG_ 795 DISP_ST_DSC_2 "DISP_ST_DSC_2";
BA_ "ISignalName" SG_ 795 DISP_ST_DSC_2 "DISP_ST_DSC_2";
BA_ "LongName" SG_ 795 DISP_ST_DSC_2 "Anzeige_Status_DSC_2";
BA_ "SysSignalName" SG_ 795 DISP_ST_DSC_2 "DISP_ST_DSC_2";
BA_ "CompuMethodName" SG_ 444 DISP_ST_DSC_2 "DISP_ST_DSC_2";
BA_ "ISignalName" SG_ 444 DISP_ST_DSC_2 "DISP_ST_DSC_2";
BA_ "LongName" SG_ 444 DISP_ST_DSC_2 "Anzeige_Status_DSC_2";
BA_ "SysSignalName" SG_ 444 DISP_ST_DSC_2 "DISP_ST_DSC_2";
BA_ "CompuMethodName" SG_ 881 ST_ECO_VL_THO_ECS_DXP "ECO_VL_THO_ECS_DXP";
BA_ "ISignalName" SG_ 881 ST_ECO_VL_THO_ECS_DXP "ST_ECO_VL_THO_ECS_DXP";
BA_ "LongName" SG_ 881 ST_ECO_VL_THO_ECS_DXP "Status_ECO_Wert_Schwelle_ECOGeschwindigkeit_Fahrerlebnis";
BA_ "SysSignalName" SG_ 881 ST_ECO_VL_THO_ECS_DXP "ST_ECO_VL_THO_ECS_DXP";
BA_ "CompuMethodName" SG_ 881 ST_ECO_FN_ECS_DXP "ECO_FN_ECS_DXP";
BA_ "ISignalName" SG_ 881 ST_ECO_FN_ECS_DXP "ST_ECO_FN_ECS_DXP";
BA_ "LongName" SG_ 881 ST_ECO_FN_ECS_DXP "Status_ECO_Funktion_ECOGeschwindigkeit_Fahrerlebnis";
BA_ "SysSignalName" SG_ 881 ST_ECO_FN_ECS_DXP "ST_ECO_FN_ECS_DXP";
BA_ "CompuMethodName" SG_ 881 ST_ECO_FN_FRSG_ASST_DXP "ECO_FN_FRSG_ASST_DXP";
BA_ "ISignalName" SG_ 881 ST_ECO_FN_FRSG_ASST_DXP "ST_ECO_FN_FRSG_ASST_DXP";
BA_ "LongName" SG_ 881 ST_ECO_FN_FRSG_ASST_DXP "Status_ECO_Funktion_Vorausschau_Assistent_Fahrerlebnis";
BA_ "SysSignalName" SG_ 881 ST_ECO_FN_FRSG_ASST_DXP "ST_ECO_FN_FRSG_ASST_DXP";
BA_ "CompuMethodName" SG_ 881 ST_ECO_FN_ECT_DXP "ECO_FN_ECT_DXP";
BA_ "ISignalName" SG_ 881 ST_ECO_FN_ECT_DXP "ST_ECO_FN_ECT_DXP";
BA_ "LongName" SG_ 881 ST_ECO_FN_ECT_DXP "Status_ECO_Funktion_ECOTipps_Fahrerlebnis";
BA_ "SysSignalName" SG_ 881 ST_ECO_FN_ECT_DXP "ST_ECO_FN_ECT_DXP";
BA_ "CompuMethodName" SG_ 881 ST_ECO_VL_UN_THO_ECS_DXP "ST_ECO_VL_UN_THO_ECS_DXP";
BA_ "ISignalName" SG_ 881 ST_ECO_VL_UN_THO_ECS_DXP "ST_ECO_VL_UN_THO_ECS_DXP";
BA_ "LongName" SG_ 881 ST_ECO_VL_UN_THO_ECS_DXP "Status_ECO_Wert_Einheit_Schwelle_ECOGeschwindigkeit_Fahrerlebnis";
BA_ "SysSignalName" SG_ 881 ST_ECO_VL_UN_THO_ECS_DXP "ST_ECO_VL_UN_THO_ECS_DXP";
BA_ "CompuMethodName" SG_ 881 ST_ECO_VL_MIN_THO_ECS_DXP "ECO_VL_THO_ECS_DXP";
BA_ "ISignalName" SG_ 881 ST_ECO_VL_MIN_THO_ECS_DXP "ST_ECO_VL_MIN_THO_ECS_DXP";
BA_ "LongName" SG_ 881 ST_ECO_VL_MIN_THO_ECS_DXP "Status_ECO_Wert_Minimal_Schwelle_ECOGeschwindigkeit_Fahrerlebnis";
BA_ "SysSignalName" SG_ 881 ST_ECO_VL_MIN_THO_ECS_DXP "ST_ECO_VL_MIN_THO_ECS_DXP";
BA_ "CompuMethodName" SG_ 881 ST_ECO_VL_MAX_THO_ECS_DXP "ECO_VL_THO_ECS_DXP";
BA_ "ISignalName" SG_ 881 ST_ECO_VL_MAX_THO_ECS_DXP "ST_ECO_VL_MAX_THO_ECS_DXP";
BA_ "LongName" SG_ 881 ST_ECO_VL_MAX_THO_ECS_DXP "Status_ECO_Wert_Maximal_Schwelle_ECOGeschwindigkeit_Fahrerlebnis";
BA_ "SysSignalName" SG_ 881 ST_ECO_VL_MAX_THO_ECS_DXP "ST_ECO_VL_MAX_THO_ECS_DXP";
BA_ "CompuMethodName" SG_ 881 AVAI_ECO_FN_FRSG_ASST_DXP "AVAI_ECO_FN_FRSG_ASST_DXP";
BA_ "ISignalName" SG_ 881 AVAI_ECO_FN_FRSG_ASST_DXP "AVAI_ECO_FN_FRSG_ASST_DXP";
BA_ "LongName" SG_ 881 AVAI_ECO_FN_FRSG_ASST_DXP "Verfügbarkeit_ECO_Funktion_Vorausschau_Assistent_Fahrerlebnis";
BA_ "SysSignalName" SG_ 881 AVAI_ECO_FN_FRSG_ASST_DXP "AVAI_ECO_FN_FRSG_ASST_DXP";
BA_ "CompuMethodName" SG_ 875 ST_ECO_FN_SAIL_DXP "ECO_FN_SAIL_DXP";
BA_ "ISignalName" SG_ 875 ST_ECO_FN_SAIL_DXP "ST_ECO_FN_SAIL_DXP";
BA_ "LongName" SG_ 875 ST_ECO_FN_SAIL_DXP "Status_ECO_Funktion_Segeln_Fahrerlebnis";
BA_ "SysSignalName" SG_ 875 ST_ECO_FN_SAIL_DXP "ST_ECO_FN_SAIL_DXP";
BA_ "CompuMethodName" SG_ 875 ST_ECO_FN_MSA_DXP "ECO_FN_MSA_DXP";
BA_ "ISignalName" SG_ 875 ST_ECO_FN_MSA_DXP "ST_ECO_FN_MSA_DXP";
BA_ "LongName" SG_ 875 ST_ECO_FN_MSA_DXP "Status_ECO_Funktion_MSA_Fahrerlebnis";
BA_ "SysSignalName" SG_ 875 ST_ECO_FN_MSA_DXP "ST_ECO_FN_MSA_DXP";
BA_ "CompuMethodName" SG_ 875 ST_S_FN_SHA_DXP "S_FN_SHA_DXP";
BA_ "ISignalName" SG_ 875 ST_S_FN_SHA_DXP "ST_S_FN_SHA_DXP";
BA_ "LongName" SG_ 875 ST_S_FN_SHA_DXP "Status_Sport_Funktion_Schaltassistent_Fahrerlebnis";
BA_ "SysSignalName" SG_ 875 ST_S_FN_SHA_DXP "ST_S_FN_SHA_DXP";
BA_ "CompuMethodName" SG_ 875 ST_S_CLU_RPM_PA_DXP "S_CLU_DXP";
BA_ "ISignalName" SG_ 875 ST_S_CLU_RPM_PA_DXP "ST_S_CLU_RPM_PA_DXP";
BA_ "LongName" SG_ 875 ST_S_CLU_RPM_PA_DXP "Status_Sport_Cluster_Drehzahl_Pfad_Fahrerlebnis";
BA_ "SysSignalName" SG_ 875 ST_S_CLU_RPM_PA_DXP "ST_S_CLU_RPM_PA_DXP";
BA_ "CompuMethodName" SG_ 875 ST_S_CLUG_ENG_DXP "S_CLU_DXP";
BA_ "ISignalName" SG_ 875 ST_S_CLUG_ENG_DXP "ST_S_CLUG_ENG_DXP";
BA_ "LongName" SG_ 875 ST_S_CLUG_ENG_DXP "Status_Sport_Clustergruppe_Motor_Fahrerlebnis";
BA_ "SysSignalName" SG_ 875 ST_S_CLUG_ENG_DXP "ST_S_CLUG_ENG_DXP";
BA_ "CompuMethodName" SG_ 875 ST_ADJU_SAIL_VEH "ADJU_SAIL_VEH";
BA_ "ISignalName" SG_ 875 ST_ADJU_SAIL_VEH "ST_ADJU_SAIL_VEH";
BA_ "LongName" SG_ 875 ST_ADJU_SAIL_VEH "Status_Einstellung_Segeln_Fahrzeug";
BA_ "SysSignalName" SG_ 875 ST_ADJU_SAIL_VEH "ST_ADJU_SAIL_VEH";
BA_ "CompuMethodName" SG_ 875 StatusAdjustEngineSoundVehicle "AdjustEngineSoundVehicle";
BA_ "ISignalName" SG_ 875 StatusAdjustEngineSoundVehicle "StatusAdjustEngineSoundVehicle";
BA_ "LongName" SG_ 875 StatusAdjustEngineSoundVehicle "StatusAdjustEngineSoundVehicle";
BA_ "SysSignalName" SG_ 875 StatusAdjustEngineSoundVehicle "StatusAdjustEngineSoundVehicle";
BA_ "CompuMethodName" SG_ 572 ST_SWO_IDT_CHGNG_CA "ST_SWO_IDT_CHGNG_CA";
BA_ "ISignalName" SG_ 572 ST_SWO_IDT_CHGNG_CA "ST_SWO_IDT_CHGNG_CA";
BA_ "LongName" SG_ 572 ST_SWO_IDT_CHGNG_CA "Status_Abschaltung_Induktiv_Laden_Comfort-Access";
BA_ "SysSignalName" SG_ 572 ST_SWO_IDT_CHGNG_CA "ST_SWO_IDT_CHGNG_CA";
BA_ "CompuMethodName" SG_ 572 ST_POSI_IDT_CHGNG_CA "ST_POSI_IDT_CHGNG_CA";
BA_ "ISignalName" SG_ 572 ST_POSI_IDT_CHGNG_CA "ST_POSI_IDT_CHGNG_CA";
BA_ "LongName" SG_ 572 ST_POSI_IDT_CHGNG_CA "Status_Positionierung_Induktiv_Laden_Comfort-Access";
BA_ "SysSignalName" SG_ 572 ST_POSI_IDT_CHGNG_CA "ST_POSI_IDT_CHGNG_CA";
BA_ "CompuMethodName" SG_ 656 ST_KEY_SRCH_INO "ST_KEY_SRCH_INO";
BA_ "ISignalName" SG_ 656 ST_KEY_SRCH_INO "ST_KEY_SRCH_INO";
BA_ "LongName" SG_ 656 ST_KEY_SRCH_INO "Status_Schlüssel_Suche_Innenraum";
BA_ "SysSignalName" SG_ 656 ST_KEY_SRCH_INO "ST_KEY_SRCH_INO";
BA_ "CompuMethodName" SG_ 656 ID_FN_RSLT_KEY_SRCH "ID_FN_RSLT_KEY_SRCH";
BA_ "ISignalName" SG_ 656 ID_FN_RSLT_KEY_SRCH "ID_FN_RSLT_KEY_SRCH";
BA_ "LongName" SG_ 656 ID_FN_RSLT_KEY_SRCH "ID_Funktion_Ergebnis_Schlüssel_Suche";
BA_ "SysSignalName" SG_ 656 ID_FN_RSLT_KEY_SRCH "ID_FN_RSLT_KEY_SRCH";
BA_ "CompuMethodName" SG_ 874 DISP_MAB_ASST "DISP_MAB_ASST";
BA_ "ISignalName" SG_ 874 DISP_MAB_ASST "DISP_MAB_ASST";
BA_ "LongName" SG_ 874 DISP_MAB_ASST "Anzeige_Fernlicht_Assistent";
BA_ "SysSignalName" SG_ 874 DISP_MAB_ASST "DISP_MAB_ASST";
BA_ "CompuMethodName" SG_ 874 RQ_OP_MAB_ASST "RQ_OP_Fernlicht_Assistent";
BA_ "ISignalName" SG_ 874 RQ_OP_MAB_ASST "RQ_OP_MAB_ASST";
BA_ "LongName" SG_ 874 RQ_OP_MAB_ASST "Anforderung_Bedienung_Fernlicht_Assistent";
BA_ "SysSignalName" SG_ 874 RQ_OP_MAB_ASST "RQ_OP_MAB_ASST";
BA_ "CompuMethodName" SG_ 1070 ALIV_ST_MDRV_2 "ALIV_COU_4";
BA_ "ISignalName" SG_ 1070 ALIV_ST_MDRV_2 "ALIV_ST_MDRV_2";
BA_ "LongName" SG_ 1070 ALIV_ST_MDRV_2 "Alive_Status_M-Drive_2";
BA_ "SysSignalName" SG_ 1070 ALIV_ST_MDRV_2 "ALIV_ST_MDRV_2";
BA_ "CompuMethodName" SG_ 1070 ST_MDRV_2 "ST_MDRV_2";
BA_ "ISignalName" SG_ 1070 ST_MDRV_2 "ST_MDRV_2";
BA_ "LongName" SG_ 1070 ST_MDRV_2 "Status_M-Drive_2";
BA_ "SysSignalName" SG_ 1070 ST_MDRV_2 "ST_MDRV_2";
BA_ "CompuMethodName" SG_ 1070 CTR_DISP_MDRV_2 "CTR_DISP_MDRV_2";
BA_ "ISignalName" SG_ 1070 CTR_DISP_MDRV_2 "CTR_DISP_MDRV_2";
BA_ "LongName" SG_ 1070 CTR_DISP_MDRV_2 "Steuerung_Anzeige_M-Drive_2";
BA_ "SysSignalName" SG_ 1070 CTR_DISP_MDRV_2 "CTR_DISP_MDRV_2";
BA_ "CompuMethodName" SG_ 1070 ST_MDRV_2_DSC "MDRV_2_DSC";
BA_ "ISignalName" SG_ 1070 ST_MDRV_2_DSC "ST_MDRV_2_DSC";
BA_ "LongName" SG_ 1070 ST_MDRV_2_DSC "Status_M-Drive_2_DSC";
BA_ "SysSignalName" SG_ 1070 ST_MDRV_2_DSC "ST_MDRV_2_DSC";
BA_ "CompuMethodName" SG_ 1070 ST_MDRV_2_IDX "ST_MDRV_2_IDX";
BA_ "ISignalName" SG_ 1070 ST_MDRV_2_IDX "ST_MDRV_2_IDX";
BA_ "LongName" SG_ 1070 ST_MDRV_2_IDX "Status_M-Drive_2_Index";
BA_ "SysSignalName" SG_ 1070 ST_MDRV_2_IDX "ST_MDRV_2_IDX";
BA_ "CompuMethodName" SG_ 1070 ST_MDRV_2_STG_GRB "MDRV_STG_GRB";
BA_ "ISignalName" SG_ 1070 ST_MDRV_2_STG_GRB "ST_MDRV_2_STG_GRB";
BA_ "LongName" SG_ 1070 ST_MDRV_2_STG_GRB "Status_M-Drive_2_Stufe_Getriebe";
BA_ "SysSignalName" SG_ 1070 ST_MDRV_2_STG_GRB "ST_MDRV_2_STG_GRB";
BA_ "CompuMethodName" SG_ 1070 ST_MDRV_2_ENG "MDRV_2_ENG";
BA_ "ISignalName" SG_ 1070 ST_MDRV_2_ENG "ST_MDRV_2_ENG";
BA_ "LongName" SG_ 1070 ST_MDRV_2_ENG "Status_M-Drive_2_Motor";
BA_ "SysSignalName" SG_ 1070 ST_MDRV_2_ENG "ST_MDRV_2_ENG";
BA_ "CompuMethodName" SG_ 1070 ST_MDRV_2_EDC "MDRV_2_MOD";
BA_ "ISignalName" SG_ 1070 ST_MDRV_2_EDC "ST_MDRV_2_EDC";
BA_ "LongName" SG_ 1070 ST_MDRV_2_EDC "Status_M-Drive_2_Eletronische-Dämpfer-Steuerung";
BA_ "SysSignalName" SG_ 1070 ST_MDRV_2_EDC "ST_MDRV_2_EDC";
BA_ "CompuMethodName" SG_ 1070 ST_MDRV_2_EPAS "MDRV_2_MOD";
BA_ "ISignalName" SG_ 1070 ST_MDRV_2_EPAS "ST_MDRV_2_EPAS";
BA_ "LongName" SG_ 1070 ST_MDRV_2_EPAS "status_M-Drive_2_EPAS";
BA_ "SysSignalName" SG_ 1070 ST_MDRV_2_EPAS "ST_MDRV_2_EPAS";
BA_ "CompuMethodName" SG_ 1070 ST_MDRV_2_DISP_HUD "MDRV_2_DISP_HUD";
BA_ "ISignalName" SG_ 1070 ST_MDRV_2_DISP_HUD "ST_MDRV_2_DISP_HUD";
BA_ "LongName" SG_ 1070 ST_MDRV_2_DISP_HUD "Status_M-Drive_2_Anzeige_HUD";
BA_ "SysSignalName" SG_ 1070 ST_MDRV_2_DISP_HUD "ST_MDRV_2_DISP_HUD";
BA_ "CompuMethodName" SG_ 1070 ST_MDRV_2_DISP_SHLI "MDRV_DISP_SHLI";
BA_ "ISignalName" SG_ 1070 ST_MDRV_2_DISP_SHLI "ST_MDRV_2_DISP_SHLI";
BA_ "LongName" SG_ 1070 ST_MDRV_2_DISP_SHLI "Status_M-Drive_2_Anzeige_Shiftlights";
BA_ "SysSignalName" SG_ 1070 ST_MDRV_2_DISP_SHLI "ST_MDRV_2_DISP_SHLI";
BA_ "CompuMethodName" SG_ 1070 ST_MDRV_2_MOD_GRB "MDRV_MOD_GRB";
BA_ "ISignalName" SG_ 1070 ST_MDRV_2_MOD_GRB "ST_MDRV_2_MOD_GRB";
BA_ "LongName" SG_ 1070 ST_MDRV_2_MOD_GRB "Status_M-Drive_2_Modus_Getriebe";
BA_ "SysSignalName" SG_ 1070 ST_MDRV_2_MOD_GRB "ST_MDRV_2_MOD_GRB";
BA_ "CompuMethodName" SG_ 1070 RQ_AUDM_MDRV_2 "RQ_AUDM_MDRV_2";
BA_ "ISignalName" SG_ 1070 RQ_AUDM_MDRV_2 "RQ_AUDM_MDRV_2";
BA_ "LongName" SG_ 1070 RQ_AUDM_MDRV_2 "Anforderung_Akustikmeldung_M-Drive_2";
BA_ "SysSignalName" SG_ 1070 RQ_AUDM_MDRV_2 "RQ_AUDM_MDRV_2";
BA_ "CompuMethodName" SG_ 1070 ST_MDRV_2_AW "AW_SU";
BA_ "ISignalName" SG_ 1070 ST_MDRV_2_AW "ST_MDRV_2_AW";
BA_ "LongName" SG_ 1070 ST_MDRV_2_AW "Status_M-Drive_2_Allrad";
BA_ "SysSignalName" SG_ 1070 ST_MDRV_2_AW "ST_MDRV_2_AW";
BA_ "CompuMethodName" SG_ 1029 ST_MDRV_3_IDX "MDRV_3_IDX";
BA_ "ISignalName" SG_ 1029 ST_MDRV_3_IDX "ST_MDRV_3_IDX";
BA_ "LongName" SG_ 1029 ST_MDRV_3_IDX "Status_M-Drive_3_Index";
BA_ "SysSignalName" SG_ 1029 ST_MDRV_3_IDX "ST_MDRV_3_IDX";
BA_ "CompuMethodName" SG_ 1029 ST_MDRV_3_DRVGMOD "ST_MDRV_3_DRVGMOD";
BA_ "ISignalName" SG_ 1029 ST_MDRV_3_DRVGMOD "ST_MDRV_3_DRVGMOD";
BA_ "LongName" SG_ 1029 ST_MDRV_3_DRVGMOD "Status_M-Drive_3_Fahrmodus";
BA_ "SysSignalName" SG_ 1029 ST_MDRV_3_DRVGMOD "ST_MDRV_3_DRVGMOD";
BA_ "CompuMethodName" SG_ 1029 ST_MDRV_3 "ST_MDRV_3";
BA_ "ISignalName" SG_ 1029 ST_MDRV_3 "ST_MDRV_3";
BA_ "LongName" SG_ 1029 ST_MDRV_3 "Status_M-Drive_3";
BA_ "SysSignalName" SG_ 1029 ST_MDRV_3 "ST_MDRV_3";
BA_ "CompuMethodName" SG_ 1029 ST_MDRV_3_DISP_KI_HUD "ST_MDRV_3_DISP_KI_HUD";
BA_ "ISignalName" SG_ 1029 ST_MDRV_3_DISP_KI_HUD "ST_MDRV_3_DISP_KI_HUD";
BA_ "LongName" SG_ 1029 ST_MDRV_3_DISP_KI_HUD "Status_M-Drive_3_Anzeige_Kombi_HUD";
BA_ "SysSignalName" SG_ 1029 ST_MDRV_3_DISP_KI_HUD "ST_MDRV_3_DISP_KI_HUD";
BA_ "CompuMethodName" SG_ 1029 ST_MDRV_3_SOU "ST_MDRV_3_SOU";
BA_ "ISignalName" SG_ 1029 ST_MDRV_3_SOU "ST_MDRV_3_SOU";
BA_ "LongName" SG_ 1029 ST_MDRV_3_SOU "Status_M-Drive_3_Ton";
BA_ "SysSignalName" SG_ 1029 ST_MDRV_3_SOU "ST_MDRV_3_SOU";
BA_ "CompuMethodName" SG_ 1029 ST_MDRV_3_MSA "ST_MDRV_3_MSA";
BA_ "ISignalName" SG_ 1029 ST_MDRV_3_MSA "ST_MDRV_3_MSA";
BA_ "LongName" SG_ 1029 ST_MDRV_3_MSA "Status_M-Drive_3_MSA";
BA_ "SysSignalName" SG_ 1029 ST_MDRV_3_MSA "ST_MDRV_3_MSA";
BA_ "CompuMethodName" SG_ 1029 ST_MDRV_3_ASR "ST_MDRV_3_ASR";
BA_ "ISignalName" SG_ 1029 ST_MDRV_3_ASR "ST_MDRV_3_ASR";
BA_ "LongName" SG_ 1029 ST_MDRV_3_ASR "Status_M-Drive_3_ASR";
BA_ "SysSignalName" SG_ 1029 ST_MDRV_3_ASR "ST_MDRV_3_ASR";
BA_ "CompuMethodName" SG_ 1029 ST_MDRV_3_MUT "ST_MDRV_3_MUT";
BA_ "ISignalName" SG_ 1029 ST_MDRV_3_MUT "ST_MDRV_3_MUT";
BA_ "LongName" SG_ 1029 ST_MDRV_3_MUT "Status_M-Drive_3_Stummschaltung";
BA_ "SysSignalName" SG_ 1029 ST_MDRV_3_MUT "ST_MDRV_3_MUT";
BA_ "CompuMethodName" SG_ 1029 ST_MDRV_3_SAR "ST_MDRV_3_SAR";
BA_ "ISignalName" SG_ 1029 ST_MDRV_3_SAR "ST_MDRV_3_SAR";
BA_ "LongName" SG_ 1029 ST_MDRV_3_SAR "Status_M-Drive_3_SARAH";
BA_ "SysSignalName" SG_ 1029 ST_MDRV_3_SAR "ST_MDRV_3_SAR";
BA_ "CompuMethodName" SG_ 1029 ST_MDRV_3_AMB "ST_MDRV_3_AMB";
BA_ "ISignalName" SG_ 1029 ST_MDRV_3_AMB "ST_MDRV_3_AMB";
BA_ "LongName" SG_ 1029 ST_MDRV_3_AMB "Status_M-Drive_3_Ambiente";
BA_ "SysSignalName" SG_ 1029 ST_MDRV_3_AMB "ST_MDRV_3_AMB";
BA_ "CompuMethodName" SG_ 1029 ST_MDRV_3_HAZW "ST_MDRV_3_HAZW";
BA_ "ISignalName" SG_ 1029 ST_MDRV_3_HAZW "ST_MDRV_3_HAZW";
BA_ "LongName" SG_ 1029 ST_MDRV_3_HAZW "Status_M-Drive_3_Warnblinken";
BA_ "SysSignalName" SG_ 1029 ST_MDRV_3_HAZW "ST_MDRV_3_HAZW";
BA_ "CompuMethodName" SG_ 1029 ST_MDRV_3_RECW "ST_MDRV_3_RECW";
BA_ "ISignalName" SG_ 1029 ST_MDRV_3_RECW "ST_MDRV_3_RECW";
BA_ "LongName" SG_ 1029 ST_MDRV_3_RECW "Status_M-Drive_3_Auffahrwarnung";
BA_ "SysSignalName" SG_ 1029 ST_MDRV_3_RECW "ST_MDRV_3_RECW";
BA_ "CompuMethodName" SG_ 1029 ST_MDRV_3_CF_FAS "ST_MDRV_3_CF_FAS";
BA_ "ISignalName" SG_ 1029 ST_MDRV_3_CF_FAS "ST_MDRV_3_CF_FAS";
BA_ "LongName" SG_ 1029 ST_MDRV_3_CF_FAS "Status_M-Drive_3_Komfort_Fahrerassistenz";
BA_ "SysSignalName" SG_ 1029 ST_MDRV_3_CF_FAS "ST_MDRV_3_CF_FAS";
BA_ "CompuMethodName" SG_ 1029 ST_MDRV_3_BRPD "ST_MDRV_3_BRPD";
BA_ "ISignalName" SG_ 1029 ST_MDRV_3_BRPD "ST_MDRV_3_BRPD";
BA_ "LongName" SG_ 1029 ST_MDRV_3_BRPD "Status_M-Drive_3_Bremspedal";
BA_ "SysSignalName" SG_ 1029 ST_MDRV_3_BRPD "ST_MDRV_3_BRPD";
BA_ "CompuMethodName" SG_ 1029 StatusMDrive3MControlPlusDrift "StatusMControlPlusDriftSetup";
BA_ "ISignalName" SG_ 1029 StatusMDrive3MControlPlusDrift "StatusMDrive3MControlPlusDrift";
BA_ "LongName" SG_ 1029 StatusMDrive3MControlPlusDrift "StatusMDrive3MControlPlusDrift";
BA_ "SysSignalName" SG_ 1029 StatusMDrive3MControlPlusDrift "StatusMDrive3MControlPlusDrift";
BA_ "CompuMethodName" SG_ 1029 StatusMDrive3DriftSupportLevel "StatusDriftLevel";
BA_ "ISignalName" SG_ 1029 StatusMDrive3DriftSupportLevel "StatusMDrive3DriftSupportLevel";
BA_ "LongName" SG_ 1029 StatusMDrive3DriftSupportLevel "StatusMDrive3DriftSupportLevel";
BA_ "SysSignalName" SG_ 1029 StatusMDrive3DriftSupportLevel "StatusMDrive3DriftSupportLevel";
BA_ "CompuMethodName" SG_ 1029 StatusMDrive3MControlPlusTractio "StatusTractionLevel";
BA_ "ISignalName" SG_ 1029 StatusMDrive3MControlPlusTractio "StatusMDrive3MControlPlusTractionSupportLevel";
BA_ "LongName" SG_ 1029 StatusMDrive3MControlPlusTractio "StatusMDrive3MControlPlusTractionSupportLevel";
BA_ "SysSignalName" SG_ 1029 StatusMDrive3MControlPlusTractio "StatusMDrive3MControlPlusTractionSupportLevel";
BA_ "SystemSignalLongSymbol" SG_ 1029 StatusMDrive3MControlPlusTractio "StatusMDrive3MControlPlusTractionSupportLevel";
BA_ "CompuMethodName" SG_ 1029 StatusMDrive3MControlPlusBrakeBa "StatusBalanceLevel";
BA_ "ISignalName" SG_ 1029 StatusMDrive3MControlPlusBrakeBa "StatusMDrive3MControlPlusBrakeBalanceSupportLevel";
BA_ "LongName" SG_ 1029 StatusMDrive3MControlPlusBrakeBa "StatusMDrive3MControlPlusBrakeBalanceSupportLevel";
BA_ "SysSignalName" SG_ 1029 StatusMDrive3MControlPlusBrakeBa "StatusMDrive3MControlPlusBrakeBalanceSupportLevel";
BA_ "SystemSignalLongSymbol" SG_ 1029 StatusMDrive3MControlPlusBrakeBa "StatusMDrive3MControlPlusBrakeBalanceSupportLevel";
BA_ "CompuMethodName" SG_ 1199 ST_CON_VEH_DBG "ST_CON_VEH_DBG";
BA_ "ISignalName" SG_ 1199 ST_CON_VEH_DBG "ST_CON_VEH_DBG";
BA_ "LongName" SG_ 1199 ST_CON_VEH_DBG "Status_Zustand_Fahrzeug_Debug";
BA_ "SysSignalName" SG_ 1199 ST_CON_VEH_DBG "ST_CON_VEH_DBG";
BA_ "CompuMethodName" SG_ 1199 ST_CON_VEH_PING_DBG "ST_CON_VEH_PING_DBG";
BA_ "ISignalName" SG_ 1199 ST_CON_VEH_PING_DBG "ST_CON_VEH_PING_DBG";
BA_ "LongName" SG_ 1199 ST_CON_VEH_PING_DBG "Status_Zustand_Fahrzeug_Ping_Debug";
BA_ "SysSignalName" SG_ 1199 ST_CON_VEH_PING_DBG "ST_CON_VEH_PING_DBG";
BA_ "CompuMethodName" SG_ 1199 ST_CON_VEH_OD "ST_CON_VEH_OD";
BA_ "ISignalName" SG_ 1199 ST_CON_VEH_OD "ST_CON_VEH_OD";
BA_ "LongName" SG_ 1199 ST_CON_VEH_OD "Status_Zustand_Fahrzeug_Alt";
BA_ "SysSignalName" SG_ 1199 ST_CON_VEH_OD "ST_CON_VEH_OD";
BA_ "CompuMethodName" SG_ 1199 ST_FTF_MOD "ST_FTF_MOD";
BA_ "ISignalName" SG_ 1199 ST_FTF_MOD "ST_FTF_MOD";
BA_ "LongName" SG_ 1199 ST_FTF_MOD "Status_FeTraFla_Modus";
BA_ "SysSignalName" SG_ 1199 ST_FTF_MOD "ST_FTF_MOD";
BA_ "CompuMethodName" SG_ 1199 ST_SHR_MOD "ST_SHR_MOD";
BA_ "ISignalName" SG_ 1199 ST_SHR_MOD "ST_SHR_MOD";
BA_ "LongName" SG_ 1199 ST_SHR_MOD "Status_Messe_Modus";
BA_ "SysSignalName" SG_ 1199 ST_SHR_MOD "ST_SHR_MOD";
BA_ "CompuMethodName" SG_ 1199 ST_END_DRVG_DBG "ST_END_DRVG_DBG";
BA_ "ISignalName" SG_ 1199 ST_END_DRVG_DBG "ST_END_DRVG_DBG";
BA_ "LongName" SG_ 1199 ST_END_DRVG_DBG "Status_Ende_Fahren_Debug";
BA_ "SysSignalName" SG_ 1199 ST_END_DRVG_DBG "ST_END_DRVG_DBG";
BA_ "CompuMethodName" SG_ 1199 ST_OCC_GTOU "ST_OCC_GTOU";
BA_ "ISignalName" SG_ 1199 ST_OCC_GTOU "ST_OCC_GTOU";
BA_ "LongName" SG_ 1199 ST_OCC_GTOU "Status_Insassen_Ausstieg";
BA_ "SysSignalName" SG_ 1199 ST_OCC_GTOU "ST_OCC_GTOU";
BA_ "CompuMethodName" SG_ 1199 ST_CTG_SPFN_DBG "ST_CTG_SPFN_DBG";
BA_ "ISignalName" SG_ 1199 ST_CTG_SPFN_DBG "ST_CTG_SPFN_DBG";
BA_ "LongName" SG_ 1199 ST_CTG_SPFN_DBG "Status_Kategorie_Sonderfunktion_Debug";
BA_ "SysSignalName" SG_ 1199 ST_CTG_SPFN_DBG "ST_CTG_SPFN_DBG";
BA_ "CompuMethodName" SG_ 1199 ST_VEH_CON_TIM "ST_VEH_TIM";
BA_ "ISignalName" SG_ 1199 ST_VEH_CON_TIM "ST_VEH_CON_TIM";
BA_ "LongName" SG_ 1199 ST_VEH_CON_TIM "Status_Fahrzeug_Zustand_Timer";
BA_ "SysSignalName" SG_ 1199 ST_VEH_CON_TIM "ST_VEH_CON_TIM";
BA_ "CompuMethodName" SG_ 1199 ST_KL_30B_SWOT "ST_VEH_TIM";
BA_ "ISignalName" SG_ 1199 ST_KL_30B_SWOT "ST_KL_30B_SWOT";
BA_ "LongName" SG_ 1199 ST_KL_30B_SWOT "status_klemme_30b_switch-off-timeout";
BA_ "SysSignalName" SG_ 1199 ST_KL_30B_SWOT "ST_KL_30B_SWOT";
BA_ "CompuMethodName" SG_ 1199 ST_KL_30B_NSOT "ST_VEH_TIM";
BA_ "ISignalName" SG_ 1199 ST_KL_30B_NSOT "ST_KL_30B_NSOT";
BA_ "LongName" SG_ 1199 ST_KL_30B_NSOT "Status_Klemme_30b_Nicht-Abschaltbar-Timeout";
BA_ "SysSignalName" SG_ 1199 ST_KL_30B_NSOT "ST_KL_30B_NSOT";
BA_ "CompuMethodName" SG_ 1199 ST_PFN_TMOUT "ST_VEH_TIM";
BA_ "ISignalName" SG_ 1199 ST_PFN_TMOUT "ST_PFN_TMOUT";
BA_ "LongName" SG_ 1199 ST_PFN_TMOUT "Status_Standfunktion_Timeout";
BA_ "SysSignalName" SG_ 1199 ST_PFN_TMOUT "ST_PFN_TMOUT";
BA_ "CompuMethodName" SG_ 1199 ST_VEH_IACTN_TRANS "ST_VEH_IACTN_TRANS";
BA_ "ISignalName" SG_ 1199 ST_VEH_IACTN_TRANS "ST_VEH_IACTN_TRANS";
BA_ "LongName" SG_ 1199 ST_VEH_IACTN_TRANS "Status_Fahrzeug_Interaktion_Übergang";
BA_ "SysSignalName" SG_ 1199 ST_VEH_IACTN_TRANS "ST_VEH_IACTN_TRANS";
BA_ "CompuMethodName" SG_ 1089 ST_TIM_OSFG "ST_TIM_OSFG";
BA_ "ISignalName" SG_ 1089 ST_TIM_OSFG "ST_TIM_OSFG";
BA_ "LongName" SG_ 1089 ST_TIM_OSFG "Status_Timer_OSFG";
BA_ "SysSignalName" SG_ 1089 ST_TIM_OSFG "ST_TIM_OSFG";
BA_ "CompuMethodName" SG_ 1089 ST_CODG_LVG "ST_CODG_LVG";
BA_ "ISignalName" SG_ 1089 ST_CODG_LVG "ST_CODG_LVG";
BA_ "LongName" SG_ 1089 ST_CODG_LVG "Status_Codierung_Wohnen";
BA_ "SysSignalName" SG_ 1089 ST_CODG_LVG "ST_CODG_LVG";
BA_ "CompuMethodName" SG_ 1089 ST_CODG_PFN "ST_CODG_PFN";
BA_ "ISignalName" SG_ 1089 ST_CODG_PFN "ST_CODG_PFN";
BA_ "LongName" SG_ 1089 ST_CODG_PFN "Status_Codierung_Standfunktion";
BA_ "SysSignalName" SG_ 1089 ST_CODG_PFN "ST_CODG_PFN";
BA_ "CompuMethodName" SG_ 1089 ST_CON_FB_TRM "ST_CON_FB_TRM";
BA_ "ISignalName" SG_ 1089 ST_CON_FB_TRM "ST_CON_FB_TRM";
BA_ "LongName" SG_ 1089 ST_CON_FB_TRM "Status_Zustand_FB_Beenden";
BA_ "SysSignalName" SG_ 1089 ST_CON_FB_TRM "ST_CON_FB_TRM";
BA_ "CompuMethodName" SG_ 1089 ST_RQ_TN_DM "ST_RQ_TN_DM";
BA_ "ISignalName" SG_ 1089 ST_RQ_TN_DM "ST_RQ_TN_DM";
BA_ "LongName" SG_ 1089 ST_RQ_TN_DM "Status_Anforderung_TN_Domaenenmaster";
BA_ "SysSignalName" SG_ 1089 ST_RQ_TN_DM "ST_RQ_TN_DM";
BA_ "CompuMethodName" SG_ 1089 ST_TRM_LVG_DBG "ST_TRM_LVG_DBG";
BA_ "ISignalName" SG_ 1089 ST_TRM_LVG_DBG "ST_TRM_LVG_DBG";
BA_ "LongName" SG_ 1089 ST_TRM_LVG_DBG "Status_Beenden_Wohnen_Debug";
BA_ "SysSignalName" SG_ 1089 ST_TRM_LVG_DBG "ST_TRM_LVG_DBG";
BA_ "CompuMethodName" SG_ 1089 ST_COU_CCM "ST_COU_CCM";
BA_ "ISignalName" SG_ 1089 ST_COU_CCM "ST_COU_CCM";
BA_ "LongName" SG_ 1089 ST_COU_CCM "Status_Zähler_CCM";
BA_ "SysSignalName" SG_ 1089 ST_COU_CCM "ST_COU_CCM";
BA_ "CompuMethodName" SG_ 1089 ST_CODG_OSFG "ST_CODG_OSFG";
BA_ "ISignalName" SG_ 1089 ST_CODG_OSFG "ST_CODG_OSFG";
BA_ "LongName" SG_ 1089 ST_CODG_OSFG "Status_Codierung_OSFG";
BA_ "SysSignalName" SG_ 1089 ST_CODG_OSFG "ST_CODG_OSFG";
BA_ "CompuMethodName" SG_ 1089 ST_CODG_U_PWF "ST_CODG_U_PWF";
BA_ "GenSigStartValue" SG_ 1089 ST_CODG_U_PWF 10;
BA_ "ISignalName" SG_ 1089 ST_CODG_U_PWF "ST_CODG_U_PWF";
BA_ "LongName" SG_ 1089 ST_CODG_U_PWF "Status_Codierung_Spannung_PWF";
BA_ "SysSignalName" SG_ 1089 ST_CODG_U_PWF "ST_CODG_U_PWF";
BA_ "CompuMethodName" SG_ 1089 ST_U_BDC "ST_U_BDC";
BA_ "ISignalName" SG_ 1089 ST_U_BDC "ST_U_BDC";
BA_ "LongName" SG_ 1089 ST_U_BDC "Status_Spannung_BDC";
BA_ "SysSignalName" SG_ 1089 ST_U_BDC "ST_U_BDC";
BA_ "CompuMethodName" SG_ 900 CRC_StatusMSystem "CRC8";
BA_ "ISignalName" SG_ 900 CRC_StatusMSystem "CRC_StatusMSystem";
BA_ "LongName" SG_ 900 CRC_StatusMSystem "CRC_StatusMSystem";
BA_ "SysSignalName" SG_ 900 CRC_StatusMSystem "CRC_StatusMSystem";
BA_ "CompuMethodName" SG_ 900 Alive_StatusMSystem "ALIV_4_BIT_UInt";
BA_ "ISignalName" SG_ 900 Alive_StatusMSystem "Alive_StatusMSystem";
BA_ "LongName" SG_ 900 Alive_StatusMSystem "Alive_StatusMSystem";
BA_ "SysSignalName" SG_ 900 Alive_StatusMSystem "Alive_StatusMSystem";
BA_ "CompuMethodName" SG_ 900 CHL_StatusMSystem "CHL_4Uint";
BA_ "ISignalName" SG_ 900 CHL_StatusMSystem "CHL_StatusMSystem";
BA_ "LongName" SG_ 900 CHL_StatusMSystem "CHL_StatusMSystem";
BA_ "SysSignalName" SG_ 900 CHL_StatusMSystem "CHL_StatusMSystem";
BA_ "CompuMethodName" SG_ 900 ST_AW_SU "ST_AW_SU";
BA_ "ISignalName" SG_ 900 ST_AW_SU "ST_AW_SU";
BA_ "LongName" SG_ 900 ST_AW_SU "Status_Allrad_Konfiguration";
BA_ "SysSignalName" SG_ 900 ST_AW_SU "ST_AW_SU";
BA_ "CompuMethodName" SG_ 900 QU_FN_AW "QU_FN_AW";
BA_ "ISignalName" SG_ 900 QU_FN_AW "QU_FN_AW";
BA_ "LongName" SG_ 900 QU_FN_AW "Qualifier_Funktion_Allrad";
BA_ "SysSignalName" SG_ 900 QU_FN_AW "QU_FN_AW";
BA_ "ISignalName" SG_ 900 ST_MSYS_dummy_23_23 "ST_MSYS_dummy_23_23";
BA_ "LongName" SG_ 900 ST_MSYS_dummy_23_23 "ST_MSYS_dummy_23_23";
BA_ "SysSignalName" SG_ 900 ST_MSYS_dummy_23_23 "ST_MSYS_dummy_23_23";
BA_ "CompuMethodName" SG_ 900 ST_BRPD_SU "ST_BRPD_SU";
BA_ "ISignalName" SG_ 900 ST_BRPD_SU "ST_BRPD_SU";
BA_ "LongName" SG_ 900 ST_BRPD_SU "Status_Bremspedal_Konfiguration";
BA_ "SysSignalName" SG_ 900 ST_BRPD_SU "ST_BRPD_SU";
BA_ "CompuMethodName" SG_ 900 QU_FN_BRPD "QU_FN_BRPD";
BA_ "ISignalName" SG_ 900 QU_FN_BRPD "QU_FN_BRPD";
BA_ "LongName" SG_ 900 QU_FN_BRPD "Qualifier_Funktion_Bremspedal";
BA_ "SysSignalName" SG_ 900 QU_FN_BRPD "QU_FN_BRPD";
BA_ "CompuMethodName" SG_ 900 StatusMControlPlusDriftSetup "StatusMControlPlusDriftSetup";
BA_ "ISignalName" SG_ 900 StatusMControlPlusDriftSetup "StatusMControlPlusDriftSetup";
BA_ "LongName" SG_ 900 StatusMControlPlusDriftSetup "StatusMControlPlusDriftSetup";
BA_ "SysSignalName" SG_ 900 StatusMControlPlusDriftSetup "StatusMControlPlusDriftSetup";
BA_ "CompuMethodName" SG_ 900 StatusDriftSupportLevelSetup "StatusDriftLevel";
BA_ "ISignalName" SG_ 900 StatusDriftSupportLevelSetup "StatusDriftSupportLevelSetup";
BA_ "LongName" SG_ 900 StatusDriftSupportLevelSetup "StatusDriftSupportLevelSetup";
BA_ "SysSignalName" SG_ 900 StatusDriftSupportLevelSetup "StatusDriftSupportLevelSetup";
BA_ "CompuMethodName" SG_ 900 StatusMControlPlusTractionLevelS "StatusTractionLevel";
BA_ "ISignalName" SG_ 900 StatusMControlPlusTractionLevelS "StatusMControlPlusTractionLevelSetup";
BA_ "LongName" SG_ 900 StatusMControlPlusTractionLevelS "StatusMControlPlusTractionLevelSetup";
BA_ "SysSignalName" SG_ 900 StatusMControlPlusTractionLevelS "StatusMControlPlusTractionLevelSetup";
BA_ "SystemSignalLongSymbol" SG_ 900 StatusMControlPlusTractionLevelS "StatusMControlPlusTractionLevelSetup";
BA_ "CompuMethodName" SG_ 900 StatusMControlPlusBrakeBalanceLe "StatusBalanceLevel";
BA_ "ISignalName" SG_ 900 StatusMControlPlusBrakeBalanceLe "StatusMControlPlusBrakeBalanceLevelSetup";
BA_ "LongName" SG_ 900 StatusMControlPlusBrakeBalanceLe "StatusMControlPlusBrakeBalanceLevelSetup";
BA_ "SysSignalName" SG_ 900 StatusMControlPlusBrakeBalanceLe "StatusMControlPlusBrakeBalanceLevelSetup";
BA_ "SystemSignalLongSymbol" SG_ 900 StatusMControlPlusBrakeBalanceLe "StatusMControlPlusBrakeBalanceLevelSetup";
BA_ "ISignalName" SG_ 900 ST_MSYS_dummy_48_63 "ST_MSYS_dummy_48_63";
BA_ "LongName" SG_ 900 ST_MSYS_dummy_48_63 "ST_MSYS_dummy_48_63";
BA_ "SysSignalName" SG_ 900 ST_MSYS_dummy_48_63 "ST_MSYS_dummy_48_63";
BA_ "CompuMethodName" SG_ 150 PO_CUOFL_DIPB_FLA "BNDRY_DOM_BOT_NGL_FLA";
BA_ "GenSigStartValue" SG_ 150 PO_CUOFL_DIPB_FLA -5;
BA_ "ISignalName" SG_ 150 PO_CUOFL_DIPB_FLA "PO_CUOFL_DIPB_FLA";
BA_ "LongName" SG_ 150 PO_CUOFL_DIPB_FLA "Position_Hell-Dunkel-Grenze_Abblendlicht_FLA";
BA_ "SysSignalName" SG_ 150 PO_CUOFL_DIPB_FLA "PO_CUOFL_DIPB_FLA";
BA_ "CompuMethodName" SG_ 150 HLW_DIPB_FLA "HLW_DIPB_FLA";
BA_ "ISignalName" SG_ 150 HLW_DIPB_FLA "HLW_DIPB_FLA";
BA_ "LongName" SG_ 150 HLW_DIPB_FLA "Leuchtweite_Abblendlicht_FLA";
BA_ "SysSignalName" SG_ 150 HLW_DIPB_FLA "HLW_DIPB_FLA";
BA_ "CompuMethodName" SG_ 150 PO_CUOFL_LH_MAB_FLA "BNDRY_DOM_NGL_LH_FLA";
BA_ "GenSigStartValue" SG_ 150 PO_CUOFL_LH_MAB_FLA -10;
BA_ "ISignalName" SG_ 150 PO_CUOFL_LH_MAB_FLA "PO_CUOFL_LH_MAB_FLA";
BA_ "LongName" SG_ 150 PO_CUOFL_LH_MAB_FLA "Position_Hell-Dunkel-Grenze_Links_Fernlicht_FLA";
BA_ "SysSignalName" SG_ 150 PO_CUOFL_LH_MAB_FLA "PO_CUOFL_LH_MAB_FLA";
BA_ "CompuMethodName" SG_ 150 PO_CUOFL_RH_MAB_FLA "BNDRY_DOM_NGL_RH_FLA";
BA_ "GenSigStartValue" SG_ 150 PO_CUOFL_RH_MAB_FLA -15;
BA_ "ISignalName" SG_ 150 PO_CUOFL_RH_MAB_FLA "PO_CUOFL_RH_MAB_FLA";
BA_ "LongName" SG_ 150 PO_CUOFL_RH_MAB_FLA "Position_Hell-Dunkel-Grenze_Rechts_Fernlicht_FLA";
BA_ "SysSignalName" SG_ 150 PO_CUOFL_RH_MAB_FLA "PO_CUOFL_RH_MAB_FLA";
BA_ "CompuMethodName" SG_ 150 ST_PO_CUOFL_MAB_FLA "ST_PO_CUOFL_MAB_3_FLA";
BA_ "ISignalName" SG_ 150 ST_PO_CUOFL_MAB_FLA "ST_PO_CUOFL_MAB_FLA";
BA_ "LongName" SG_ 150 ST_PO_CUOFL_MAB_FLA "Status_Position_Hell-Dunkel-Grenze_Fernlicht_FLA";
BA_ "SysSignalName" SG_ 150 ST_PO_CUOFL_MAB_FLA "ST_PO_CUOFL_MAB_FLA";
BA_ "CompuMethodName" SG_ 150 ST_HLW_DIPB_FLA "ST_PO_CUOFL_MAB_FLA";
BA_ "ISignalName" SG_ 150 ST_HLW_DIPB_FLA "ST_HLW_DIPB_FLA";
BA_ "LongName" SG_ 150 ST_HLW_DIPB_FLA "Status_Leuchtweite_Abblendlicht_FLA";
BA_ "SysSignalName" SG_ 150 ST_HLW_DIPB_FLA "ST_HLW_DIPB_FLA";
BA_ "CompuMethodName" SG_ 150 ST_PO_CUOFL_LH_MAB_FLA "ST_PO_CUOFL_MAB_2_FLA";
BA_ "ISignalName" SG_ 150 ST_PO_CUOFL_LH_MAB_FLA "ST_PO_CUOFL_LH_MAB_FLA";
BA_ "LongName" SG_ 150 ST_PO_CUOFL_LH_MAB_FLA "Status_Position_Hell-Dunkel-Grenze_Links_Fernlicht_FLA";
BA_ "SysSignalName" SG_ 150 ST_PO_CUOFL_LH_MAB_FLA "ST_PO_CUOFL_LH_MAB_FLA";
BA_ "CompuMethodName" SG_ 150 ST_PO_CUOFL_RH_MAB_FLA "ST_PO_CUOFL_MAB_2_FLA";
BA_ "ISignalName" SG_ 150 ST_PO_CUOFL_RH_MAB_FLA "ST_PO_CUOFL_RH_MAB_FLA";
BA_ "LongName" SG_ 150 ST_PO_CUOFL_RH_MAB_FLA "Status_Position_Hell-Dunkel-Grenze_Rechts_Fernlicht_FLA";
BA_ "SysSignalName" SG_ 150 ST_PO_CUOFL_RH_MAB_FLA "ST_PO_CUOFL_RH_MAB_FLA";
BA_ "CompuMethodName" SG_ 150 PO_DIM_1_LH_FLA "PO_DIM_LH_FLA";
BA_ "GenSigStartValue" SG_ 150 PO_DIM_1_LH_FLA -10;
BA_ "ISignalName" SG_ 150 PO_DIM_1_LH_FLA "PO_DIM_1_LH_FLA";
BA_ "LongName" SG_ 150 PO_DIM_1_LH_FLA "Position_Dimmung_1_Links_FLA";
BA_ "SysSignalName" SG_ 150 PO_DIM_1_LH_FLA "PO_DIM_1_LH_FLA";
BA_ "CompuMethodName" SG_ 150 PO_DIM_1_RH_FLA "PO_DIM_RH_FLA";
BA_ "GenSigStartValue" SG_ 150 PO_DIM_1_RH_FLA -15;
BA_ "ISignalName" SG_ 150 PO_DIM_1_RH_FLA "PO_DIM_1_RH_FLA";
BA_ "LongName" SG_ 150 PO_DIM_1_RH_FLA "Position_Dimmung_1_Rechts_FLA";
BA_ "SysSignalName" SG_ 150 PO_DIM_1_RH_FLA "PO_DIM_1_RH_FLA";
BA_ "CompuMethodName" SG_ 150 BNDRY_DIM_1_BOT_FLA "BNDRY_DIM_BOT_FLA";
BA_ "GenSigStartValue" SG_ 150 BNDRY_DIM_1_BOT_FLA -6;
BA_ "ISignalName" SG_ 150 BNDRY_DIM_1_BOT_FLA "BNDRY_DIM_1_BOT_FLA";
BA_ "LongName" SG_ 150 BNDRY_DIM_1_BOT_FLA "Grenze_Dimmung_1_Unten_FLA";
BA_ "SysSignalName" SG_ 150 BNDRY_DIM_1_BOT_FLA "BNDRY_DIM_1_BOT_FLA";
BA_ "CompuMethodName" SG_ 150 ST_DIM_1_FLA "Status_DIM_FLA";
BA_ "ISignalName" SG_ 150 ST_DIM_1_FLA "ST_DIM_1_FLA";
BA_ "LongName" SG_ 150 ST_DIM_1_FLA "Status_Dimmung_1_FLA";
BA_ "SysSignalName" SG_ 150 ST_DIM_1_FLA "ST_DIM_1_FLA";
BA_ "CompuMethodName" SG_ 798 CTR_PFGS "Enum_2bit_ON_OFF";
BA_ "ISignalName" SG_ 798 CTR_PFGS "CTR_PFGS";
BA_ "LongName" SG_ 798 CTR_PFGS "Steuerung_pFGS";
BA_ "SysSignalName" SG_ 798 CTR_PFGS "CTR_PFGS";
BA_ "CompuMethodName" SG_ 798 CTR_OPTN_ACTVN_GZA "Enum_2bit_ON_OFF";
BA_ "ISignalName" SG_ 798 CTR_OPTN_ACTVN_GZA "CTR_OPTN_ACTVN_GZA";
BA_ "LongName" SG_ 798 CTR_OPTN_ACTVN_GZA "Steuerung_Option_Aktivierung_GZA";
BA_ "SysSignalName" SG_ 798 CTR_OPTN_ACTVN_GZA "CTR_OPTN_ACTVN_GZA";
BA_ "CompuMethodName" SG_ 798 CTR_NIPE "Enum_2bit_ON_OFF";
BA_ "ISignalName" SG_ 798 CTR_NIPE "CTR_NIPE";
BA_ "LongName" SG_ 798 CTR_NIPE "Steuerung_NIVI-PE";
BA_ "SysSignalName" SG_ 798 CTR_NIPE "CTR_NIPE";
BA_ "CompuMethodName" SG_ 430 ST_LP_SW "ST_LP_SW";
BA_ "ISignalName" SG_ 430 ST_LP_SW "ST_LP_SW";
BA_ "LongName" SG_ 430 ST_LP_SW "Status_Licht_Schalter";
BA_ "SysSignalName" SG_ 430 ST_LP_SW "ST_LP_SW";
BA_ "CompuMethodName" SG_ 430 RCOG_EVT_LP_SW "RCOG_EVT_LP_SW";
BA_ "ISignalName" SG_ 430 RCOG_EVT_LP_SW "RCOG_EVT_LP_SW";
BA_ "LongName" SG_ 430 RCOG_EVT_LP_SW "Erkennung_Ereignis_Licht_Schalter";
BA_ "SysSignalName" SG_ 430 RCOG_EVT_LP_SW "RCOG_EVT_LP_SW";
BA_ "CompuMethodName" SG_ 430 AVAI_LP_SW_PLI_LH "AVAI_LP_SW";
BA_ "ISignalName" SG_ 430 AVAI_LP_SW_PLI_LH "AVAI_LP_SW_PLI_LH";
BA_ "LongName" SG_ 430 AVAI_LP_SW_PLI_LH "Verfügbarkeit_Licht_Schalter_Parklicht_Links";
BA_ "SysSignalName" SG_ 430 AVAI_LP_SW_PLI_LH "AVAI_LP_SW_PLI_LH";
BA_ "CompuMethodName" SG_ 430 AVAI_LP_SW_PLI_RH "AVAI_LP_SW_PLI_RH";
BA_ "ISignalName" SG_ 430 AVAI_LP_SW_PLI_RH "AVAI_LP_SW_PLI_RH";
BA_ "LongName" SG_ 430 AVAI_LP_SW_PLI_RH "Verfügbarkeit_Licht_Schalter_Parklicht_Rechts";
BA_ "SysSignalName" SG_ 430 AVAI_LP_SW_PLI_RH "AVAI_LP_SW_PLI_RH";
BA_ "CompuMethodName" SG_ 430 AVAI_LP_SW_AUT "AVAI_LP_SW_AUT";
BA_ "ISignalName" SG_ 430 AVAI_LP_SW_AUT "AVAI_LP_SW_AUT";
BA_ "LongName" SG_ 430 AVAI_LP_SW_AUT "Verfügbarkeit_Licht_Schalter_Automatik";
BA_ "SysSignalName" SG_ 430 AVAI_LP_SW_AUT "AVAI_LP_SW_AUT";
BA_ "CompuMethodName" SG_ 430 AVAI_LP_SW_LP_OFF "AVAI_LP_SW_LP_OFF";
BA_ "ISignalName" SG_ 430 AVAI_LP_SW_LP_OFF "AVAI_LP_SW_LP_OFF";
BA_ "LongName" SG_ 430 AVAI_LP_SW_LP_OFF "Verfügbarkeit_Licht_Schalter_Licht_Aus";
BA_ "SysSignalName" SG_ 430 AVAI_LP_SW_LP_OFF "AVAI_LP_SW_LP_OFF";
BA_ "CompuMethodName" SG_ 430 AVAI_LP_SW_POLI "AVAI_LP_SW_POLI";
BA_ "ISignalName" SG_ 430 AVAI_LP_SW_POLI "AVAI_LP_SW_POLI";
BA_ "LongName" SG_ 430 AVAI_LP_SW_POLI "Verfügbarkeit_Licht_Schalter_Standlicht";
BA_ "SysSignalName" SG_ 430 AVAI_LP_SW_POLI "AVAI_LP_SW_POLI";
BA_ "CompuMethodName" SG_ 430 AVAI_LP_SW_LOWB_MAN "AVAI_LP_SW_LOWB_MAN";
BA_ "ISignalName" SG_ 430 AVAI_LP_SW_LOWB_MAN "AVAI_LP_SW_LOWB_MAN";
BA_ "LongName" SG_ 430 AVAI_LP_SW_LOWB_MAN "Verfügbarkeit_Licht_Schalter_Fahrlicht_Manuell";
BA_ "SysSignalName" SG_ 430 AVAI_LP_SW_LOWB_MAN "AVAI_LP_SW_LOWB_MAN";
BA_ "CompuMethodName" SG_ 430 AVAI_LP_SW_FFLI "AVAI_LP_SW_FFLI";
BA_ "ISignalName" SG_ 430 AVAI_LP_SW_FFLI "AVAI_LP_SW_FFLI";
BA_ "LongName" SG_ 430 AVAI_LP_SW_FFLI "Verfügbarkeit_Licht_Schalter_Nebelscheinwerfer";
BA_ "SysSignalName" SG_ 430 AVAI_LP_SW_FFLI "AVAI_LP_SW_FFLI";
BA_ "CompuMethodName" SG_ 430 AVAI_LP_SW_RFLP "AVAI_LP_SW_RFLP";
BA_ "ISignalName" SG_ 430 AVAI_LP_SW_RFLP "AVAI_LP_SW_RFLP";
BA_ "LongName" SG_ 430 AVAI_LP_SW_RFLP "Verfügbarkeit_Licht_Schalter_Nebelschlußlicht";
BA_ "SysSignalName" SG_ 430 AVAI_LP_SW_RFLP "AVAI_LP_SW_RFLP";
VAL_ 628 ST_SBIL_DRR 0 "Status der Sitzlehnenverriegelung kann nicht bestimmt werden." 1 "Sitzlehne_verriegelt" 2 "Sitzlehne_nicht_verriegelt" 3 "Signal_unbefuellt";
VAL_ 628 ST_SBIL_DRR3 0 "Status der Sitzlehnenverriegelung kann nicht bestimmt werden." 1 "Sitzlehne_verriegelt" 2 "Sitzlehne_nicht_verriegelt" 3 "Signal_unbefuellt";
VAL_ 628 BR_TLT_PO_DRR 253 "SIGNALTAG_FCTIF_NOT_AVAILABLE" 254 "SIGNALTAG_FCT_ERROR" 255 "Sendefunktion nicht in Betrieb";
VAL_ 628 BR_TLT_PO_DRR3 253 "SIGNALTAG_FCTIF_NOT_AVAILABLE" 254 "SIGNALTAG_FCT_ERROR" 255 "Sendefunktion nicht in Betrieb";
VAL_ 628 ST_EMULOK_DRR 0 "Status der Sitzlehnenverriegelung kann nicht bestimmt werden." 1 "Sitzlehne_verriegelt" 2 "Sitzlehne_nicht_verriegelt" 3 "Sendefunktion nicht in Betrieb";
VAL_ 628 ST_AD_BOOT_FNS_DRR 0 "Keine_Aktion" 1 "Gesperrt" 2 "Kennfelder_HW_Defekt" 3 "Abbruch" 5 "Hinweis: Reserviert für funktionale Kennung Signal-Tag." 6 "Hinweis: Reserviert für funktionale Kennung Signal-Tag." 7 "Sendefunktion nicht in Betrieb";
VAL_ 628 ST_AD_BOOT_FNS_DRR3 0 "Keine_Aktion" 1 "Gesperrt" 2 "Kennfelder_HW_Defekt" 3 "Abbruch" 5 "Hinweis: Reserviert für funktionale Kennung Signal-Tag." 6 "Hinweis: Reserviert für funktionale Kennung Signal-Tag." 7 "Sendefunktion nicht in Betrieb";
VAL_ 628 ST_SEAT_EEL_PLCHK_DRR 0 "Verriegelte EasyEntry-Schalter erwartet" 1 "Status aufgrund Position nicht verfügbar" 2 "Nicht-verriegelte EasyEntry-Schalter erwartet" 13 "SIGNALTAG_FCTIF_NOT_AVAILABLE" 14 "SIGNALTAG_FCT_ERROR" 15 "Sendefunktion nicht in Betrieb";
VAL_ 628 CTR_LED_NAD_TIR_2 0 "Keine Ansteuerung des LEDs" 1 "Blinken" 2 "Flashen" 3 "Sendefunktion nicht in Betrieb";
VAL_ 628 CTR_LED_NAD_TIR_3 0 "Keine Ansteuerung des LEDs" 1 "Blinken" 2 "Flashen" 3 "Sendefunktion nicht in Betrieb";
VAL_ 628 CTR_LED_NAD_BOOT_FNS 0 "Keine Ansteuerung des LEDs" 1 "Blinken" 2 "Flashen" 3 "Sendefunktion nicht in Betrieb";
VAL_ 629 ST_SBIL_PSR 0 "Status der Sitzlehnenverriegelung kann nicht bestimmt werden." 1 "Sitzlehne_verriegelt" 2 "Sitzlehne_nicht_verriegelt" 3 "Signal_unbefuellt";
VAL_ 629 ST_SBIL_PSR3 0 "Status der Sitzlehnenverriegelung kann nicht bestimmt werden." 1 "Sitzlehne_verriegelt" 2 "Sitzlehne_nicht_verriegelt" 3 "Signal_unbefuellt";
VAL_ 629 BR_TLT_PO_PSR 253 "SIGNALTAG_FCTIF_NOT_AVAILABLE" 254 "SIGNALTAG_FCT_ERROR" 255 "Sendefunktion nicht in Betrieb";
VAL_ 629 BR_TLT_PO_PSR3 253 "SIGNALTAG_FCTIF_NOT_AVAILABLE" 254 "SIGNALTAG_FCT_ERROR" 255 "Sendefunktion nicht in Betrieb";
VAL_ 629 ST_EMULOK_PSR 0 "Status der Sitzlehnenverriegelung kann nicht bestimmt werden." 1 "Sitzlehne_verriegelt" 2 "Sitzlehne_nicht_verriegelt" 3 "Sendefunktion nicht in Betrieb";
VAL_ 629 ST_AD_BOOT_FNS_PSR 0 "Keine_Aktion" 1 "Gesperrt" 2 "Kennfelder_HW_Defekt" 3 "Abbruch" 5 "Hinweis: Reserviert für funktionale Kennung Signal-Tag." 6 "Hinweis: Reserviert für funktionale Kennung Signal-Tag." 7 "Sendefunktion nicht in Betrieb";
VAL_ 629 ST_AD_BOOT_FNS_PSR3 0 "Keine_Aktion" 1 "Gesperrt" 2 "Kennfelder_HW_Defekt" 3 "Abbruch" 5 "Hinweis: Reserviert für funktionale Kennung Signal-Tag." 6 "Hinweis: Reserviert für funktionale Kennung Signal-Tag." 7 "Sendefunktion nicht in Betrieb";
VAL_ 629 ST_SEAT_EEL_PLCHK_PSR 0 "Verriegelte EasyEntry-Schalter erwartet" 1 "Status aufgrund Position nicht verfügbar" 2 "Nicht-verriegelte EasyEntry-Schalter erwartet" 13 "SIGNALTAG_FCTIF_NOT_AVAILABLE" 14 "SIGNALTAG_FCT_ERROR" 15 "Sendefunktion nicht in Betrieb";
VAL_ 629 CTR_LED_NAD_TIR_2_PSR 0 "No control of the LEDs" 1 "Blinken" 2 "Flashen" 3 "Send function not in operation";
VAL_ 629 CTR_LED_NAD_TIR_3_PSR 0 "No control of the LEDs" 1 "Blinken" 2 "Flashen" 3 "Send function not in operation";
VAL_ 629 CTR_LED_NAD_BOOT_FNS_PSR 0 "Keine Ansteuerung des LEDs" 1 "Blinken" 2 "Flashen" 3 "Send function not in operation";
VAL_ 708 OIT 253 "SIGNALTAG_FCTIF_NOT_AVAILABLE" 254 "SIGNALTAG_FCT_ERROR" 255 "Send function not in operation";
VAL_ 708 EDA_AVL_PO_ID 0 "Code 0" 1 "Code 1" 2 "Code 2" 3 "Code 3" 4 "Code 4" 63 "Signal ungültig";
VAL_ 708 ECO_TIPS_MSA 0 "Kein Tipp" 1 "Relevant für Handschalter" 2 "Relevant für Automatikgetriebe" 3 "Signal ungültig";
VAL_ 708 FU_RNG_DISP_DEAC 0 "Keine Reaktion" 1 "Kraftstoffreichweite deaktivieren" 3 "Signal ungültig";
VAL_ 708 EL_RNG_DISP_DEAC 0 "Keine_Reaktion" 1 "Elektrische_Reichweite_Temporaer_nicht_verfuegbar" 2 "Elektrische_Reichweite_deaktivieren" 3 "Sendefunktion nicht in Betrieb";
VAL_ 171 ST_DEPLOY_AB 0 "Kein Airbag ausgelöst" 1 "Mindestens ein Airbag ausgelöst" 3 "Signal ungültig";
VAL_ 171 ST_THRV_ACLN 1 "Beschleunigungsschwelle nicht überschritten" 2 "Beschleunigungsschwelle überschritten" 3 "Signal ungültig";
VAL_ 171 ST_CRSE_FRT 0 "Kein Crash" 1 "Crashschwere 1" 2 "Crashschwere 2" 3 "Crashschwere 3" 4 "Crashschwere 4" 13 "SIGNALTAG_FCTIF_NOT_AVAILABLE" 14 "SIGNALTAG_FCT_ERROR" 15 "Sendefunktion nicht in Betrieb";
VAL_ 171 ST_CRSE_SIDE_RH 0 "Kein Crash" 1 "Crashschwere 1" 2 "Crashschwere 2" 3 "Crashschwere 3" 4 "Crashschwere 4" 13 "SIGNALTAG_FCTIF_NOT_AVAILABLE" 14 "SIGNALTAG_FCT_ERROR" 15 "Sendefunktion nicht in Betrieb";
VAL_ 171 ST_CRSE_SIDE_LH 0 "Kein Crash" 1 "Crashschwere 1" 2 "Crashschwere 2" 3 "Crashschwere 3" 4 "Crashschwere 4" 13 "SIGNALTAG_FCTIF_NOT_AVAILABLE" 14 "SIGNALTAG_FCT_ERROR" 15 "Sendefunktion nicht in Betrieb";
VAL_ 171 ST_CRSE_REAR 0 "Kein Crash" 1 "Crashschwere 1" 2 "Crashschwere 2" 3 "Crashschwere 3" 4 "Crashschwere 4" 13 "SIGNALTAG_FCTIF_NOT_AVAILABLE" 14 "SIGNALTAG_FCT_ERROR" 15 "Sendefunktion nicht in Betrieb";
VAL_ 171 ST_CRSE_ROV 0 "Kein Crash" 1 "Crashschwere 1" 2 "Crashschwere 2" 3 "Crashschwere 3" 4 "Crashschwere 4" 13 "SIGNALTAG_FCTIF_NOT_AVAILABLE" 14 "SIGNALTAG_FCT_ERROR" 15 "Sendefunktion nicht in Betrieb";
VAL_ 171 ST_CRSE_PED 0 "Kein Crash" 1 "Crashschwere 1" 2 "Crashschwere 2" 3 "Crashschwere 3" 4 "Crashschwere 4" 13 "SIGNALTAG_FCTIF_NOT_AVAILABLE" 14 "SIGNALTAG_FCT_ERROR" 15 "Sendefunktion nicht in Betrieb";
VAL_ 171 ST_DMG_HV_SYS 0 "Kein Crash" 1 "Schwere 1" 2 "Schwere 2" 3 "Schwere 3" 4 "Schwere 4" 13 "SIGNALTAG_FCTIF_NOT_AVAILABLE" 14 "SIGNALTAG_FCT_ERROR" 15 "Sendefunktion nicht in Betrieb";
VAL_ 171 StatusCrashSeverityLevelFrontEnv 0 "No Crash" 1 "PreCrash basiert auf Umfeld Information, VoCSF" 2 "CSFUmSe_EE" 3 "VoCSF gefolgt von CSFUmSe_EE" 4 "CSFUmSe1" 5 "VoCSF gefolgt von CSFUmSe1" 6 "CSFUmSe_EE und CFSUmSe1" 7 "VoCSF gefolgt von CSFUmSe_EE und CSFUmSe1" 8 "CSFUmSe2" 9 "VoCSF gefolgt von CSFUmSe2" 10 "CSFUmSe_EE und CFSUmSe2" 11 "VoCSF gefolgt von CSFUmSe_EE und CSFUmSe2" 13 "SIGNALTAG_FCTIF_NOT_AVAILABLE" 14 "SIGNALTAG_FCT_ERROR" 15 "Sendefunktion nicht in Betrieb";
VAL_ 171 StatusCrashSeverityLevelRearEnvi 0 "No Crash" 1 "PreCrash basiert auf Umfeldinformation, VoCSH" 2 "CSHUmSe_EE" 3 "VoCSH gefolgt von CSHUmSe_EE" 4 "CSHUmSe1" 5 "VoCSH verfolgt von CSHUmSe1" 6 "CSHUmSe_E_E_und_CSHUmSe1" 7 "VoCSH verfolgt von CSHUmSe_EE und CSHUmSe1" 13 "SIGNALTAG_FCTIF_NOT_AVAILABLE" 14 "SIGNALTAG_FCT_ERROR" 15 "Sendefunktion nicht in Betrieb";
VAL_ 171 StatusCrashSeverityLevelSideRigh 0 "No Crash" 1 "PreCrash basiert auf Umfeldinformation, VoCSR" 2 "CSRUmSe_EE" 3 "VoCSR gefolgt von CSRUmSe_EE" 4 "CSRUmSe1" 5 "VoCSR verfolgt von CSRUmSe1" 6 "CSRUmSe_E_E_und_CSRUmSe1" 7 "VoCSR verfolgt von CSRUmSe_EE und CSRUmSe1" 13 "SIGNALTAG_FCTIF_NOT_AVAILABLE" 14 "SIGNALTAG_FCT_ERROR" 15 "Sendefunktion nicht in Betrieb";
VAL_ 171 StatusCrashSeverityLevelSideLeft 0 "No Crash" 1 "PreCrash basiert auf Umfeldinformation" 2 "CSLUmSe_EE" 3 "VoCSL gefolgt von CSLUmSe_EE" 4 "CSLUmSe1" 5 "VoCSL verfolgt von CSLUmSe1" 6 "CSLUmSe_E_E_und_CSLUmSe1" 7 "VoCSL verfolgt von CSLUmSe_EE und CSLUmSe1" 13 "SIGNALTAG_FCTIF_NOT_AVAILABLE" 14 "SIGNALTAG_FCT_ERROR" 15 "Sendefunktion nicht in Betrieb";
VAL_ 943 ST_TZS_OFFS 253 "SIGNALTAG_FCTIF_NOT_AVAILABLE" 254 "Hinweis: Reserviert für funktionale Kennung Signal-Tag." 255 "Sendefunktion nicht in Betrieb";
VAL_ 943 ST_CHB_T_ADJU_AUTOMLY 0 "Checkbox_Zeiteinstellung_automatisch_nicht_aktiv" 1 "Checkbox_Zeiteinstellung_automatisch_aktiv" 2 "wird benutzt, falls sich ein oder mehrere andere Signale in dieser Botschaft ändern" 3 "Sendefunktion nicht in Betrieb";
VAL_ 943 ST_TZS_ID 252 "Der Wert in diesem Signal hat sich nicht geändert." 253 "SIGNALTAG_FCTIF_NOT_AVAILABLE" 254 "SIGNALTAG_FCT_ERROR" 255 "Sendefunktion nicht in Betrieb";
VAL_ 991 SLV_1_ST_DIAG_OBD_IMME_MUX 1 "Cal-ID (software calibration identification)" 2 "CVN (software calibration verification number)" 63 "Wird funktional nicht bedient.";
VAL_ 992 SLV_2_ST_DIAG_OBD_IMME_MUX 1 "Cal-ID (software calibration identification)" 2 "CVN (software calibration verification number)" 63 "Wird funktional nicht bedient.";
VAL_ 993 SLV_3_ST_DIAG_OBD_IMME_MUX 1 "Cal-ID (software calibration identification)" 2 "CVN (software calibration verification number)" 63 "Wird funktional nicht bedient.";
VAL_ 960 ST_DISP_BLTW_TIR_1_LH 0 "Insasse_nicht_gegurtet" 1 "Insasse_gegurtet" 2 "Sitz_nicht_belegt" 3 "Gurtwarnung_deaktiviert" 4 "Keine_Anzeige" 5 "Gurtwarnung_blinkt" 6 "Insasse_nicht_gegurtet_deaktiviert" 13 "SIGNALTAG_FCTIF_NOT_AVAILABLE" 14 "SIGNALTAG_FCT_ERROR" 15 "Sendefunktion nicht in Betrieb";
VAL_ 960 ST_DISP_BLTW_TIR_1_RH 0 "Insasse_nicht_gegurtet" 1 "Insasse_gegurtet" 2 "Sitz_nicht_belegt" 3 "Gurtwarnung_deaktiviert" 4 "Keine_Anzeige" 5 "Gurtwarnung_blinkt" 6 "Insasse_nicht_gegurtet_deaktiviert" 13 "SIGNALTAG_FCTIF_NOT_AVAILABLE" 14 "SIGNALTAG_FCT_ERROR" 15 "Sendefunktion nicht in Betrieb";
VAL_ 960 ST_DISP_BLTW_TIR_2_RH 0 "Insasse_nicht_gegurtet" 1 "Insasse_gegurtet" 2 "Sitz_nicht_belegt" 3 "Gurtwarnung_deaktiviert" 4 "Keine_Anzeige" 5 "Gurtwarnung_blinkt" 6 "Insasse_nicht_gegurtet_deaktiviert" 13 "SIGNALTAG_FCTIF_NOT_AVAILABLE" 14 "SIGNALTAG_FCT_ERROR" 15 "Sendefunktion nicht in Betrieb";
VAL_ 960 ST_DISP_BLTW_TIR_2_MID 0 "Insasse_nicht_gegurtet" 1 "Insasse_gegurtet" 2 "Sitz_nicht_belegt" 3 "Gurtwarnung_deaktiviert" 4 "Keine_Anzeige" 5 "Gurtwarnung_blinkt" 6 "Insasse_nicht_gegurtet_deaktiviert" 13 "SIGNALTAG_FCTIF_NOT_AVAILABLE" 14 "SIGNALTAG_FCT_ERROR" 15 "Sendefunktion nicht in Betrieb";
VAL_ 960 ST_DISP_BLTW_TIR_2_LH 0 "Insasse_nicht_gegurtet" 1 "Insasse_gegurtet" 2 "Sitz_nicht_belegt" 3 "Gurtwarnung_deaktiviert" 4 "Keine_Anzeige" 5 "Gurtwarnung_blinkt" 6 "Insasse_nicht_gegurtet_deaktiviert" 13 "SIGNALTAG_FCTIF_NOT_AVAILABLE" 14 "SIGNALTAG_FCT_ERROR" 15 "Sendefunktion nicht in Betrieb";
VAL_ 960 ST_DISP_BLTW_TIR_3_RH 0 "Insasse_nicht_gegurtet" 1 "Insasse_gegurtet" 2 "Sitz_nicht_belegt" 3 "Gurtwarnung_deaktiviert" 4 "Keine_Anzeige" 5 "Gurtwarnung_blinkt" 6 "Insasse_nicht_gegurtet_deaktiviert" 13 "SIGNALTAG_FCTIF_NOT_AVAILABLE" 14 "SIGNALTAG_FCT_ERROR" 15 "Sendefunktion nicht in Betrieb";
VAL_ 960 ST_DISP_BLTW_TIR_3_LH 0 "Insasse_nicht_gegurtet" 1 "Insasse_gegurtet" 2 "Sitz_nicht_belegt" 3 "Gurtwarnung_deaktiviert" 4 "Keine_Anzeige" 5 "Gurtwarnung_blinkt" 6 "Insasse_nicht_gegurtet_deaktiviert" 13 "SIGNALTAG_FCTIF_NOT_AVAILABLE" 14 "SIGNALTAG_FCT_ERROR" 15 "Sendefunktion nicht in Betrieb";
VAL_ 448 AVL_V_SPDM_2 4095 "Sendefunktion nicht in Betrieb";
VAL_ 448 UN_V_SPDM 0 "Einheit mph" 1 "Einheit kmh" 3 "Signal ungültig";
VAL_ 448 ST_DISP_PMA 0 "Die für die PMA-Anzeige benötigten Eingangssignale sind fehlerhaft." 1 "Die für die PMA-Anzeige benötigten Eingangssignale sind in Ordnung." 3 "Sendefunktion nicht in Betrieb";
VAL_ 448 AVAI_DISP_KI 0 "Ein Fehler in der Anzeige erkannt, keine optischen Anzeigen möglich" 1 "Akustische Ausgaben möglich" 2 "Optische Ausgaben möglich" 13 "Hinweis: Reserviert für funktionale Kennung Signal-Tag" 14 "Hinweis: Reserviert für funktionale Kennung Signal-Tag" 15 "Sendefunktion nicht in Betrieb";
VAL_ 448 ST_DISP_XCC 0 "Die für die DCC-, ACC- oder EDP-Anzeige benötigten Eingangssignale sind fehlerhaft" 1 "Im Kombi ist die die DCC-Anzeige über die Codierung aktiviert und benötigte Hardware dafür ist verfügbar" 2 "Im Kombi ist die DCC-, ACC-Anzeige über die Codierung aktiviert und die benötigte Hardware dafür ist verfügbar" 3 "Im Kombi ist die DCC-, ACC-, und EDP-Anzeige über die Codierung aktiviert und die benötigte Hardware dafür ist verfügbar" 4 "Die für die DCC-, ACC- oder EDP-Anzeige benötigten Eingangssignale sind in Ordnung" 13 "Hinweis: Reserviert für funktionale Kennung Signal-Tag" 14 "Hinweis: Reserviert für funktionale Kennung Signal-Tag" 15 "Sendefunktion nicht in Betrieb";
VAL_ 448 ST_DISP_HDC 0 "Die für die HDC-Anzeige benötigten Eingangssignale sind fehlerhaft" 1 "Im Kombi ist die HDC-Anzeige über die Codierung aktiviert und die benötigte Hardware dafür ist verfügbar" 4 "Die für die HDC-Anzeige benötigten Eingangssignale sind in Ordnung" 13 "Hinweis: Reserviert für funktionale Kennung Signal-Tag" 14 "Hinweis: Reserviert für funktionale Kennung Signal-Tag" 15 "Sendefunktion nicht in Betrieb";
VAL_ 448 ST_DISP_SD 0 "Die für die SLD-Anzeige benötigten Eingangssignale sind fehlerhaft" 1 "Im Kombi ist die SLD-Anzeige über die Codierung aktiviert und die benötigte Hardware dafür ist verfügbar" 4 "Die für die SLD-Anzeige benötigten Eingangssignale sind in Ordnung" 13 "Hinweis: Reserviert für funktionale Kennung Signal-Tag" 14 "Hinweis: Reserviert für funktionale Kennung Signal-Tag" 15 "Sendefunktion nicht in Betrieb";
VAL_ 448 ST_DISP_DRASY_LAG 0 "Die für die Querführungsanzeige-Anzeige benötigten Eingangssignale sind fehlerhaft" 1 "Im Kombi ist die Querführungsanzeige-Anzeige über die Codierung aktiviert, und die benötigte Hardware dafür ist verfügbar" 4 "Die für die Querführungsanzeige-Anzeige benötigten Eingangssignale sind in Ordnung" 13 "Hinweis: Reserviert für funktionale Kennung Signal-Tag" 14 "Hinweis: Reserviert für funktionale Kennung Signal-Tag" 15 "Sendefunktion nicht in Betrieb";
VAL_ 448 ST_DISP_ISA_2 0 "Die für die ISA-Anzeige benötigten Eingangssignale sind fehlerhaft." 1 "Im Kombi ist die ISA-Anzeige über die Codierung aktiviert und die benötigte Hardware dafür ist verfügbar." 2 "Im Kombi wird die Bedienerweiterung der ISA Funktion aktuell angezeigt." 4 "Die für die ISA-Anzeige benötigten Eingangssignale sind in Ordnung." 13 "Hinweis: Reserviert für funktionale Kennung Signal-Tag" 14 "Hinweis: Reserviert für funktionale Kennung Signal-Tag" 15 "Sendefunktion nicht in Betrieb";
VAL_ 448 ST_DISP_GAP_INFO_2 0 "Die für die AI-Anzeige benötigten Eingangssignale sind fehlerhaft" 1 "Im Kombi und HUD ist die Abstandsinfo-Anzeige über die Codierung aktiviert, die benötigte Hardware dafür ist verfügbar." 2 "Die Abstandsinfo ist aktiviert" 4 "Die für die AI-Anzeige benötigten Eingangssignale sind in Ordnung" 13 "Hinweis: Reserviert für funktionale Kennung Signal-Tag" 14 "Hinweis: Reserviert für funktionale Kennung Signal-Tag" 15 "Sendefunktion nicht in Betrieb";
VAL_ 448 ST_DISP_WBK 0 "Die für die WBK-Anzeige benötigten Eingangssignale sind fehlerhaft" 1 "Im Kombi und HUD ist die WBK-Anzeige über die Codierung aktiviert, und die benötigte Hardware ist verfügbar" 4 "Die für die WBK-Anzeige benötigten Eingangssignale sind in Ordnung" 13 "Hinweis: Reserviert für funktionale Kennung Signal-Tag" 14 "Hinweis: Reserviert für funktionale Kennung Signal-Tag" 15 "Sendefunktion nicht in Betrieb";
VAL_ 435 ST_RQ_ACTVN_DYNOMOD 0 "Defaultwert, keine Anforderung hinsichtlich Rollenmodus seitens Bediener" 1 "Seitens Bediener durch Tastendruck gesetzt" 3 "Signal ungültig";
VAL_ 435 ST_DISP_KI_M 0 "Keine Änderung in Kombi-Einstellung" 1 "Kombi-Einstellung mit Standard-View" 2 "Kombi-Einstellung mit Einstellung M-View" 3 "Kombi-Einstellung mit Einstellung M-View-Plus" 15 "Sendefunktion nicht in Betrieb";
VAL_ 435 ST_NO_CC_MESS_DISP 65535 "Sendefunktion nicht in Betrieb";
VAL_ 435 ST_DISP_WALI_AB 0 "AUS" 1 "Gelb" 2 "Rot" 3 "Signal ungültig";
VAL_ 435 ST_DISP_WALI_BLT 0 "AUS" 1 "Rot" 3 "Signal ungültig";
VAL_ 435 ST_DISP_WALI_ENG 0 "AUS" 1 "Gelb" 3 "Signal ungültig";
VAL_ 435 ST_DISP_IDLI_DSC 0 "AUS" 1 "Gelb" 3 "Signal ungültig";
VAL_ 100 ST_DRVG_RDI_DRV 1 "Fahrbereitschaft nicht hergestellt; kein Motorlauf als Standfunktion" 2 "Fahrbereitschaft (verbrennungsmotorisch und/oder elektrisch) hergestellt" 3 "Anforderung Fahrbereitschaft herstellen aus Signal Anforderung_Funktion_Antrieb (RQ_FN_DRV) erkannt; Fahrbereitschaft wird (verbrennungsmotorisch und/oder elektrisch) hergestellt, ist aber noch nicht verfügbar; Motor kann in diesem Zustand aus vorherigem Motorlauf als Standfunktion bereits laufen." 4 "Anforderung Motorlauf als Standfunktion aus Signal Anforderung_Funktion_Antrieb (RQ_FN_DRV) erkannt; Motorlauf als Standfunktion wird hergestellt, ist aber noch nicht verfügbar" 5 "Motorlauf als Standfunktion hergestellt" 13 "SIGNALTAG_FCTIF_NOT_AVAILABLE" 14 "Hinweis: Reserviert für funktionale Kennung Signal-Tag." 15 "Sendefunktion nicht in Betrieb";
VAL_ 707 MUT_ASRC 0 "Keine Stummschaltung" 1 "Stummschaltung Entertainment" 2 "Stummschaltung alle Audioquellen" 3 "Signal ungültig";
VAL_ 707 DSCO_CONN_BLUE 0 "Keine Aktion" 1 "Alle HFP-Bluetoothverbindungen trennen" 2 "Alle Bluetoothverbindungen trennen" 3 "Signal ungültig";
VAL_ 707 ECAL_ABRT_PERM 0 "Abbruch durch Benutzer nicht erlaubt" 1 "Abbruch durch Benutzer erlaubt" 3 "Signal ungültig";
VAL_ 707 ECAL_STDBY 0 "Abschalten der Klemme erlaubt" 1 "Abschalten der Klemme verboten" 3 "Signal ungültig";
VAL_ 707 AVLB_ERA_GLO_TST_MOD 0 "ERA_GLONASS_Tes_Mode_nicht_verfuegbar" 1 "ERA_GLONASS_Test_Mode_verfuegbar_aber_nicht_aktivierbar" 2 "ERA_GLONASS_Test_Mode_verfuegbar_aktivierbar_aber_nicht_aktiv" 3 "ERA_GLONASS_Test_Mode_verfuegbar_aktivierbar_aktiv" 15 "Sendefunktion nicht in Betrieb";
VAL_ 707 ERA_GLO_TST_MOD_ST 0 "Initialwert" 1 "Lautsprecher_und_Mikrofontest" 2 "Lautsprechertest" 3 "Mikrofontest" 4 "Tastertest" 5 "Fehler" 6 "Beendet" 7 "Nicht_aktiv" 15 "Sendefunktion nicht in Betrieb";
VAL_ 710 ST_CON_ELV 0 "ELV ist entriegelt" 1 "ELV hat den Verriegelungsvorgang initiiert, ist physikalisch aber noch nicht verriegelt." 2 "ELV ist verriegelt." 3 "ELV hat den Entriegelungsvorgang initiiert, ist physikalisch aber noch nicht entriegelt." 13 "SIGNALTAG_FCTIF_NOT_AVAILABLE" 14 "SIGNALTAG_FCT_ERROR" 15 "Sendefunktion nicht in Betrieb";
VAL_ 442 ST_LDREL_GEN 0 "Keine Entlastungsfkt. Aktiv / Rücknahme" 1 "iGR-High" 2 "SULEV-Fkt" 3 "Entlastung nach Motorstart" 4 "Rennstart mit oder ohne AGM Batterie" 5 "ELMOTENTL Hitze" 6 "ELMOTENTL Kälte" 7 "Entlastung Anfahrschwäche wie P66,P85" 8 "Übertemperatur Generator" 9 "Entlastung aus Sicherheitsgründen" 10 "Entlastung Begrenzung Lagerkräfte" 11 "Entlastung aus Komfortgründen" 12 "Entlastung aus funktionalen Gründen" 15 "Signal ungültig";
VAL_ 912 ST_HOSP_FN 0 "AC-Ladesteckerverriegelung beachtet Hospitality Funktion nicht." 1 "AC-Ladestecker wird bei Vollladung freigegeben." 15 "Sendefunktion nicht in Betrieb";
VAL_ 367 ST_GO_ID 255 "Sendefunktion nicht in Betrieb";
VAL_ 367 ST_GO_HND 255 "Sendefunktion nicht in Betrieb";
VAL_ 367 ST_GO 0 "INTERRUPTED" 1 "NOT_PLAYING" 2 "PLAYING" 3 "ERROR" 7 "Sendefunktion nicht in Betrieb";
VAL_ 407 OP_GWS_PUBU_S 0 "keine Betätigung" 1 "Taster S betätigt" 2 "Signal ungültig";
VAL_ 407 OP_GWS_PUBU_DRVLG 0 "keine Betätigung" 1 "Taster S+ betätigt" 2 "Taster S- betätigt" 3 "Signal ungültig";
VAL_ 407 OP_GWS_REL 0 "Keine Aktion" 1 "Drücken in Fahrtrichtung" 2 "Überdrücken in Fahrtrichtung" 3 "Ziehen entgegen Fahrtrichtung" 4 "Überziehen entgegen Fahrtrichtung" 5 "Nächst niedriger Gang" 6 "Nächst höherer Gang" 7 "Manuelle Gasse / Sportprogramm" 8 "Signal ungültig" 9 "Nach Initialisierung noch keine \"WH-Position\" erkannt" 15 "Signal ungültig";
VAL_ 407 OP_GWS_PUBU_PKG 0 "GWS Init bzw. kein Fahrerwunsch P" 1 "Fahrerwunsch P" 2 "Einfachfehler" 3 "Signal ungültig";
VAL_ 407 OP_GRSS_PK_1_2 0 "unbetätigt, Initialisierung" 1 "Parktaster 1 betätigt" 3 "Signal ungültig";
VAL_ 407 OP_GRSS_PK_2_2 0 "unbetätigt, Initialisierung" 1 "Parktaster 2 betätigt" 3 "Signal ungültig";
VAL_ 407 OP_GWS_PUBU_LOW_MOD 0 "Keine Zustandsänderung" 1 "Flankengesteuertes Umschalten von D nach L oder von L nach D durch Getriebe." 3 "Wie Normalbetrieb";
VAL_ 446 ALIV_ST_GZA_LH 15 "Signal ungültig";
VAL_ 446 ST_GZA_LH 0 "Kein Fehler" 1 "Temporärer Fehler vorhanden" 2 "Permanenter Fehler vorhanden" 3 "Signal ungültig";
VAL_ 471 ALIV_ST_GZA_RH 15 "Signal ungültig";
VAL_ 471 ST_GZA_RH 0 "Kein Fehler" 1 "Temporärer Fehler vorhanden" 2 "Permanenter Fehler vorhanden" 3 "Signal ungültig";
VAL_ 942 ST_BAL_HUD_3 0 "HUD Backlight abgeschaltet" 1 "HUD Backlight abgeschaltet" 2 "HUD Anzeigen vorhanden" 3 "Sendefunktion nicht in Betrieb";
VAL_ 942 ST_BRIG_OFFS_HUD_3 0 "Nur in Bedienrichtung verwenden" 1 "minimaler Helligkeitsoffset" 2 "Helligkeitsoffset Zwischenstufe" 3 "Helligkeitsoffset Zwischenstufe" 4 "Helligkeitsoffset Zwischenstufe" 5 "Helligkeitsoffset Zwischenstufe" 6 "Helligkeitsoffset Zwischenstufe" 7 "Helligkeitsoffset Zwischenstufe" 8 "Helligkeitsoffset Zwischenstufe" 9 "Helligkeitsoffset Zwischenstufe" 10 "Helligkeitsoffset Zwischenstufe" 11 "kein Helligkeitsoffset" 12 "Helligkeitsoffset Zwischenstufe" 13 "Helligkeitsoffset Zwischenstufe" 14 "Helligkeitsoffset Zwischenstufe" 15 "Helligkeitsoffset Zwischenstufe" 16 "Helligkeitsoffset Zwischenstufe" 17 "Helligkeitsoffset Zwischenstufe" 18 "Helligkeitsoffset Zwischenstufe" 19 "Helligkeitsoffset Zwischenstufe" 20 "Helligkeitsoffset Zwischenstufe" 21 "maximaler Helligkeitsoffset" 31 "Signal ungültig";
VAL_ 942 ST_HGAD_HUD_3 0 "Nur in Bedienrichtung verwenden" 1 "Bildlage Anschlag Unten" 2 "Bildlage Zwischenstufe" 3 "Bildlage Zwischenstufe" 4 "Bildlage Zwischenstufe" 5 "Bildlage Zwischenstufe" 6 "Bildlage Zwischenstufe" 7 "Bildlage Zwischenstufe" 8 "Bildlage Zwischenstufe" 9 "Bildlage Zwischenstufe" 10 "Bildlage Zwischenstufe" 11 "Bildlage Mitte" 12 "Bildlage Zwischenstufe" 13 "Bildlage Zwischenstufe" 14 "Bildlage Zwischenstufe" 15 "Bildlage Zwischenstufe" 16 "Bildlage Zwischenstufe" 17 "Bildlage Zwischenstufe" 18 "Bildlage Zwischenstufe" 19 "Bildlage Zwischenstufe" 20 "Bildlage Zwischenstufe" 21 "Bildlage Anschlag Oben" 31 "Sendefunktion nicht in Betrieb";
VAL_ 942 ST_SLCTN_RDOBUT_HUD 0 "Wird in M Fahrzeugen nicht verwendet." 1 "Wird in M Fahrzeugen nicht verwendet." 2 "In M Fahrzeugen Comfort" 3 "In M Fahrzeugen M Ansicht" 6 "Nur in Bedienrichtung verwenden" 7 "Sendefunktion nicht in Betrieb";
VAL_ 942 ST_ROTA_HUD 0 "Nur in Bedienrichtung verwenden" 1 "maximale Drehung gegen Uhrzeigersinn" 2 "Drehung Zwischenstufe" 3 "Drehung Zwischenstufe" 4 "Drehung Zwischenstufe" 5 "Drehung Zwischenstufe" 6 "Drehung Zwischenstufe" 7 "Drehung Zwischenstufe" 8 "Drehung Zwischenstufe" 9 "Drehung Zwischenstufe" 10 "Drehung Zwischenstufe" 11 "Mittelposition Bildlage" 12 "Drehung Zwischenstufe" 13 "Drehung Zwischenstufe" 14 "Drehung Zwischenstufe" 15 "Drehung Zwischenstufe" 16 "Drehung Zwischenstufe" 17 "Drehung Zwischenstufe" 18 "Drehung Zwischenstufe" 19 "Drehung Zwischenstufe" 20 "Drehung Zwischenstufe" 21 "maximale Drehung im Uhrzeigersinn" 31 "Funktion fehlerhaft";
VAL_ 942 ST_STAN_HUD 0 "Keine Darstellung im HUD" 1 "Darstellung im HUD" 2 "Darstellung im HUD" 3 "Darstellung im HUD" 6 "Nur in Bedienrichtung verwenden" 7 "Signal ungültig";
VAL_ 942 ST_S_DISP_HUD 0 "Nur in Bedienrichtung verwenden" 1 "Listeneintrag \"aus\"" 2 "Listeneintrag \"im SPORT-Modus\"" 3 "Listeneintrag \"in der S-Gasse\"" 4 "Listeneintrag \"in SPORT-Modus & S-Gasse\"" 5 "Listeneintrag \"permanent\"" 15 "Sendefunktion nicht in Betrieb";
VAL_ 942 StatusAdditionalDisplayHUD 0 "Keine_Aenderung" 1 "Listeneintrag \"aus\"" 2 "Listeneintrag \"Automatisch\"" 3 "Listeneintrag \"FAS Anzeige permanent\"" 4 "Listeneintrag \"Sport Anzeige permanent\"" 5 "Listeneintrag \"Xoffroad Anzeige permanent\"" 6 "Hinweis: Reserviert für funktionale Kennung Signal-Tag" 7 "Sendefunktion nicht in Betrieb";
VAL_ 832 ST_HVBT_PROTE_WU 0 "keine Aktion" 1 "Trigger HV-Batteryguard" 3 "Signal ungültig";
VAL_ 506 ST_VA_COOL_HVSTO 0 "Keine Aussage möglich" 1 "Kühlventil nicht bestromt" 2 "Kühlventil bestromt" 3 "Signal ungültig";
VAL_ 506 ST_ERR_LOKG_HVSTO 0 "Diagnose noch nicht abgelaufen" 1 "Kein Interlockfehler" 2 "Interlockfehler" 3 "Signal ungültig";
VAL_ 506 ST_DCSW_HVSTO 0 "OPN" 1 "PRECHRG" 2 "CLS" 3 "SNA";
VAL_ 506 ST_EMMOD_HVSTO 0 "Diagnose noch nicht abgelaufen" 1 "nicht aktiv" 2 "aktiv" 3 "Signal ungültig";
VAL_ 506 ST_WARN_ISL_BN_HV 0 "keine Aussage möglich" 1 "nicht aktiv" 2 "aktiv" 3 "Signal ungültig";
VAL_ 506 ST_CSOV_HVSTO 0 "ok" 1 "Kurzschluss nach Masse" 2 "Kurzschluss nach U_Bat" 3 "Leitungsbruch" 6 "Wird nur in der Gen2.0 bedient" 9 "Ventil lässt sich nicht schließen (klemmt)" 12 "Ventil lässt sich nicht öffnen (klemmt)" 15 "Signal ungültig";
VAL_ 506 AVL_TEMP_HVSTO_MIN 253 "Hinweis: Reserviert für funktionale Kennung Signal-Tag." 254 "Hinweis: Reserviert für funktionale Kennung Signal-Tag." 255 "Sendefunktion nicht in Betrieb";
VAL_ 506 AVL_TEMP_HVSTO_MAX 253 "Hinweis: Reserviert für funktionale Kennung Signal-Tag." 254 "Hinweis: Reserviert für funktionale Kennung Signal-Tag." 255 "Sendefunktion nicht in Betrieb";
VAL_ 613 EnergyPredictionDepartureTime 65533 "SIGNALTAG_FCTIF_NOT_AVAILABLE" 65534 "SIGNALTAG_FCT_ERROR" 65535 "Sendefunktion nicht in Betrieb";
VAL_ 613 EnergyPredictionSoeChargingTarge 65533 "SIGNALTAG_FCTIF_NOT_AVAILABLE" 65534 "SIGNALTAG_FCT_ERROR" 65535 "Sendefunktion nicht in Betrieb";
VAL_ 881 ST_ECO_FN_ECS_DXP 0 "ECO-Geschwindigkeitshinweis nicht aktiv" 1 "ECO-Geschwindigkeitshinweis aktiv" 3 "Signal ungültig";
VAL_ 881 ST_ECO_FN_FRSG_ASST_DXP 0 "Verzögerungshinweise nicht anzeigen" 1 "Verzögerungshinweise anzeigen" 3 "Signal ungültig";
VAL_ 881 ST_ECO_FN_ECT_DXP 0 "ECO Tipps nicht anzeigen" 1 "ECO Tipps anzeigen" 3 "Signal ungültig";
VAL_ 881 ST_ECO_VL_UN_THO_ECS_DXP 0 "km/h" 1 "mph" 3 "Signal ungültig";
VAL_ 881 AVAI_ECO_FN_FRSG_ASST_DXP 0 "VZA auskodiert, Checkbox in MMI nicht anzeigen" 1 "VZA verfügbar, Checkbox in MMI anzeigen" 2 "VZA verfügbar, Checkbox in MMI nicht anzeigen" 3 "Signal ungültig";
VAL_ 875 ST_ECO_FN_SAIL_DXP 0 "Segeln Aus" 1 "Segeln An" 3 "Signal ungültig";
VAL_ 875 ST_ECO_FN_MSA_DXP 0 "MSA wird bei Wechsel in ECO PRO INDIVUDIUAL nicht zwangsaktiviert." 1 "MSA wird bei Wechsel in ECO PRO INDIVUDIUAL zwangsaktiviert." 3 "Signal ungültig";
VAL_ 875 ST_S_FN_SHA_DXP 0 "Schaltassistent nicht aktiv" 1 "Schaltassistent aktiv" 15 "Signal ungültig";
VAL_ 875 ST_S_CLU_RPM_PA_DXP 1 "Normal (B)" 2 "Sport (S)" 3 "Race (SE)" 15 "Signal ungültig";
VAL_ 875 ST_S_CLUG_ENG_DXP 1 "Normal (B)" 2 "Sport (S)" 3 "Race (SE)" 15 "Signal ungültig";
VAL_ 875 ST_ADJU_SAIL_VEH 0 "Segeln_nicht_erlaubt" 1 "Segeln_erlaubt" 3 "Sendefunktion nicht in Betrieb";
VAL_ 875 StatusAdjustEngineSoundVehicle 0 "Initiale Einstellung" 1 "Motorsound_sportlich" 2 "Motorsound_komfortabel" 3 "Motorsound_zurueckhaltend" 4 "Nur in Bedienrichtung zu verwenden" 5 "Neu: Funktionswerte ID8" 6 "Neu: Funktionswerte ID8" 7 "Neu: Funktionswerte ID8" 8 "Neu: Funktionswerte ID8" 9 "Neu: Funktionswerte ID8 (z.B. Thrill)" 10 "Neu: Funktionswerte ID8" 13 "Reserviert für funktionale Kennung Signal-Tag" 14 "Reserviert für funktionale Kennung Signal-Tag" 15 "Sendefunktion nicht in Betrieb";
VAL_ 572 ST_SWO_IDT_CHGNG_CA 0 "Default Wert" 1 "IL-System hat Antennensignal ID-Geber erkannt und hat induktiv Laden unterbrochen" 2 "Acknowledge, dass IL aufgrund einer Anforderung des CA-Systems heruntergefahren wurde" 3 "Induktiv Laden aktiv keine Abbruch Anforderung durch CA-System empfangen" 13 "Hinweis: Reserviert für funktionale Kennung Signal-Tag." 14 "Hinweis: Reserviert für funktionale Kennung Signal-Tag." 15 "Sendefunktion nicht in Betrieb";
VAL_ 572 ST_POSI_IDT_CHGNG_CA 0 "Schlüsselsuche durchführen" 1 "Positionierung aktiv, Anforderung zur Ansteuerung der Antennen" 2 "Antennen aktiv, keine Schlüsselsuche durchführen" 3 "Ansteuerung der Antennen kann ausgeschaltet werden" 13 "Hinweis: Reserviert für funktionale Kennung Signal-Tag." 14 "Hinweis: Reserviert für funktionale Kennung Signal-Tag." 15 "Sendefunktion nicht in Betrieb";
VAL_ 656 ST_KEY_SRCH_INO 0 "Bei der letzten Schlüsselsuche innerhalb der letzten 5 Sekunden wurde kein Schlüssel im Innenraum gefunden." 1 "Es wurde keine erneute Schlüsselsuche innerhalb der letzten 5 Sekunden durchgeführt. Über die Anwesenheit des Schlüssels kann keine Aussage getroffen werden, da seit dem letzen Finden des Schlüssels im Innenraum mindestens eine Klappe (Tür, Heckklappe, Heckscheibe) geöffnet wurde, durch die der Schlüssel das Fahrzeug verlassen haben könnte." 2 "Es wurde keine erneute Schlüsselsuche innerhalb der letzten 5 Sekunden durchgeführt. Der Schlüssel kann den Innenraum durch ein offenes Fenster, offenes Verdeck, offenes Schiebedach verlassen haben, es ist aber nicht wahrscheinlich." 3 "Es wurde keine erneute Schlüsselsuche innerhalb der letzten 5 Sekunden durchgeführt. Der Schlüssel befindet sich im Innenraum, da sich seit dem letzten Finden des Schlüssels im Innenraum keine Tür, Heckklappe, Heckscheibe, Fenster, Verdeck, Schiebedach geöffnet hat und der Schlüssel somit das Fahrzeug nicht verlassen hat." 4 "Bei der letzten Schlüsselsuche innerhalb der letzten 5 Sekunden wurde ein Schlüssel im Innenraum gefunden." 13 "SIGNALTAG_FCTIF_NOT_AVAILABLE" 14 "SIGNALTAG_FCT_ERROR" 15 "Sendefunktion nicht in Betrieb";
VAL_ 656 ID_FN_RSLT_KEY_SRCH 0 "Das Ergebnis der Schlüssel-Suche wurde nicht auf Antwort auf eine Anfrage versendet, sondern aufgrund einer ereignisgesteuerten Versendung - ausgelöst durch das Öffnen einer Tür, Heckklappe, Heckscheibe, Fenster, Verdeck oder Schiebedach." 1 "Entertainmentmode - Zugriff auf persönliche Daten" 2 "Remote Controlled Parking" 3 "Entriegel/Verriegelvorgang" 4 "Motorweiterlauf" 253 "Hinweis: Reserviert für funktionale Kennung Signal-Tag." 254 "SIGNALTAG_FCT_ERROR" 255 "Sendefunktion nicht in Betrieb";
VAL_ 874 DISP_MAB_ASST 0 "Init" 1 "Anzeige Fernlichtassistent nicht aktiviert" 2 "Anzeige Fernlichtassistent aktiviert" 3 "Signal ungültig";
VAL_ 874 RQ_OP_MAB_ASST 0 "Init" 1 "Anforderung AUS" 2 "Anforderung EIN" 3 "Signal ungültig";
VAL_ 1070 ALIV_ST_MDRV_2 15 "Signal ungültig";
VAL_ 1070 ST_MDRV_2 0 "Ab SP2011 andere Bedeutung: Nicht Relevant für Teilsystem" 1 "Ab SP2011 andere Bedeutung: Relevant für Teilsysteme" 2 "Ab SP2011 andere Bedeutung: -" 3 "Signal ungültig";
VAL_ 1070 ST_MDRV_2_DSC 0 "Keine Änderung" 1 "DSC AUS" 2 "DSC EIN" 3 "DSC MDM" 15 "Signal ungültig";
VAL_ 1070 ST_MDRV_2_IDX 0 "Konfiguration für M-Drive-Taster 1";
VAL_ 1070 ST_MDRV_2_STG_GRB 0 "Keine Änderung" 1 "Stufe 1" 2 "Stufe 2" 3 "Stufe 3" 4 "Stufe 4" 5 "Stufe 5" 6 "BN2000: NUR wenn DSC AUS" 15 "Signal ungültig";
VAL_ 1070 ST_MDRV_2_ENG 0 "Keine Änderung" 1 "Komfort" 2 "Sport" 3 "Sport Plus" 15 "Signal ungültig";
VAL_ 1070 ST_MDRV_2_EDC 0 "keine Änderung" 1 "Komfort" 2 "Sport" 3 "Sport Plus" 15 "Signal ungültig";
VAL_ 1070 ST_MDRV_2_EPAS 0 "keine Änderung" 1 "Komfort" 2 "Sport" 3 "Sport Plus" 15 "Signal ungültig";
VAL_ 1070 ST_MDRV_2_DISP_HUD 0 "Keine Änderung" 1 "M-spezifische Darstellung" 2 "AG-Darstellung" 3 "Gilt ab SP2015" 15 "Signal ungültig";
VAL_ 1070 ST_MDRV_2_DISP_SHLI 0 "Keine Änderung" 1 "Shiftlights AUS" 2 "Shiftlights EIN" 15 "Signal ungültig";
VAL_ 1070 ST_MDRV_2_MOD_GRB 0 "Keine Änderung" 1 "Automatic" 2 "Sequentiell" 7 "Signal ungültig";
VAL_ 1070 RQ_AUDM_MDRV_2 0 "Keine Tonanforderung" 1 "Der Ton 1 wird derzeit nicht verwendet." 2 "Wenn die Konfiguration mit langdruck der M-Taste (1/2) übernommen wurde, wird ein Akustiksignal angefordert." 3 "Signal ungültig";
VAL_ 1070 ST_MDRV_2_AW 0 "Allradmodus 4WD Standard" 1 "Allradmodus 4WD Alternativ" 2 "Allradmodus 2WD" 3 "Allradmodus hat sich nicht verändert." 7 "Sendefunktion nicht in Betrieb";
VAL_ 1029 ST_MDRV_3_IDX 0 "M1 Konfiguration" 1 "M2 Konfiguration" 3 "Keine Konfiguration" 15 "Sendefunktion nicht in Betrieb";
VAL_ 1029 ST_MDRV_3_DRVGMOD 0 "Keine Aenderung" 1 "Fahrmodus 1" 2 "Fahrmodus 2" 3 "Fahrmodus 3" 15 "Sendefunktion nicht in Betrieb";
VAL_ 1029 ST_MDRV_3 0 "Nachricht nicht für Teilsystem relevant" 1 "Nachricht für Teilsystem relevant" 3 "Sendefunktion nicht in Betrieb";
VAL_ 1029 ST_MDRV_3_DISP_KI_HUD 0 "Keine Aenderung" 1 "Standard Ansicht in HUD" 2 "M-View Ansicht in HUD" 3 "M-View-Plus Ansicht in HUD" 8 "Standard Ansicht im Kombi" 16 "M-View Ansicht im Kombi" 24 "M-View-Plus Ansicht im Kombi" 63 "Sendefunktion nicht in Betrieb";
VAL_ 1029 ST_MDRV_3_SOU 0 "Keine Aenderung" 1 "Soundtaster Modus auf Leise aus" 2 "Soundtaster Modus auf Leise an" 3 "Sendefunktion nicht in Betrieb";
VAL_ 1029 ST_MDRV_3_MSA 0 "Keine Aenderung" 1 "MSA Modus ist aus" 2 "MSA Modus ist an" 3 "Sendefunktion nicht in Betrieb";
VAL_ 1029 ST_MDRV_3_ASR 0 "Keine Aenderung" 1 "ASR Modus ist aus" 2 "ASR Modus ist an" 3 "Sendefunktion nicht in Betrieb";
VAL_ 1029 ST_MDRV_3_MUT 0 "Keine Aenderung" 1 "Stummschaltung nicht aktiv" 2 "Stummschaltung aktiv" 3 "Sendefunktion nicht in Betrieb";
VAL_ 1029 ST_MDRV_3_SAR 0 "Keine Aenderung" 1 "SARAH in AG Betriebsmodus" 2 "SARAH in Individual Modus" 3 "SARAH in ALL OFF Modus" 13 "SIGNALTAG_FCTIF_NOT_AVAILABLE" 14 "SIGNALTAG_FCT_ERROR" 15 "Sendefunktion nicht in Betrieb";
VAL_ 1029 ST_MDRV_3_AMB 0 "Keine Aenderung" 1 "Ambilight in M-Farbmodus 1" 2 "Ambilight in M-Farbmodus 2" 3 "Ambilight in M-Farbmodus 3" 13 "SIGNALTAG_FCTIF_NOT_AVAILABLE" 14 "SIGNALTAG_FCT_ERROR" 15 "Sendefunktion nicht in Betrieb";
VAL_ 1029 ST_MDRV_3_HAZW 0 "Keine Aenderung" 1 "Gefahrenwarnblinken nicht unterbinden" 2 "Gefahrenwarnblinken unterbinden" 3 "Sendefunktion nicht in Betrieb";
VAL_ 1029 ST_MDRV_3_RECW 0 "Keine Aenderung" 1 "Auffahrwarnung Heck nicht unterbinden" 2 "Auffahrwarnung Heck unterbinden" 3 "Sendefunktion nicht in Betrieb";
VAL_ 1029 ST_MDRV_3_CF_FAS 0 "Keine Aenderung" 1 "Comfort FAS freigegeben" 2 "Comfort FAS abschalten und nicht sperren" 3 "Comfort FAS abschalten und sperren" 13 "SIGNALTAG_FCTIF_NOT_AVAILABLE" 14 "SIGNALTAG_FCT_ERROR" 15 "Sendefunktion nicht in Betrieb";
VAL_ 1029 ST_MDRV_3_BRPD 0 "Keine_Aenderung" 1 "Kennlinie_1" 2 "Kennlinie_2" 3 "Kennlinie_3" 15 "Sendefunktion nicht in Betrieb";
VAL_ 1029 StatusMDrive3MControlPlusDrift 0 "Nicht_genutzt" 1 "DFT_aus_MCP_aus" 2 "DFT_an_MCP_aus" 3 "DFT_aus_MCP_an" 13 "SIGNALTAG_FCTIF_NOT_AVAILABLE" 14 "SIGNALTAG_FCT_ERROR" 15 "Sendefunktion nicht in Betrieb";
VAL_ 1029 StatusMDrive3DriftSupportLevel 0 "Nicht_genutzt" 1 "Assistenz_Level_0" 2 "Assistenz_Level_1" 3 "Assistenz_Level_2" 4 "Assistenz_Level_3" 5 "Assistenz_Level_4" 6 "Assistenz_Level_5" 7 "Assistenz_Level_6" 8 "Assistenz_Level_7" 9 "Assistenz_Level_8" 10 "Assistenz_Level_9" 11 "Assistenz_Level_10" 13 "SIGNALTAG_FCTIF_NOT_AVAILABLE" 14 "SIGNALTAG_FCT_ERROR" 15 "Sendefunktion nicht in Betrieb";
VAL_ 1029 StatusMDrive3MControlPlusTractio 0 "Nicht_genutzt" 1 "Traktion_Level_0" 2 "Traktion_Level_1" 3 "Traktion_Level_2" 4 "Traktion_Level_3" 5 "Traktion_Level_4" 6 "Traktion_Level_5" 7 "Traktion_Level_6" 8 "Traktion_Level_7" 9 "Traktion_Level_8" 10 "Traktion_Level_9" 11 "Traktion_Level_10" 13 "SIGNALTAG_FCTIF_NOT_AVAILABLE" 14 "SIGNALTAG_FCT_ERROR" 15 "Sendefunktion nicht in Betrieb";
VAL_ 1029 StatusMDrive3MControlPlusBrakeBa 0 "Nicht_genutzt" 1 "Bremsbalance_Level_0" 2 "Bremsbalance_Level_1" 3 "Bremsbalance_Level_2" 4 "Bremsbalance_Level_3" 5 "Bremsbalance_Level_4" 6 "Bremsbalance_Level_5" 7 "Bremsbalance_Level_6" 8 "Bremsbalance_Level_7" 9 "Bremsbalance_Level_8" 10 "Bremsbalance_Level_9" 11 "Bremsbalance_Level_10" 13 "SIGNALTAG_FCTIF_NOT_AVAILABLE" 14 "SIGNALTAG_FCT_ERROR" 15 "Sendefunktion nicht in Betrieb";
VAL_ 1199 ST_CON_VEH_DBG 1 "Parken_BN_niO" 2 "Parken_BN_iO" 3 "Standfunktionen_Kunde_nicht_im_FZG" 5 "Wohnen" 7 "Pruefen_Analyse_Diagnose" 8 "Fahrbereitschaft_herstellen" 10 "Fahren" 12 "Fahrbereitschaft_beenden" 15 "Sendefunktion nicht in Betrieb";
VAL_ 1199 ST_CON_VEH_PING_DBG 1 "Parken_BN_niO" 2 "Parken_BN_iO" 3 "Standfunktionen_Kunde_nicht_im_FZG" 5 "Wohnen" 7 "Pruefen_Analyse_Diagnose" 8 "Fahrbereitschaft_herstellen" 10 "Fahren" 12 "Fahrbereitschaft_beenden" 15 "Sendefunktion nicht in Betrieb";
VAL_ 1199 ST_CON_VEH_OD 1 "Parken_BN_niO" 2 "Parken_BN_iO" 3 "Standfunktionen_Kunde_nicht_im_FZG" 5 "Wohnen" 7 "Pruefen_Analyse_Diagnose" 8 "Fahrbereitschaft_herstellen" 10 "Fahren" 12 "Fahrbereitschaft_beenden" 15 "Sendefunktion nicht in Betrieb";
VAL_ 1199 ST_FTF_MOD 0 "Normal-Modus" 1 "Fertigung-Modus" 2 "Transport-Modus" 3 "Signal_unbefuellt";
VAL_ 1199 ST_SHR_MOD 0 "Messemodus inaktiv" 1 "Messemodus aktiv" 3 "Signal_unbefuellt";
VAL_ 1199 ST_END_DRVG_DBG 0 "Zustand_Fahren_wurde_nicht_beendet" 1 "Fahren_wurde_durch_SST_beendet" 2 "Fahren_wurde_durch_System_beendet" 3 "Zustand_Fahren_war_nicht_aktiv_seit_letztem_Wohnen" 4 "Fahren_wurde_durch_Dienst_beendet" 5 "Fahren_wurde_durch_Diagnose_beendet" 14 "Nicht_verfuegbar" 15 "Sendefunktion nicht in Betrieb";
VAL_ 1199 ST_OCC_GTOU 0 "Parken_o_SF" 1 "Wohnen_beenden" 2 "nur_Fahrer_anwesend" 3 "nur_Beifahrer_anwesend" 5 "Fahrer_und_Beifahrer_anwesend" 7 "Fahren" 15 "Sendefunktion nicht in Betrieb";
VAL_ 1199 ST_CTG_SPFN_DBG 0 "Keine Sonderfunktion" 1 "Telefonie" 2 "Bewegtes Bild" 4 "Internet/A4A/TUI" 8 "KISU_RSU" 16 "Carsharing" 32 "Gesetzliche_Anforderung_Abblendlicht" 65535 "Sendefunktion nicht in Betrieb";
VAL_ 1199 ST_VEH_CON_TIM 0 "Timer nicht aktiv / abgelaufen" 1 ">=0 min" 2 ">=1 min" 3 ">=2 min" 4 ">=3 min" 5 ">=4 min" 6 ">=9 min" 7 ">=11min" 9 ">=19 min" 12 ">=29 min" 13 ">=59 min" 14 "Dauer ein" 15 "Sendefunktion nicht in Betrieb";
VAL_ 1199 ST_KL_30B_SWOT 0 "Timer nicht aktiv / abgelaufen" 1 ">=0 min" 2 ">=1 min" 3 ">=2 min" 4 ">=3 min" 5 ">=4 min" 6 ">=9 min" 7 ">=11min" 9 ">=19 min" 12 ">=29 min" 13 ">=59 min" 14 "Dauer ein" 15 "Sendefunktion nicht in Betrieb";
VAL_ 1199 ST_KL_30B_NSOT 0 "Timer nicht aktiv / abgelaufen" 1 ">=0 min" 2 ">=1 min" 3 ">=2 min" 4 ">=3 min" 5 ">=4 min" 6 ">=9 min" 7 ">=11min" 9 ">=19 min" 12 ">=29 min" 13 ">=59 min" 14 "Dauer ein" 15 "Sendefunktion nicht in Betrieb";
VAL_ 1199 ST_PFN_TMOUT 0 "Timer nicht aktiv / abgelaufen" 1 ">=0 min" 2 ">=1 min" 3 ">=2 min" 4 ">=3 min" 5 ">=4 min" 6 ">=9 min" 7 ">=11min" 9 ">=19 min" 12 ">=29 min" 13 ">=59 min" 14 "Dauer ein" 15 "Sendefunktion nicht in Betrieb";
VAL_ 1199 ST_VEH_IACTN_TRANS 1 "Wohnen_durch_Betätigung_Schiebehebedach-Taster_PWF_MASTER_544" 2 "Wohnen_durch_Betätigung_des_Innenlichttasters_PWF_MASTER_126" 3 "Wohnen_durch_Betätigung_Cabrioverdeck-Taster_PWF_MASTER_553" 4 "Wohnen_durch_Betätigung_Lenkstockhebel_links_PWF_MASTER_560" 5 "Wohnen_durch_Betätigung_Fernlicht-Assistent-Taste_PWF_MASTER_564" 6 "Wohnen_durch_Betätigung_Lenkstockhebel_rechts_PWF_MASTER_565" 7 "Wohnen_durch_Betätigung_Drehschalter_Licht_PWF_MASTER_570" 8 "Wohnen_durch_Betätigung_Nebelscheinwerfer_PWF_MASTER_571" 9 "Wohnen_durch_Betätigung_Nebelschlussleuchte_PWF_MASTER_572" 10 "Wohnen_durch_Betätigung_Leuchtweitenregulierung_PWF_MASTER_559" 11 "Wohnen_durch_Bedienen_eines_Fensterhebers_PWF_MASTER_500" 12 "Wohnen_durch_Betätigung_Rollo-Tasten_PWF_MASTER_573" 13 "Wohnen_durch_Betätigung_Spiegelverstellung_PWF_MASTER_574" 14 "Wohnen_durch_Betätigung_Spiegel-Beiklappen_PWF_MASTER_575" 17 "Wohnen_durch_Bedienen_des_Sarah-Tasters_PWF_MASTER_497" 18 "Wohnen_durch_Betätigung_Modus-Taste_PWF_MASTER_379" 19 "Wohnen_durch_Betätigung_Eject-Button_PWF_MASTER_377" 20 "Wohnen_durch_Betätigung_AM_FM_Verkehrsinformationen-Taste_PWF_MASTER_380" 21 "Wohnen_durch_Betätigung_Functional-Bookmark-Taste_PWF_MASTER_381" 24 "Wohnen_durch_Betätigung_einer_BE_MIKO-Taste_PWF_MASTER_628" 25 "Wohnen_durch_Betätigung_Heckspoiler-Taster_PWF_MASTER_549" 26 "Wohnen_durch_Betätigung_MSA-Taster_PWF_MASTER_552" 27 "Wohnen_durch_Betätigung_ZBE-Taste_Front_PWF_MASTER_382" 28 "Wohnen_durch_Betätigung_ZBE-Taste_Fond_PWF_MASTER_414" 29 "Wohnen_durch_Schieben_des_ZBE-Drehstellers_Front_PWF_MASTER_383" 30 "Wohnen_durch_Schieben_des_ZBE-Drehstellers_Fond_PWF_MASTER_415" 31 "Wohnen_durch_Drehen_des_ZBE-Drehstellers_Front_PWF_MASTER_384" 32 "Wohnen_durch_Drehen_des_ZBE-Drehstellers_Fond_PWF_MASTER_416" 33 "Wohnen_durch_Betätigung_Lautstärke-Wippe_PWF_MASTER_554" 34 "Wohnen_durch_Betätigung_Toggle-Taste_PWF_MASTER_555" 35 "Wohnen_durch_Betätigung_Menu-Walze_PWF_MASTER_556" 36 "Wohnen_durch_Betätigung_Telefon-Taste_PWF_MASTER_557" 37 "Wohnen_durch_Betätigung_Push-to-talk-Taste_PWF_MASTER_558" 38 "Wohnen_durch_Betätigung_Start-Stopp-Taster_PWF_MASTER_104" 39 "Wohnen_durch_Betätigung_Entertainment-Button_(Kurzdruck)_PWF_MASTER_378" 40 "Wohnen_durch_Betätigung_Zentralverriegelungstaster/-wippe_PWF_MASTER_625" 41 "Wohnen_durch_Betätigung_Motorhaube_PWF_MASTER_124" 42 "Standfunktion_durch_Betätigung_Motorhaube_PWF_MASTER_124" 43 "Wohnen_durch_Änderung_des_Heckklappenkontakts_PWF_MASTER_114" 44 "Wohnen_durch_Änderung_des_Heckscheibenkontakts_PWF_MASTER_115" 45 "Wohnen_durch_Betätigung_des_Heckscheibentasters_PWF_MASTER_116" 46 "Wohnen_durch_Betätigung_des_Heckklappentasters_PWF_MASTER_117" 47 "Wohnen_durch_Betätigung_des_Sichern-Schalters_an_der_Heckklappe_PWF_MASTER_125" 48 "Wohnen_durch_Betätigung_Funkschlüssel_PWF_MASTER_118" 49 "Wohnen_durch_ZV_entriegeln_PWF_MASTER_221" 50 "Wohnen_durch_Öffnen_oder_Schließen_der_Fahrertür_hinten_PWF_MASTER_109" 51 "Wohnen_durch_Öffnen_oder_Schließen_der_Beifahrertür_hinten_PWF_MASTER_110" 52 "Wohnen_durch_Schließen_der_Fahrertür_PWF_MASTER_650" 53 "Wohnen_durch_Schließen_der_Beifahrertür_PWF_MASTER_651" 54 "Wohnen_durch_RCP-TasteBedienen_PWF_MASTER_652" 55 "Wohnen_durch_Öffnen_der_Fahrertür_PWF_MASTER_107" 56 "Wohnen_durch_Öffnen_der_Beifahrertür_PWF_MASTER_108" 57 "Parken_durch_ZV_sichern_PWF_MASTER_130" 58 "Standfunktion_durch_ZV_sichern_PWF_MASTER_130" 59 "Fahren_durch_Fahrbereitschaft_hergestellt_PWF_MASTER_132" 60 "Fahrbereitschaft_beenden_durch_Fahrbereitschaft_beendet_PWF_MASTER_275" 61 "Pruefen_Analyse_Diagnose_durch_Analyse_starten_PWF_MASTER_134" 62 "Wohnen_durch_Analyse_beenden_PWF_MASTER_285" 63 "Fahrbereitschaft_herstellen_durch_Fahrwunsch_erkannt_PWF_MASTER_136" 64 "Wohnen_durch_Fahrwunsch_zurueckgenommen_PWF_MASTER_278" 65 "Fahrbereitschaft_beenden_durch_Fahrwunsch_zurueckgenommen_PWF_MASTER_278" 66 "Standfunktion_durch_Timeout_Wohnen_Kunde_anwesend_PWF_MASTER_145" 67 "Parken_BN_iO_durch_Timeout_Kunde_abwesend_abgelaufen_PWF_MASTER_146" 68 "Standfunktion_durch_Nachladegrenze_erreicht_PWF_MASTER_507" 69 "Parken_BN_niO_durch_Bordnetzfehler_erkannt_PWF_MASTER_238" 70 "Parken_BN_iO_durch_Pruefung_BN_Fehler_Weckerdiagnose_PWF_MASTER_534_1479" 71 "Parken_BN_niO_durch_TimeOutTransportModus_PWF_MASTER_412" 72 "Wohnen_durch_Erstes_Oeffnen_FAT_nach_Fahrt_PWF_MASTER_493" 73 "Standfunktion_durch_Abschaltung_durch_Kunden_PWF_MASTER_517" 74 "Standfunktion_durch_Insassenausstieg_PWF_MASTER_629" 75 "Standfunktion_durch_OSFG_erreicht_PWF_MASTER_200" 76 "Standfunktion_durch_Virtuelle_Batterie_entleert_PWF_MASTER_532" 77 "Standfunktion_durch_Standfunktion_aktiv_PWF_MASTER_196" 78 "Standfunktion_durch_Änderung_des_Heckklappenkontakts_PWF_MASTER_114" 79 "Standfunktion_durch_Änderung_des_Heckscheibenkontakts_PWF_MASTER_115" 80 "Standfunktion_durch_Betätigung_des_Heckscheibentasters_PWF_MASTER_116" 81 "Standfunktion_durch_Betätigung_des_Heckklappentasters_PWF_MASTER_117" 82 "Standfunktion_durch_Betätigung_des_Sichern-Schalters_an_der_Heckklappe_PWF_MASTER_125" 83 "Standfunktion_durch_FunkschlüsselBedienen_PWF_MASTER_118" 84 "Standfunktion_durch_ZV_entriegeln_PWF_MASTER_221" 85 "Standfunktion_durch_Öffnen_oder_Schließen_der_Fahrertür_hinten_PWF_MASTER_109" 86 "Standfunktion_durch_Öffnen_oder_Schließen_der_Beifahrertür_hinten_PWF_MASTER_110" 87 "Standfunktion_durch_Schließen_der_Fahrertür_PWF_MASTER_650" 88 "Standfunktion_durch_Schließen_der_Beifahrertür_PWF_MASTER_651" 89 "Standfunktion_durch_RCP-TasteBedienen_PWF_MASTER_652" 90 "Parken_BN_niO_durch_Diagnose_PWF_MASTER_403" 91 "Parken_BN_iO_durch_Diagnose_PWF_MASTER_403" 92 "Standfunktion_durch_Diagnose_PWF_MASTER_403" 93 "Wohnen_durch_Diagnose_PWF_MASTER_403" 94 "Pruefen_Analyse_Diagnose_durch_Diagnose_PWF_MASTER_403" 97 "Fahrbereitschaft_beenden_durch_Diagnose_PWF_MASTER_403" 98 "Parken_BN_niO_durch_Dienst_PWF_MASTER_430" 99 "Parken_BN_iO_durch_Dienst_PWF_MASTER_430" 100 "Standfunktion_durch_Dienst_PWF_MASTER_430" 101 "Wohnen_durch_Dienst_PWF_MASTER_430" 106 "Wohnen_durch_beenden_Fahrbereitschaft" 107 "Wohnen_durch_Klemme15HW_PWF_MASTER_750" 108 "Wohnen_durch_Betätigung_Heckklappentaster_Fußraum_Fahrer_PWF_MASTER_744" 109 "Gilt ab SP2018" 110 "Gilt ab SP2018" 111 "Gilt ab SP2018" 112 "Gilt ab SP2018" 113 "Gilt ab SP2018" 114 "Gilt ab SP2018" 115 "Gilt ab SP2018" 116 "Gilt ab SP2021" 117 "Gilt ab SP2021" 118 "Gilt ab SP2018" 119 "Gilt ab SP2018" 255 "Sendefunktion nicht in Betrieb";
VAL_ 1089 ST_TIM_OSFG 0 "Timer_nicht_aktiv_abgelaufen" 1 "Groesser_gleich_0_sec" 2 "Groesser_gleich_1_sec" 3 "Groesser_gleich_2_sec" 4 "Groesser_gleich_3_sec" 5 "Groesser_gleich_4_sec" 6 "Groesser_gleich_9_sec" 7 "Groesser_gleich_10_sec" 9 "Groesser_gleich_15_sec" 12 "Groesser_gleich_19_sec" 13 "Groesser_gleich_29_sec" 14 "Groesser_gleich_49_sec" 15 "Sendefunktion nicht in Betrieb";
VAL_ 1089 ST_CODG_LVG 0 "1_Min" 1 "3_Min" 2 "5_Min" 3 "10_Min" 4 "20_Min" 5 "30_Min" 6 "60_Min" 15 "Sendefunktion nicht in Betrieb";
VAL_ 1089 ST_CODG_PFN 0 "100_ms" 1 "1_s" 2 "1_Min" 3 "3_Min" 15 "Sendefunktion nicht in Betrieb";
VAL_ 1089 ST_CON_FB_TRM 0 "Motorstillstand" 1 "Getriebe_in_N" 2 "Kein_Fahrzeugstillstand" 4 "Kein_Motorstillstand" 15 "Sendefunktion nicht in Betrieb";
VAL_ 1089 ST_RQ_TN_DM 1 "Domaene_Verbrennungsmotor" 2 "Domaene_Elektromotor" 4 "Domaene_48V" 8 "Domaene_Fahrwerk" 16 "Domaene_Karosserie" 32 "Domaene_Unterhaltung" 255 "Sendefunktion nicht in Betrieb";
VAL_ 1089 ST_TRM_LVG_DBG 0 "Zustand_Wohnen_oder_hoeher_ist_aktiv" 1 "Wohnen_wurde_aktiv_durch_den_Kunden_beendet" 2 "Wohnen_wurde_nicht_aktiv_durch_den_Kunden_beendet" 15 "Sendefunktion nicht in Betrieb";
VAL_ 1089 ST_COU_CCM 0 "CCM_Zaehlerwert_0" 1 "CCM_Zaehlerwert_1" 2 "CCM_Zaehlerwert_2" 3 "CCM_Zaehlerwert_3" 4 "CCM_Zaehlerwert_4" 5 "CCM_Zaehlerwert_5" 6 "CCM_Zaehlerwert_6" 7 "CCM_Zaehlerwert_7" 8 "CCM_Zaehlerwert_8" 9 "CCM_Zaehlerwert_9" 10 "CCM_Zaehlerwert_10" 11 "CCM_Zaehlerwert_11" 12 "CCM_Zaehlerwert_12" 13 "CCM_Zaehlerwert_13" 14 "CCM_Zaehler_groesser_als_13" 15 "Sendefunktion nicht in Betrieb";
VAL_ 1089 ST_CODG_OSFG 255 "Sendefunktion nicht in Betrieb";
VAL_ 1089 ST_CODG_U_PWF 0 "Keine Abschaltung bei niedriger Batteriespannung" 1 "Kleiner_Gleich_9400_mV" 14 "Groesser_Gleich_10700_mV" 15 "Sendefunktion nicht in Betrieb";
VAL_ 1089 ST_U_BDC 255 "Sendefunktion nicht in Betrieb";
VAL_ 900 ST_AW_SU 0 "Allradmodus 4WD Standard" 1 "Allradmodus 4WD Alternativ" 2 "Allradmodus 2WD" 3 "Allradmodus 4WD Düne; Verwendung ab SP2021" 5 "Hinweis: Reserviert für  funktionale Kennung Signal-Tag." 6 "Hinweis: Reserviert für  funktionale Kennung Signal-Tag." 7 "Sendefunktion nicht in Betrieb";
VAL_ 900 QU_FN_AW 2 "Funktion_verfuegbar_Bereit" 6 "Funktion_nicht_verfuegbar_Fehler" 10 "Kein Wechsel nach Allradmodus 2WD möglich." 14 "Funktionsschnittstelle_ist_nicht_verfuegbar" 15 "Signal_unbefuellt";
VAL_ 900 ST_BRPD_SU 1 "Kennlinie_1" 2 "Kennlinie_2" 3 "Kennlinie_3" 15 "Sendefunktion nicht in Betrieb";
VAL_ 900 QU_FN_BRPD 1 "Funktion_verfuegbar_Bereit" 6 "Sendefunktion in Betrieb, meldet Fehler" 9 "Funktion_verfuegbar_Aktiv" 14 "Sendefunktion in Betrieb, Werte nicht verfügbar" 15 "Sendefunktion nicht in Betrieb";
VAL_ 900 StatusMControlPlusDriftSetup 0 "Nicht_genutzt" 1 "DFT_aus_MCP_aus" 2 "DFT_an_MCP_aus" 3 "DFT_aus_MCP_an" 13 "SIGNALTAG_FCTIF_NOT_AVAILABLE" 14 "SIGNALTAG_FCT_ERROR" 15 "Sendefunktion nicht in Betrieb";
VAL_ 900 StatusDriftSupportLevelSetup 0 "Nicht_genutzt" 1 "Assistenz_Level_0" 2 "Assistenz_Level_1" 3 "Assistenz_Level_2" 4 "Assistenz_Level_3" 5 "Assistenz_Level_4" 6 "Assistenz_Level_5" 7 "Assistenz_Level_6" 8 "Assistenz_Level_7" 9 "Assistenz_Level_8" 10 "Assistenz_Level_9" 11 "Assistenz_Level_10" 13 "SIGNALTAG_FCTIF_NOT_AVAILABLE" 14 "SIGNALTAG_FCT_ERROR" 15 "Sendefunktion nicht in Betrieb";
VAL_ 900 StatusMControlPlusTractionLevelS 0 "Nicht_genutzt" 1 "Traktion_Level_0" 2 "Traktion_Level_1" 3 "Traktion_Level_2" 4 "Traktion_Level_3" 5 "Traktion_Level_4" 6 "Traktion_Level_5" 7 "Traktion_Level_6" 8 "Traktion_Level_7" 9 "Traktion_Level_8" 10 "Traktion_Level_9" 11 "Traktion_Level_10" 13 "SIGNALTAG_FCTIF_NOT_AVAILABLE" 14 "SIGNALTAG_FCT_ERROR" 15 "Sendefunktion nicht in Betrieb";
VAL_ 900 StatusMControlPlusBrakeBalanceLe 0 "Nicht_genutzt" 1 "Bremsbalance_Level_0" 2 "Bremsbalance_Level_1" 3 "Bremsbalance_Level_2" 4 "Bremsbalance_Level_3" 5 "Bremsbalance_Level_4" 6 "Bremsbalance_Level_5" 7 "Bremsbalance_Level_6" 8 "Bremsbalance_Level_7" 9 "Bremsbalance_Level_8" 10 "Bremsbalance_Level_9" 11 "Bremsbalance_Level_10" 13 "SIGNALTAG_FCTIF_NOT_AVAILABLE" 14 "SIGNALTAG_FCT_ERROR" 15 "Sendefunktion nicht in Betrieb";
VAL_ 150 ST_PO_CUOFL_MAB_FLA 0 "Horizontal COL not visible." 1 "Horizontal COL visible." 2 "Reserved" 3 "Signal invalid";
VAL_ 150 ST_HLW_DIPB_FLA 0 "Adaptive Light Control" 1 "Adaptive Light Control" 2 "Reserved" 3 "Signal invalid";
VAL_ 150 ST_PO_CUOFL_LH_MAB_FLA 0 "Glare-free light distribution disabled" 1 "Glare-free light distribution enabled" 2 "Reserved" 3 "Signal invalid";
VAL_ 150 ST_PO_CUOFL_RH_MAB_FLA 0 "Glare-free light distribution disabled" 1 "Glare-free light distribution enabled" 2 "Reserved" 3 "Signal invalid";
VAL_ 150 PO_DIM_1_LH_FLA 253 "Hinweis: Reserviert für funktionale Kennung Signal-Tag." 254 "Hinweis: Reserviert für funktionale Kennung Signal-Tag." 255 "Sendefunktion nicht in Betrieb";
VAL_ 150 PO_DIM_1_RH_FLA 253 "Hinweis: Reserviert für funktionale Kennung Signal-Tag." 254 "Hinweis: Reserviert für funktionale Kennung Signal-Tag." 255 "Sendefunktion nicht in Betrieb";
VAL_ 150 BNDRY_DIM_1_BOT_FLA 61 "Hinweis: Reserviert für funktionale Kennung Signal-Tag." 62 "Hinweis: Reserviert für funktionale Kennung Signal-Tag." 63 "Sendefunktion nicht in Betrieb";
VAL_ 150 ST_DIM_1_FLA 0 "no dimming" 1 "dim level 1" 2 "dim level 2" 3 "Signal_unbefuellt";
VAL_ 798 CTR_PFGS 0 "Abschaltaufforderung" 1 "Einschaltaufforderung" 3 "Signal ungültig";
VAL_ 798 CTR_OPTN_ACTVN_GZA 0 "Abschaltaufforderung" 1 "Einschaltaufforderung" 3 "Signal ungültig";
VAL_ 798 CTR_NIPE 0 "Abschaltaufforderung" 1 "Einschaltaufforderung" 3 "Signal ungültig";
VAL_ 430 ST_LP_SW 1 "Taster-BEL" 2 "Taster-BEL" 3 "Drehschalter-BEL" 7 "Drehschalter-BEL und Taster-BEL" 9 "Standlicht für Drehschalter-BEL und Taster-BEL" 11 "Licht aus für Drehschalter-BEL und Taster-BEL" 12 "Fahrlicht manuell für Drehschalter-BEL und Taster-BEL" 13 "Standlicht für Drehschalter-BEL" 14 "Fahrlicht manuell für Drehschalter-BEL" 15 "Sendefunktion nicht in Betrieb";
VAL_ 430 RCOG_EVT_LP_SW 0 "kein_Event_aktiv" 1 "Parklicht_links" 2 "Parklicht_rechts" 3 "Nebelscheinwerfer" 6 "Nebelschlusslicht" 7 "Stellung_Automatik" 9 "Standlicht" 11 "Licht_aus" 12 "Fahrlicht" 13 "Hinweis: Reserviert für funktionale Kennung Signal-Tag." 14 "Hinweis: Reserviert für funktionale Kennung Signal-Tag." 15 "Sendefunktion nicht in Betrieb";
VAL_ 430 AVAI_LP_SW_PLI_LH 0 "BEL-Zustand Parklicht_links nicht verfügbar in der Fahrzeugkonfiguration." 1 "BEL-Zustand Parklicht_links verfügbar aber nicht bedienbar im aktuellen Fahrzeugzustand." 2 "BEL-Zustand Parklicht_links verfügbar und im aktuellen Fahrzeugzustand bedienbar." 3 "Sendefunktion nicht in Betrieb";
VAL_ 430 AVAI_LP_SW_PLI_RH 0 "BEL-Zustand Parklicht_Rechts nicht verfügbar in der Fahrzeugkonfiguration." 1 "BEL-Zustand Parklicht_Rechts verfügbar aber nicht bedienbar im aktuellen Fahrzeugzustand." 2 "BEL-Zustand Parklicht_Rechts verfügbar und im aktuellen Fahrzeugzustand bedienbar." 3 "Sendefunktion nicht in Betrieb";
VAL_ 430 AVAI_LP_SW_AUT 0 "BEL-Zustand Automatik nicht verfügbar in der Fahrzeugkonfiguration." 1 "BEL-Zustand Automatik verfügbar aber nicht bedienbar im aktuellen Fahrzeugzustand." 2 "BEL-Zustand Automatik verfügbar und im aktuellen Fahrzeugzustand bedienbar." 3 "Sendefunktion nicht in Betrieb";
VAL_ 430 AVAI_LP_SW_LP_OFF 0 "BEL-Zustand Licht_Aus nicht verfügbar in der Fahrzeugkonfiguration." 1 "BEL-Zustand Licht_Aus verfügbar aber nicht bedienbar im aktuellen Fahrzeugzustand." 2 "BEL-Zustand Licht_Aus verfügbar und im aktuellen Fahrzeugzustand bedienbar." 3 "Sendefunktion nicht in Betrieb";
VAL_ 430 AVAI_LP_SW_POLI 0 "BEL-Zustand Standlicht nicht verfügbar in der Fahrzeugkonfiguration." 1 "BEL-Zustand Standlicht verfügbar aber nicht bedienbar im aktuellen Fahrzeugzustand." 2 "BEL-Zustand Standlicht verfügbar und im aktuellen Fahrzeugzustand bedienbar." 3 "Sendefunktion nicht in Betrieb";
VAL_ 430 AVAI_LP_SW_LOWB_MAN 0 "BEL-Zustand Fahrlicht_Manuell nicht verfügbar in der Fahrzeugkonfiguration." 1 "BEL-Zustand Fahrlicht_Manuell verfügbar aber nicht bedienbar im aktuellen Fahrzeugzustand." 2 "BEL-Zustand Fahrlicht_Manuell verfügbar und im aktuellen Fahrzeugzustand bedienbar." 3 "Sendefunktion nicht in Betrieb";
VAL_ 430 AVAI_LP_SW_FFLI 0 "BEL-Zustand Nebelscheinwerfer nicht bedient in der Fahrzeugkonfiguration." 1 "BEL-Zustand Nebelscheinwerfer bedient aber nicht bedienbar im aktuellen Fahrzeugzustand." 2 "BEL-Zustand Nebelscheinwerfer bedient und im aktuellen Fahrzeugzustand bedienbar." 3 "Sendefunktion nicht in Betrieb";
VAL_ 430 AVAI_LP_SW_RFLP 0 "BEL-Zustand Nebelschlußlicht nicht bedient in der Fahrzeugkonfiguration." 1 "BEL-Zustand Nebelschlußlicht bedient aber nicht bedienbar im aktuellen Fahrzeugzustand." 2 "BEL-Zustand Nebelschlußlicht bedient und im aktuellen Fahrzeugzustand bedienbar." 3 "Sendefunktion nicht in Betrieb";
SIG_GROUP_ 628 e2eGrp_ST_CON_SEAT_DRR 1 : ALIV_ST_CON_SEAT_DRR ST_SBIL_DRR ST_SBIL_DRR3 BR_TLT_PO_DRR BR_TLT_PO_DRR3 ST_EMULOK_DRR ST_AD_BOOT_FNS_DRR ST_AD_BOOT_FNS_DRR3 ST_SEAT_EEL_PLCHK_DRR CTR_LED_NAD_TIR_2 CTR_LED_NAD_TIR_3 CTR_LED_NAD_BOOT_FNS ST_CON_SEAT_DRR_dummy_42_55 CRC_ST_CON_SEAT_DRR;
SIG_GROUP_ 629 e2eGrp_ST_CON_SEAT_PSR 1 : ALIV_ST_CON_SEAT_PSR ST_SBIL_PSR ST_SBIL_PSR3 BR_TLT_PO_PSR BR_TLT_PO_PSR3 ST_EMULOK_PSR ST_AD_BOOT_FNS_PSR ST_AD_BOOT_FNS_PSR3 ST_SEAT_EEL_PLCHK_PSR CTR_LED_NAD_TIR_2_PSR CTR_LED_NAD_TIR_3_PSR CTR_LED_NAD_BOOT_FNS_PSR ST_CON_SEAT_PSR_dummy_42_55 CRC_ST_CON_SEAT_PSR;
SIG_GROUP_ 171 e2eGrp_ST_CR 1 : CRC_ST_CR ALIV_ST_CR StatusCrashSeverityLevelNearDepl ST_DEPLOY_AB ST_THRV_ACLN ST_CRSE_FRT ST_CRSE_SIDE_RH ST_CRSE_SIDE_LH ST_CRSE_REAR ST_CRSE_ROV ST_CRSE_PED ST_DMG_HV_SYS StatusCrashSeverityLevelFrontEnv StatusCrashSeverityLevelRearEnvi StatusCrashSeverityLevelSideRigh StatusCrashSeverityLevelSideLeft;
SIG_GROUP_ 768 signalGrp_ST_DIAG_OBD_1_PT 1 : ALIV_ST_DIAG_OBD_1_PT ST_DIAG_OBD_1_PT_MAX_MUX ST_DIAG_OBD_1_PT_IMME_MUX DIAG_ST_OBD_1_PT_1 DIAG_ST_OBD_1_PT_2 DIAG_ST_OBD_1_PT_3 DIAG_ST_OBD_1_PT_4 DIAG_ST_OBD_1_PT_5 DIAG_ST_OBD_1_PT_6 DIAG_ST_OBD_1_PT_7 DIAG_ST_OBD_1_PT_8;
SIG_GROUP_ 983 signalGrp_ST_DIAG_OBD_7_PT 1 : ALIV_ST_DIAG_OBD_7_PT ST_DIAG_OBD_7_PT_MAX_MUX ST_DIAG_OBD_7_PT_IMME_MUX DIAG_ST_OBD_7_PT_1 DIAG_ST_OBD_7_PT_2 DIAG_ST_OBD_7_PT_3 DIAG_ST_OBD_7_PT_4 DIAG_ST_OBD_7_PT_5 DIAG_ST_OBD_7_PT_6 DIAG_ST_OBD_7_PT_7 DIAG_ST_OBD_7_PT_8;
SIG_GROUP_ 991 signalGrp_ST_DIAG_OBD_SLV_1 1 : ALIV_SLV_1_ST_DIAG_OBD SLV_1_ST_DIAG_OBD_MAX_MUX SLV_1_ST_DIAG_OBD_IMME_MUX SLV_1_DIAG_ST_1_OBD SLV_1_DIAG_ST_2_OBD SLV_1_DIAG_ST_3_OBD SLV_1_DIAG_ST_4_OBD SLV_1_DIAG_ST_5_OBD SLV_1_DIAG_ST_6_OBD SLV_1_DIAG_ST_7_OBD SLV_1_DIAG_ST_8_OBD;
SIG_GROUP_ 992 signalGrp_ST_DIAG_OBD_SLV_2 1 : ALIV_SLV_2_ST_DIAG_OBD SLV_2_ST_DIAG_OBD_MAX_MUX SLV_2_ST_DIAG_OBD_IMME_MUX SLV_2_DIAG_ST_1_OBD SLV_2_DIAG_ST_2_OBD SLV_2_DIAG_ST_3_OBD SLV_2_DIAG_ST_4_OBD SLV_2_DIAG_ST_5_OBD SLV_2_DIAG_ST_6_OBD SLV_2_DIAG_ST_7_OBD SLV_2_DIAG_ST_8_OBD;
SIG_GROUP_ 448 e2eGrp_ST_DISP_DRASY 1 : CRC_ST_DISP_DRASY ALIV_ST_DISP_DRASY CHL_ST_DISP_DRASY AVL_V_SPDM_2 UN_V_SPDM ST_DISP_PMA AVAI_DISP_KI ST_DISP_XCC ST_DISP_HDC ST_DISP_SD ST_DISP_DRASY_LAG ST_DISP_ISA_2 ST_DISP_GAP_INFO_2 ST_DISP_WBK;
SIG_GROUP_ 435 signalGrp_ST_DISP_KI 1 : ST_RQ_ACTVN_DYNOMOD ST_DISP_KI_M ST_NO_CC_MESS_DISP ST_DISP_WALI_AB ST_DISP_WALI_BLT ST_DISP_WALI_ENG ST_DISP_IDLI_DSC CHKSM_ST_DISP_KI;
SIG_GROUP_ 100 e2eGrp_ST_DRVG_RDI 1 : CRC_ST_DRVG_RDI ALIV_ST_DRVG_RDI ST_DRVG_RDI_dummy_12_15 ST_DRVG_RDI_DRV ST_DRVG_RDI_dummy_20_31 ST_DRVG_RDI_dummy_32_63;
SIG_GROUP_ 710 e2eGrp_ST_ELV 1 : CRC_ST_ELV ALIV_ST_ELV CHL_ST_ELV ST_ELV_dummy_16_19 ST_CON_ELV ST_ELV_dummy_24_31 ST_ELV_dummy_32_63;
SIG_GROUP_ 407 e2eGrp_ST_GWS 1 : CRC_ST_GWS ALIV_ST_GWS OP_GWS OP_GWS_PUBU_S OP_GWS_PUBU_DRVLG OP_GWS_REL OP_GWS_PUBU_PKG OP_GRSS_PK_1_2 OP_GRSS_PK_2_2 OP_GWS_PUBU_LOW_MOD;
SIG_GROUP_ 900 e2eGrp_ST_MSYS 1 : CRC_StatusMSystem Alive_StatusMSystem CHL_StatusMSystem ST_AW_SU QU_FN_AW ST_MSYS_dummy_23_23 ST_BRPD_SU QU_FN_BRPD StatusMControlPlusDriftSetup StatusDriftSupportLevelSetup StatusMControlPlusTractionLevelS StatusMControlPlusBrakeBalanceLe ST_MSYS_dummy_48_63;
